[part 7 of 11: package /CANAnalyzer/CommunicationClusters]
AUTOSAR XML (schema 00051)
package /CANAnalyzer/CommunicationClusters  (continued)
  can cluster CAN_FD_IPB_41  (continued)
    can physical channel Channel  (continued)
      frame StatusDiagnosticFBD_HL: id 0x286, frame-length=32, can-addressing-mode=STANDARD, can-frame-rx-behavior=CAN-FD, can-frame-tx-behavior=CAN-FD
        pdu StatusDiagnosticFBD_HL: length=32, unused-bit-pattern=0
          signal StatusDiagnosticFBD_HL_BMWPartNumber0: start 0, 8 bit, little-endian, data-type-policy=OVERRIDE, base-type=uint8, compu {phys=raw}, range phys 0..255
          signal StatusDiagnosticFBD_HL_BMWPartNumber1: start 8, 8 bit, little-endian, data-type-policy=OVERRIDE, base-type=uint8, compu {phys=raw}, range phys 0..255
          signal StatusDiagnosticFBD_HL_BMWPartNumber2: start 16, 8 bit, little-endian, data-type-policy=OVERRIDE, base-type=uint8, compu {phys=raw}, range phys 0..255
          signal StatusDiagnosticFBD_HL_BMWPartNumber3: start 24, 8 bit, little-endian, data-type-policy=OVERRIDE, base-type=uint8, compu {phys=raw}, range phys 0..255
          signal StatusDiagnosticFBD_HL_BMWPartNumber4: start 32, 8 bit, little-endian, data-type-policy=OVERRIDE, base-type=uint8, compu {phys=raw}, range phys 0..255
          signal StatusDiagnosticFBD_HL_BMWPartNumber5: start 40, 8 bit, little-endian, data-type-policy=OVERRIDE, base-type=uint8, compu {phys=raw}, range phys 0..255
          signal StatusDiagnosticFBD_HL_BMWPartNumber6: start 48, 8 bit, little-endian, data-type-policy=OVERRIDE, base-type=uint8, compu {phys=raw}, range phys 0..255
          signal StatusDiagnosticFBD_HL_BMWPartNumberAI: start 56, 8 bit, little-endian, data-type-policy=OVERRIDE, base-type=uint8, compu {phys=raw}, range phys 0..255
          signal StatusDiagnosticFBD_HL_HWELMain: start 64, 8 bit, little-endian, data-type-policy=OVERRIDE, base-type=uint8, compu {phys=raw}, range phys 0..252
          signal StatusDiagnosticFBD_HL_HWELMinor: start 72, 8 bit, little-endian, data-type-policy=OVERRIDE, base-type=uint8, compu {phys=raw}, range phys 0..252
          signal StatusDiagnosticFBD_HL_HWELPatch: start 80, 8 bit, little-endian, data-type-policy=OVERRIDE, base-type=uint8, compu {phys=raw}, range phys 0..252
          signal StatusDiagnosticFBD_HL_BLESWFKMain: start 88, 8 bit, little-endian, data-type-policy=OVERRIDE, base-type=uint8, compu {phys=raw}, range phys 0..252
          signal StatusDiagnosticFBD_HL_BLESWFKMinor: start 96, 8 bit, little-endian, data-type-policy=OVERRIDE, base-type=uint8, compu {phys=raw}, range phys 0..252
          signal StatusDiagnosticFBD_HL_BLESWFKPatch: start 104, 8 bit, little-endian, data-type-policy=OVERRIDE, base-type=uint8, compu {phys=raw}, range phys 0..252
          signal StatusDiagnosticFBD_HL_UWBSWFKMain: start 112, 8 bit, little-endian, data-type-policy=OVERRIDE, base-type=uint8, compu {phys=raw}, range phys 0..252
          signal StatusDiagnosticFBD_HL_UWBSWFKMinor: start 120, 8 bit, little-endian, data-type-policy=OVERRIDE, base-type=uint8, compu {phys=raw}, range phys 0..252
          signal StatusDiagnosticFBD_HL_UWBSWFKPatch: start 128, 8 bit, little-endian, data-type-policy=OVERRIDE, base-type=uint8, compu {phys=raw}, range phys 0..252
          signal StatusDiagnosticFBD_HL_BootloaderSWFKMain: start 136, 8 bit, little-endian, data-type-policy=OVERRIDE, base-type=uint8, compu {phys=raw}, range phys 0..252
          signal StatusDiagnosticFBD_HL_BootloaderSWFKMinor: start 144, 8 bit, little-endian, data-type-policy=OVERRIDE, base-type=uint8, compu {phys=raw}, range phys 0..252
          signal StatusDiagnosticFBD_HL_BootloaderSWFKPatch: start 152, 8 bit, little-endian, data-type-policy=OVERRIDE, base-type=uint8, compu {phys=raw}, range phys 0..252
          signal StatusDiagnosticFBD_HL_ProductionDate: start 160, 64 bit, little-endian, data-type-policy=OVERRIDE, base-type=uint64, compu {phys=raw}, range phys 0..18446744073709551612
          signal StatusDiagnosticFBD_HL_SerialNumber: start 224, 32 bit, little-endian, data-type-policy=OVERRIDE, base-type=uint32, compu {phys=raw}, range phys 0..4294967292
      frame StatusDiagnosticFBD_HM: id 0x281, frame-length=32, can-addressing-mode=STANDARD, can-frame-rx-behavior=CAN-FD, can-frame-tx-behavior=CAN-FD
        pdu StatusDiagnosticFBD_HM: length=32, unused-bit-pattern=0
          signal StatusDiagnosticFBD_HM_BMWPartNumber0: start 0, 8 bit, little-endian, data-type-policy=OVERRIDE, base-type=uint8, compu {phys=raw}, range phys 0..255
          signal StatusDiagnosticFBD_HM_BMWPartNumber1: start 8, 8 bit, little-endian, data-type-policy=OVERRIDE, base-type=uint8, compu {phys=raw}, range phys 0..255
          signal StatusDiagnosticFBD_HM_BMWPartNumber2: start 16, 8 bit, little-endian, data-type-policy=OVERRIDE, base-type=uint8, compu {phys=raw}, range phys 0..255
          signal StatusDiagnosticFBD_HM_BMWPartNumber3: start 24, 8 bit, little-endian, data-type-policy=OVERRIDE, base-type=uint8, compu {phys=raw}, range phys 0..255
          signal StatusDiagnosticFBD_HM_BMWPartNumber4: start 32, 8 bit, little-endian, data-type-policy=OVERRIDE, base-type=uint8, compu {phys=raw}, range phys 0..255
          signal StatusDiagnosticFBD_HM_BMWPartNumber5: start 40, 8 bit, little-endian, data-type-policy=OVERRIDE, base-type=uint8, compu {phys=raw}, range phys 0..255
          signal StatusDiagnosticFBD_HM_BMWPartNumber6: start 48, 8 bit, little-endian, data-type-policy=OVERRIDE, base-type=uint8, compu {phys=raw}, range phys 0..255
          signal StatusDiagnosticFBD_HM_BMWPartNumberAI: start 56, 8 bit, little-endian, data-type-policy=OVERRIDE, base-type=uint8, compu {phys=raw}, range phys 0..255
          signal StatusDiagnosticFBD_HM_HWELMain: start 64, 8 bit, little-endian, data-type-policy=OVERRIDE, base-type=uint8, compu {phys=raw}, range phys 0..252
          signal StatusDiagnosticFBD_HM_HWELMinor: start 72, 8 bit, little-endian, data-type-policy=OVERRIDE, base-type=uint8, compu {phys=raw}, range phys 0..252
          signal StatusDiagnosticFBD_HM_HWELPatch: start 80, 8 bit, little-endian, data-type-policy=OVERRIDE, base-type=uint8, compu {phys=raw}, range phys 0..252
          signal StatusDiagnosticFBD_HM_BLESWFKMain: start 88, 8 bit, little-endian, data-type-policy=OVERRIDE, base-type=uint8, compu {phys=raw}, range phys 0..252
          signal StatusDiagnosticFBD_HM_BLESWFKMinor: start 96, 8 bit, little-endian, data-type-policy=OVERRIDE, base-type=uint8, compu {phys=raw}, range phys 0..252
          signal StatusDiagnosticFBD_HM_BLESWFKPatch: start 104, 8 bit, little-endian, data-type-policy=OVERRIDE, base-type=uint8, compu {phys=raw}, range phys 0..252
          signal StatusDiagnosticFBD_HM_UWBSWFKMain: start 112, 8 bit, little-endian, data-type-policy=OVERRIDE, base-type=uint8, compu {phys=raw}, range phys 0..252
          signal StatusDiagnosticFBD_HM_UWBSWFKMinor: start 120, 8 bit, little-endian, data-type-policy=OVERRIDE, base-type=uint8, compu {phys=raw}, range phys 0..252
          signal StatusDiagnosticFBD_HM_UWBSWFKPatch: start 128, 8 bit, little-endian, data-type-policy=OVERRIDE, base-type=uint8, compu {phys=raw}, range phys 0..252
          signal StatusDiagnosticFBD_HM_BootloaderSWFKMain: start 136, 8 bit, little-endian, data-type-policy=OVERRIDE, base-type=uint8, compu {phys=raw}, range phys 0..252
          signal StatusDiagnosticFBD_HM_BootloaderSWFKMinor: start 144, 8 bit, little-endian, data-type-policy=OVERRIDE, base-type=uint8, compu {phys=raw}, range phys 0..252
          signal StatusDiagnosticFBD_HM_BootloaderSWFKPatch: start 152, 8 bit, little-endian, data-type-policy=OVERRIDE, base-type=uint8, compu {phys=raw}, range phys 0..252
          signal StatusDiagnosticFBD_HM_ProductionDate: start 160, 64 bit, little-endian, data-type-policy=OVERRIDE, base-type=uint64, compu {phys=raw}, range phys 0..18446744073709551612
          signal StatusDiagnosticFBD_HM_SerialNumber: start 224, 32 bit, little-endian, data-type-policy=OVERRIDE, base-type=uint32, compu {phys=raw}, range phys 0..4294967292
      frame StatusDiagnosticFBD_HR: id 0x287, frame-length=32, can-addressing-mode=STANDARD, can-frame-rx-behavior=CAN-FD, can-frame-tx-behavior=CAN-FD
        pdu StatusDiagnosticFBD_HR: length=32, unused-bit-pattern=0
          signal StatusDiagnosticFBD_HR_BMWPartNumber0: start 0, 8 bit, little-endian, data-type-policy=OVERRIDE, base-type=uint8, compu {phys=raw}, range phys 0..255
          signal StatusDiagnosticFBD_HR_BMWPartNumber1: start 8, 8 bit, little-endian, data-type-policy=OVERRIDE, base-type=uint8, compu {phys=raw}, range phys 0..255
          signal StatusDiagnosticFBD_HR_BMWPartNumber2: start 16, 8 bit, little-endian, data-type-policy=OVERRIDE, base-type=uint8, compu {phys=raw}, range phys 0..255
          signal StatusDiagnosticFBD_HR_BMWPartNumber3: start 24, 8 bit, little-endian, data-type-policy=OVERRIDE, base-type=uint8, compu {phys=raw}, range phys 0..255
          signal StatusDiagnosticFBD_HR_BMWPartNumber4: start 32, 8 bit, little-endian, data-type-policy=OVERRIDE, base-type=uint8, compu {phys=raw}, range phys 0..255
          signal StatusDiagnosticFBD_HR_BMWPartNumber5: start 40, 8 bit, little-endian, data-type-policy=OVERRIDE, base-type=uint8, compu {phys=raw}, range phys 0..255
          signal StatusDiagnosticFBD_HR_BMWPartNumber6: start 48, 8 bit, little-endian, data-type-policy=OVERRIDE, base-type=uint8, compu {phys=raw}, range phys 0..255
          signal StatusDiagnosticFBD_HR_BMWPartNumberAI: start 56, 8 bit, little-endian, data-type-policy=OVERRIDE, base-type=uint8, compu {phys=raw}, range phys 0..255
          signal StatusDiagnosticFBD_HR_HWELMain: start 64, 8 bit, little-endian, data-type-policy=OVERRIDE, base-type=uint8, compu {phys=raw}, range phys 0..252
          signal StatusDiagnosticFBD_HR_HWELMinor: start 72, 8 bit, little-endian, data-type-policy=OVERRIDE, base-type=uint8, compu {phys=raw}, range phys 0..252
          signal StatusDiagnosticFBD_HR_HWELPatch: start 80, 8 bit, little-endian, data-type-policy=OVERRIDE, base-type=uint8, compu {phys=raw}, range phys 0..252
          signal StatusDiagnosticFBD_HR_BLESWFKMain: start 88, 8 bit, little-endian, data-type-policy=OVERRIDE, base-type=uint8, compu {phys=raw}, range phys 0..252
          signal StatusDiagnosticFBD_HR_BLESWFKMinor: start 96, 8 bit, little-endian, data-type-policy=OVERRIDE, base-type=uint8, compu {phys=raw}, range phys 0..252
          signal StatusDiagnosticFBD_HR_BLESWFKPatch: start 104, 8 bit, little-endian, data-type-policy=OVERRIDE, base-type=uint8, compu {phys=raw}, range phys 0..252
          signal StatusDiagnosticFBD_HR_UWBSWFKMain: start 112, 8 bit, little-endian, data-type-policy=OVERRIDE, base-type=uint8, compu {phys=raw}, range phys 0..252
          signal StatusDiagnosticFBD_HR_UWBSWFKMinor: start 120, 8 bit, little-endian, data-type-policy=OVERRIDE, base-type=uint8, compu {phys=raw}, range phys 0..252
          signal StatusDiagnosticFBD_HR_UWBSWFKPatch: start 128, 8 bit, little-endian, data-type-policy=OVERRIDE, base-type=uint8, compu {phys=raw}, range phys 0..252
          signal StatusDiagnosticFBD_HR_BootloaderSWFKMain: start 136, 8 bit, little-endian, data-type-policy=OVERRIDE, base-type=uint8, compu {phys=raw}, range phys 0..252
          signal StatusDiagnosticFBD_HR_BootloaderSWFKMinor: start 144, 8 bit, little-endian, data-type-policy=OVERRIDE, base-type=uint8, compu {phys=raw}, range phys 0..252
          signal StatusDiagnosticFBD_HR_BootloaderSWFKPatch: start 152, 8 bit, little-endian, data-type-policy=OVERRIDE, base-type=uint8, compu {phys=raw}, range phys 0..252
          signal StatusDiagnosticFBD_HR_ProductionDate: start 160, 64 bit, little-endian, data-type-policy=OVERRIDE, base-type=uint64, compu {phys=raw}, range phys 0..18446744073709551612
          signal StatusDiagnosticFBD_HR_SerialNumber: start 224, 32 bit, little-endian, data-type-policy=OVERRIDE, base-type=uint32, compu {phys=raw}, range phys 0..4294967292
      frame StatusDiagnosticFBD_Miko: id 0x282, frame-length=32, can-addressing-mode=STANDARD, can-frame-rx-behavior=CAN-FD, can-frame-tx-behavior=CAN-FD
        pdu StatusDiagnosticFBD_Miko: length=32, unused-bit-pattern=0
          signal StatusDiagnosticFBD_Miko_BMWPartNumber0: start 0, 8 bit, little-endian, data-type-policy=OVERRIDE, base-type=uint8, compu {phys=raw}, range phys 0..255
          signal StatusDiagnosticFBD_Miko_BMWPartNumber1: start 8, 8 bit, little-endian, data-type-policy=OVERRIDE, base-type=uint8, compu {phys=raw}, range phys 0..255
          signal StatusDiagnosticFBD_Miko_BMWPartNumber2: start 16, 8 bit, little-endian, data-type-policy=OVERRIDE, base-type=uint8, compu {phys=raw}, range phys 0..255
          signal StatusDiagnosticFBD_Miko_BMWPartNumber3: start 24, 8 bit, little-endian, data-type-policy=OVERRIDE, base-type=uint8, compu {phys=raw}, range phys 0..255
          signal StatusDiagnosticFBD_Miko_BMWPartNumber4: start 32, 8 bit, little-endian, data-type-policy=OVERRIDE, base-type=uint8, compu {phys=raw}, range phys 0..255
          signal StatusDiagnosticFBD_Miko_BMWPartNumber5: start 40, 8 bit, little-endian, data-type-policy=OVERRIDE, base-type=uint8, compu {phys=raw}, range phys 0..255
          signal StatusDiagnosticFBD_Miko_BMWPartNumber6: start 48, 8 bit, little-endian, data-type-policy=OVERRIDE, base-type=uint8, compu {phys=raw}, range phys 0..255
          signal StatusDiagnosticFBD_Miko_BMWPartNumberAI: start 56, 8 bit, little-endian, data-type-policy=OVERRIDE, base-type=uint8, compu {phys=raw}, range phys 0..255
          signal StatusDiagnosticFBD_Miko_HWELMain: start 64, 8 bit, little-endian, data-type-policy=OVERRIDE, base-type=uint8, compu {phys=raw}, range phys 0..252
          signal StatusDiagnosticFBD_Miko_HWELMinor: start 72, 8 bit, little-endian, data-type-policy=OVERRIDE, base-type=uint8, compu {phys=raw}, range phys 0..252
          signal StatusDiagnosticFBD_Miko_HWELPatch: start 80, 8 bit, little-endian, data-type-policy=OVERRIDE, base-type=uint8, compu {phys=raw}, range phys 0..252
          signal StatusDiagnosticFBD_Miko_BLESWFKMain: start 88, 8 bit, little-endian, data-type-policy=OVERRIDE, base-type=uint8, compu {phys=raw}, range phys 0..252
          signal StatusDiagnosticFBD_Miko_BLESWFKMinor: start 96, 8 bit, little-endian, data-type-policy=OVERRIDE, base-type=uint8, compu {phys=raw}, range phys 0..252
          signal StatusDiagnosticFBD_Miko_BLESWFKPatch: start 104, 8 bit, little-endian, data-type-policy=OVERRIDE, base-type=uint8, compu {phys=raw}, range phys 0..252
          signal StatusDiagnosticFBD_Miko_UWBSWFKMain: start 112, 8 bit, little-endian, data-type-policy=OVERRIDE, base-type=uint8, compu {phys=raw}, range phys 0..252
          signal StatusDiagnosticFBD_Miko_UWBSWFKMinor: start 120, 8 bit, little-endian, data-type-policy=OVERRIDE, base-type=uint8, compu {phys=raw}, range phys 0..252
          signal StatusDiagnosticFBD_Miko_UWBSWFKPatch: start 128, 8 bit, little-endian, data-type-policy=OVERRIDE, base-type=uint8, compu {phys=raw}, range phys 0..252
          signal StatusDiagnosticFBD_Miko_BootloaderSWFKMain: start 136, 8 bit, little-endian, data-type-policy=OVERRIDE, base-type=uint8, compu {phys=raw}, range phys 0..252
          signal StatusDiagnosticFBD_Miko_BootloaderSWFKMinor: start 144, 8 bit, little-endian, data-type-policy=OVERRIDE, base-type=uint8, compu {phys=raw}, range phys 0..252
          signal StatusDiagnosticFBD_Miko_BootloaderSWFKPatch: start 152, 8 bit, little-endian, data-type-policy=OVERRIDE, base-type=uint8, compu {phys=raw}, range phys 0..252
          signal StatusDiagnosticFBD_Miko_ProductionDate: start 160, 64 bit, little-endian, data-type-policy=OVERRIDE, base-type=uint64, compu {phys=raw}, range phys 0..18446744073709551612
          signal StatusDiagnosticFBD_Miko_SerialNumber: start 224, 32 bit, little-endian, data-type-policy=OVERRIDE, base-type=uint32, compu {phys=raw}, range phys 0..4294967292
      frame StatusDiagnosticFBD_MM: id 0x360, frame-length=32, can-addressing-mode=STANDARD, can-frame-rx-behavior=CAN-FD, can-frame-tx-behavior=CAN-FD
        pdu StatusDiagnosticFBD_MM: length=32, unused-bit-pattern=0
          signal StatusDiagnosticFBD_MM_BMWPartNumber0: start 0, 8 bit, little-endian, data-type-policy=OVERRIDE, base-type=uint8, compu {phys=raw}, range phys 0..255
          signal StatusDiagnosticFBD_MM_BMWPartNumber1: start 8, 8 bit, little-endian, data-type-policy=OVERRIDE, base-type=uint8, compu {phys=raw}, range phys 0..255
          signal StatusDiagnosticFBD_MM_BMWPartNumber2: start 16, 8 bit, little-endian, data-type-policy=OVERRIDE, base-type=uint8, compu {phys=raw}, range phys 0..255
          signal StatusDiagnosticFBD_MM_BMWPartNumber3: start 24, 8 bit, little-endian, data-type-policy=OVERRIDE, base-type=uint8, compu {phys=raw}, range phys 0..255
          signal StatusDiagnosticFBD_MM_BMWPartNumber4: start 32, 8 bit, little-endian, data-type-policy=OVERRIDE, base-type=uint8, compu {phys=raw}, range phys 0..255
          signal StatusDiagnosticFBD_MM_BMWPartNumber5: start 40, 8 bit, little-endian, data-type-policy=OVERRIDE, base-type=uint8, compu {phys=raw}, range phys 0..255
          signal StatusDiagnosticFBD_MM_BMWPartNumber6: start 48, 8 bit, little-endian, data-type-policy=OVERRIDE, base-type=uint8, compu {phys=raw}, range phys 0..255
          signal StatusDiagnosticFBD_MM_BMWPartNumberAI: start 56, 8 bit, little-endian, data-type-policy=OVERRIDE, base-type=uint8, compu {phys=raw}, range phys 0..255
          signal StatusDiagnosticFBD_MM_HWELMain: start 64, 8 bit, little-endian, data-type-policy=OVERRIDE, base-type=uint8, compu {phys=raw}, range phys 0..252
          signal StatusDiagnosticFBD_MM_HWELMinor: start 72, 8 bit, little-endian, data-type-policy=OVERRIDE, base-type=uint8, compu {phys=raw}, range phys 0..252
          signal StatusDiagnosticFBD_MM_HWELPatch: start 80, 8 bit, little-endian, data-type-policy=OVERRIDE, base-type=uint8, compu {phys=raw}, range phys 0..252
          signal StatusDiagnosticFBD_MM_BLESWFKMain: start 88, 8 bit, little-endian, data-type-policy=OVERRIDE, base-type=uint8, compu {phys=raw}, range phys 0..252
          signal StatusDiagnosticFBD_MM_BLESWFKMinor: start 96, 8 bit, little-endian, data-type-policy=OVERRIDE, base-type=uint8, compu {phys=raw}, range phys 0..252
          signal StatusDiagnosticFBD_MM_BLESWFKPatch: start 104, 8 bit, little-endian, data-type-policy=OVERRIDE, base-type=uint8, compu {phys=raw}, range phys 0..252
          signal StatusDiagnosticFBD_MM_UWBSWFKMain: start 112, 8 bit, little-endian, data-type-policy=OVERRIDE, base-type=uint8, compu {phys=raw}, range phys 0..252
          signal StatusDiagnosticFBD_MM_UWBSWFKMinor: start 120, 8 bit, little-endian, data-type-policy=OVERRIDE, base-type=uint8, compu {phys=raw}, range phys 0..252
          signal StatusDiagnosticFBD_MM_UWBSWFKPatch: start 128, 8 bit, little-endian, data-type-policy=OVERRIDE, base-type=uint8, compu {phys=raw}, range phys 0..252
          signal StatusDiagnosticFBD_MM_BootloaderSWFKMain: start 136, 8 bit, little-endian, data-type-policy=OVERRIDE, base-type=uint8, compu {phys=raw}, range phys 0..252
          signal StatusDiagnosticFBD_MM_BootloaderSWFKMinor: start 144, 8 bit, little-endian, data-type-policy=OVERRIDE, base-type=uint8, compu {phys=raw}, range phys 0..252
          signal StatusDiagnosticFBD_MM_BootloaderSWFKPatch: start 152, 8 bit, little-endian, data-type-policy=OVERRIDE, base-type=uint8, compu {phys=raw}, range phys 0..252
          signal StatusDiagnosticFBD_MM_ProductionDate: start 160, 64 bit, little-endian, data-type-policy=OVERRIDE, base-type=uint64, compu {phys=raw}, range phys 0..18446744073709551612
          signal StatusDiagnosticFBD_MM_SerialNumber: start 224, 32 bit, little-endian, data-type-policy=OVERRIDE, base-type=uint32, compu {phys=raw}, range phys 0..4294967292
      frame StatusDiagnosticFBD_Trunk: id 0x283, frame-length=32, can-addressing-mode=STANDARD, can-frame-rx-behavior=CAN-FD, can-frame-tx-behavior=CAN-FD
        pdu StatusDiagnosticFBD_Trunk: length=32, unused-bit-pattern=0
          signal StatusDiagnosticFBD_Trunk_BMWPartNumber0: start 0, 8 bit, little-endian, data-type-policy=OVERRIDE, base-type=uint8, compu {phys=raw}, range phys 0..255
          signal StatusDiagnosticFBD_Trunk_BMWPartNumber1: start 8, 8 bit, little-endian, data-type-policy=OVERRIDE, base-type=uint8, compu {phys=raw}, range phys 0..255
          signal StatusDiagnosticFBD_Trunk_BMWPartNumber2: start 16, 8 bit, little-endian, data-type-policy=OVERRIDE, base-type=uint8, compu {phys=raw}, range phys 0..255
          signal StatusDiagnosticFBD_Trunk_BMWPartNumber3: start 24, 8 bit, little-endian, data-type-policy=OVERRIDE, base-type=uint8, compu {phys=raw}, range phys 0..255
          signal StatusDiagnosticFBD_Trunk_BMWPartNumber4: start 32, 8 bit, little-endian, data-type-policy=OVERRIDE, base-type=uint8, compu {phys=raw}, range phys 0..255
          signal StatusDiagnosticFBD_Trunk_BMWPartNumber5: start 40, 8 bit, little-endian, data-type-policy=OVERRIDE, base-type=uint8, compu {phys=raw}, range phys 0..255
          signal StatusDiagnosticFBD_Trunk_BMWPartNumber6: start 48, 8 bit, little-endian, data-type-policy=OVERRIDE, base-type=uint8, compu {phys=raw}, range phys 0..255
          signal StatusDiagnosticFBD_Trunk_BMWPartNumberAI: start 56, 8 bit, little-endian, data-type-policy=OVERRIDE, base-type=uint8, compu {phys=raw}, range phys 0..255
          signal StatusDiagnosticFBD_Trunk_HWELMain: start 64, 8 bit, little-endian, data-type-policy=OVERRIDE, base-type=uint8, compu {phys=raw}, range phys 0..252
          signal StatusDiagnosticFBD_Trunk_HWELMinor: start 72, 8 bit, little-endian, data-type-policy=OVERRIDE, base-type=uint8, compu {phys=raw}, range phys 0..252
          signal StatusDiagnosticFBD_Trunk_HWELPatch: start 80, 8 bit, little-endian, data-type-policy=OVERRIDE, base-type=uint8, compu {phys=raw}, range phys 0..252
          signal StatusDiagnosticFBD_Trunk_BLESWFKMain: start 88, 8 bit, little-endian, data-type-policy=OVERRIDE, base-type=uint8, compu {phys=raw}, range phys 0..252
          signal StatusDiagnosticFBD_Trunk_BLESWFKMinor: start 96, 8 bit, little-endian, data-type-policy=OVERRIDE, base-type=uint8, compu {phys=raw}, range phys 0..252
          signal StatusDiagnosticFBD_Trunk_BLESWFKPatch: start 104, 8 bit, little-endian, data-type-policy=OVERRIDE, base-type=uint8, compu {phys=raw}, range phys 0..252
          signal StatusDiagnosticFBD_Trunk_UWBSWFKMain: start 112, 8 bit, little-endian, data-type-policy=OVERRIDE, base-type=uint8, compu {phys=raw}, range phys 0..252
          signal StatusDiagnosticFBD_Trunk_UWBSWFKMinor: start 120, 8 bit, little-endian, data-type-policy=OVERRIDE, base-type=uint8, compu {phys=raw}, range phys 0..252
          signal StatusDiagnosticFBD_Trunk_UWBSWFKPatch: start 128, 8 bit, little-endian, data-type-policy=OVERRIDE, base-type=uint8, compu {phys=raw}, range phys 0..252
          signal StatusDiagnosticFBD_Trunk_BootloaderSWFKMain: start 136, 8 bit, little-endian, data-type-policy=OVERRIDE, base-type=uint8, compu {phys=raw}, range phys 0..252
          signal StatusDiagnosticFBD_Trunk_BootloaderSWFKMinor: start 144, 8 bit, little-endian, data-type-policy=OVERRIDE, base-type=uint8, compu {phys=raw}, range phys 0..252
          signal StatusDiagnosticFBD_Trunk_BootloaderSWFKPatch: start 152, 8 bit, little-endian, data-type-policy=OVERRIDE, base-type=uint8, compu {phys=raw}, range phys 0..252
          signal StatusDiagnosticFBD_Trunk_ProductionDate: start 160, 64 bit, little-endian, data-type-policy=OVERRIDE, base-type=uint64, compu {phys=raw}, range phys 0..18446744073709551612
          signal StatusDiagnosticFBD_Trunk_SerialNumber: start 224, 32 bit, little-endian, data-type-policy=OVERRIDE, base-type=uint32, compu {phys=raw}, range phys 0..4294967292
      frame StatusDiagnosticFBD_VL: id 0x284, frame-length=32, can-addressing-mode=STANDARD, can-frame-rx-behavior=CAN-FD, can-frame-tx-behavior=CAN-FD
        pdu StatusDiagnosticFBD_VL: length=32, unused-bit-pattern=0
          signal StatusDiagnosticFBD_VL_BMWPartNumber0: start 0, 8 bit, little-endian, data-type-policy=OVERRIDE, base-type=uint8, compu {phys=raw}, range phys 0..255
          signal StatusDiagnosticFBD_VL_BMWPartNumber1: start 8, 8 bit, little-endian, data-type-policy=OVERRIDE, base-type=uint8, compu {phys=raw}, range phys 0..255
          signal StatusDiagnosticFBD_VL_BMWPartNumber2: start 16, 8 bit, little-endian, data-type-policy=OVERRIDE, base-type=uint8, compu {phys=raw}, range phys 0..255
          signal StatusDiagnosticFBD_VL_BMWPartNumber3: start 24, 8 bit, little-endian, data-type-policy=OVERRIDE, base-type=uint8, compu {phys=raw}, range phys 0..255
          signal StatusDiagnosticFBD_VL_BMWPartNumber4: start 32, 8 bit, little-endian, data-type-policy=OVERRIDE, base-type=uint8, compu {phys=raw}, range phys 0..255
          signal StatusDiagnosticFBD_VL_BMWPartNumber5: start 40, 8 bit, little-endian, data-type-policy=OVERRIDE, base-type=uint8, compu {phys=raw}, range phys 0..255
          signal StatusDiagnosticFBD_VL_BMWPartNumber6: start 48, 8 bit, little-endian, data-type-policy=OVERRIDE, base-type=uint8, compu {phys=raw}, range phys 0..255
          signal StatusDiagnosticFBD_VL_BMWPartNumberAI: start 56, 8 bit, little-endian, data-type-policy=OVERRIDE, base-type=uint8, compu {phys=raw}, range phys 0..255
          signal StatusDiagnosticFBD_VL_HWELMain: start 64, 8 bit, little-endian, data-type-policy=OVERRIDE, base-type=uint8, compu {phys=raw}, range phys 0..252
          signal StatusDiagnosticFBD_VL_HWELMinor: start 72, 8 bit, little-endian, data-type-policy=OVERRIDE, base-type=uint8, compu {phys=raw}, range phys 0..252
          signal StatusDiagnosticFBD_VL_HWELPatch: start 80, 8 bit, little-endian, data-type-policy=OVERRIDE, base-type=uint8, compu {phys=raw}, range phys 0..252
          signal StatusDiagnosticFBD_VL_BLESWFKMain: start 88, 8 bit, little-endian, data-type-policy=OVERRIDE, base-type=uint8, compu {phys=raw}, range phys 0..252
          signal StatusDiagnosticFBD_VL_BLESWFKMinor: start 96, 8 bit, little-endian, data-type-policy=OVERRIDE, base-type=uint8, compu {phys=raw}, range phys 0..252
          signal StatusDiagnosticFBD_VL_BLESWFKPatch: start 104, 8 bit, little-endian, data-type-policy=OVERRIDE, base-type=uint8, compu {phys=raw}, range phys 0..252
          signal StatusDiagnosticFBD_VL_UWBSWFKMain: start 112, 8 bit, little-endian, data-type-policy=OVERRIDE, base-type=uint8, compu {phys=raw}, range phys 0..252
          signal StatusDiagnosticFBD_VL_UWBSWFKMinor: start 120, 8 bit, little-endian, data-type-policy=OVERRIDE, base-type=uint8, compu {phys=raw}, range phys 0..252
          signal StatusDiagnosticFBD_VL_UWBSWFKPatch: start 128, 8 bit, little-endian, data-type-policy=OVERRIDE, base-type=uint8, compu {phys=raw}, range phys 0..252
          signal StatusDiagnosticFBD_VL_BootloaderSWFKMain: start 136, 8 bit, little-endian, data-type-policy=OVERRIDE, base-type=uint8, compu {phys=raw}, range phys 0..252
          signal StatusDiagnosticFBD_VL_BootloaderSWFKMinor: start 144, 8 bit, little-endian, data-type-policy=OVERRIDE, base-type=uint8, compu {phys=raw}, range phys 0..252
          signal StatusDiagnosticFBD_VL_BootloaderSWFKPatch: start 152, 8 bit, little-endian, data-type-policy=OVERRIDE, base-type=uint8, compu {phys=raw}, range phys 0..252
          signal StatusDiagnosticFBD_VL_ProductionDate: start 160, 64 bit, little-endian, data-type-policy=OVERRIDE, base-type=uint64, compu {phys=raw}, range phys 0..18446744073709551612
          signal StatusDiagnosticFBD_VL_SerialNumber: start 224, 32 bit, little-endian, data-type-policy=OVERRIDE, base-type=uint32, compu {phys=raw}, range phys 0..4294967292
      frame StatusDiagnosticFBD_VM: id 0x280, frame-length=32, can-addressing-mode=STANDARD, can-frame-rx-behavior=CAN-FD, can-frame-tx-behavior=CAN-FD
        pdu StatusDiagnosticFBD_VM: length=32, unused-bit-pattern=0
          signal StatusDiagnosticFBD_VM_BMWPartNumber0: start 0, 8 bit, little-endian, data-type-policy=OVERRIDE, base-type=uint8, compu {phys=raw}, range phys 0..255
          signal StatusDiagnosticFBD_VM_BMWPartNumber1: start 8, 8 bit, little-endian, data-type-policy=OVERRIDE, base-type=uint8, compu {phys=raw}, range phys 0..255
          signal StatusDiagnosticFBD_VM_BMWPartNumber2: start 16, 8 bit, little-endian, data-type-policy=OVERRIDE, base-type=uint8, compu {phys=raw}, range phys 0..255
          signal StatusDiagnosticFBD_VM_BMWPartNumber3: start 24, 8 bit, little-endian, data-type-policy=OVERRIDE, base-type=uint8, compu {phys=raw}, range phys 0..255
          signal StatusDiagnosticFBD_VM_BMWPartNumber4: start 32, 8 bit, little-endian, data-type-policy=OVERRIDE, base-type=uint8, compu {phys=raw}, range phys 0..255
          signal StatusDiagnosticFBD_VM_BMWPartNumber5: start 40, 8 bit, little-endian, data-type-policy=OVERRIDE, base-type=uint8, compu {phys=raw}, range phys 0..255
          signal StatusDiagnosticFBD_VM_BMWPartNumber6: start 48, 8 bit, little-endian, data-type-policy=OVERRIDE, base-type=uint8, compu {phys=raw}, range phys 0..255
          signal StatusDiagnosticFBD_VM_BMWPartNumberAI: start 56, 8 bit, little-endian, data-type-policy=OVERRIDE, base-type=uint8, compu {phys=raw}, range phys 0..255
          signal StatusDiagnosticFBD_VM_HWELMain: start 64, 8 bit, little-endian, data-type-policy=OVERRIDE, base-type=uint8, compu {phys=raw}, range phys 0..252
          signal StatusDiagnosticFBD_VM_HWELMinor: start 72, 8 bit, little-endian, data-type-policy=OVERRIDE, base-type=uint8, compu {phys=raw}, range phys 0..252
          signal StatusDiagnosticFBD_VM_HWELPatch: start 80, 8 bit, little-endian, data-type-policy=OVERRIDE, base-type=uint8, compu {phys=raw}, range phys 0..252
          signal StatusDiagnosticFBD_VM_BLESWFKMain: start 88, 8 bit, little-endian, data-type-policy=OVERRIDE, base-type=uint8, compu {phys=raw}, range phys 0..252
          signal StatusDiagnosticFBD_VM_BLESWFKMinor: start 96, 8 bit, little-endian, data-type-policy=OVERRIDE, base-type=uint8, compu {phys=raw}, range phys 0..252
          signal StatusDiagnosticFBD_VM_BLESWFKPatch: start 104, 8 bit, little-endian, data-type-policy=OVERRIDE, base-type=uint8, compu {phys=raw}, range phys 0..252
          signal StatusDiagnosticFBD_VM_UWBSWFKMain: start 112, 8 bit, little-endian, data-type-policy=OVERRIDE, base-type=uint8, compu {phys=raw}, range phys 0..252
          signal StatusDiagnosticFBD_VM_UWBSWFKMinor: start 120, 8 bit, little-endian, data-type-policy=OVERRIDE, base-type=uint8, compu {phys=raw}, range phys 0..252
          signal StatusDiagnosticFBD_VM_UWBSWFKPatch: start 128, 8 bit, little-endian, data-type-policy=OVERRIDE, base-type=uint8, compu {phys=raw}, range phys 0..252
          signal StatusDiagnosticFBD_VM_BootloaderSWFKMain: start 136, 8 bit, little-endian, data-type-policy=OVERRIDE, base-type=uint8, compu {phys=raw}, range phys 0..252
          signal StatusDiagnosticFBD_VM_BootloaderSWFKMinor: start 144, 8 bit, little-endian, data-type-policy=OVERRIDE, base-type=uint8, compu {phys=raw}, range phys 0..252
          signal StatusDiagnosticFBD_VM_BootloaderSWFKPatch: start 152, 8 bit, little-endian, data-type-policy=OVERRIDE, base-type=uint8, compu {phys=raw}, range phys 0..252
          signal StatusDiagnosticFBD_VM_ProductionDate: start 160, 64 bit, little-endian, data-type-policy=OVERRIDE, base-type=uint64, compu {phys=raw}, range phys 0..18446744073709551612
          signal StatusDiagnosticFBD_VM_SerialNumber: start 224, 32 bit, little-endian, data-type-policy=OVERRIDE, base-type=uint32, compu {phys=raw}, range phys 0..4294967292
      frame StatusDiagnosticFBD_VR: id 0x285, frame-length=32, can-addressing-mode=STANDARD, can-frame-rx-behavior=CAN-FD, can-frame-tx-behavior=CAN-FD
        pdu StatusDiagnosticFBD_VR: length=32, unused-bit-pattern=0
          signal StatusDiagnosticFBD_VR_BMWPartNumber0: start 0, 8 bit, little-endian, data-type-policy=OVERRIDE, base-type=uint8, compu {phys=raw}, range phys 0..255
          signal StatusDiagnosticFBD_VR_BMWPartNumber1: start 8, 8 bit, little-endian, data-type-policy=OVERRIDE, base-type=uint8, compu {phys=raw}, range phys 0..255
          signal StatusDiagnosticFBD_VR_BMWPartNumber2: start 16, 8 bit, little-endian, data-type-policy=OVERRIDE, base-type=uint8, compu {phys=raw}, range phys 0..255
          signal StatusDiagnosticFBD_VR_BMWPartNumber3: start 24, 8 bit, little-endian, data-type-policy=OVERRIDE, base-type=uint8, compu {phys=raw}, range phys 0..255
          signal StatusDiagnosticFBD_VR_BMWPartNumber4: start 32, 8 bit, little-endian, data-type-policy=OVERRIDE, base-type=uint8, compu {phys=raw}, range phys 0..255
          signal StatusDiagnosticFBD_VR_BMWPartNumber5: start 40, 8 bit, little-endian, data-type-policy=OVERRIDE, base-type=uint8, compu {phys=raw}, range phys 0..255
          signal StatusDiagnosticFBD_VR_BMWPartNumber6: start 48, 8 bit, little-endian, data-type-policy=OVERRIDE, base-type=uint8, compu {phys=raw}, range phys 0..255
          signal StatusDiagnosticFBD_VR_BMWPartNumberAI: start 56, 8 bit, little-endian, data-type-policy=OVERRIDE, base-type=uint8, compu {phys=raw}, range phys 0..255
          signal StatusDiagnosticFBD_VR_HWELMain: start 64, 8 bit, little-endian, data-type-policy=OVERRIDE, base-type=uint8, compu {phys=raw}, range phys 0..252
          signal StatusDiagnosticFBD_VR_HWELMinor: start 72, 8 bit, little-endian, data-type-policy=OVERRIDE, base-type=uint8, compu {phys=raw}, range phys 0..252
          signal StatusDiagnosticFBD_VR_HWELPatch: start 80, 8 bit, little-endian, data-type-policy=OVERRIDE, base-type=uint8, compu {phys=raw}, range phys 0..252
          signal StatusDiagnosticFBD_VR_BLESWFKMain: start 88, 8 bit, little-endian, data-type-policy=OVERRIDE, base-type=uint8, compu {phys=raw}, range phys 0..252
          signal StatusDiagnosticFBD_VR_BLESWFKMinor: start 96, 8 bit, little-endian, data-type-policy=OVERRIDE, base-type=uint8, compu {phys=raw}, range phys 0..252
          signal StatusDiagnosticFBD_VR_BLESWFKPatch: start 104, 8 bit, little-endian, data-type-policy=OVERRIDE, base-type=uint8, compu {phys=raw}, range phys 0..252
          signal StatusDiagnosticFBD_VR_UWBSWFKMain: start 112, 8 bit, little-endian, data-type-policy=OVERRIDE, base-type=uint8, compu {phys=raw}, range phys 0..252
          signal StatusDiagnosticFBD_VR_UWBSWFKMinor: start 120, 8 bit, little-endian, data-type-policy=OVERRIDE, base-type=uint8, compu {phys=raw}, range phys 0..252
          signal StatusDiagnosticFBD_VR_UWBSWFKPatch: start 128, 8 bit, little-endian, data-type-policy=OVERRIDE, base-type=uint8, compu {phys=raw}, range phys 0..252
          signal StatusDiagnosticFBD_VR_BootloaderSWFKMain: start 136, 8 bit, little-endian, data-type-policy=OVERRIDE, base-type=uint8, compu {phys=raw}, range phys 0..252
          signal StatusDiagnosticFBD_VR_BootloaderSWFKMinor: start 144, 8 bit, little-endian, data-type-policy=OVERRIDE, base-type=uint8, compu {phys=raw}, range phys 0..252
          signal StatusDiagnosticFBD_VR_BootloaderSWFKPatch: start 152, 8 bit, little-endian, data-type-policy=OVERRIDE, base-type=uint8, compu {phys=raw}, range phys 0..252
          signal StatusDiagnosticFBD_VR_ProductionDate: start 160, 64 bit, little-endian, data-type-policy=OVERRIDE, base-type=uint64, compu {phys=raw}, range phys 0..18446744073709551612
          signal StatusDiagnosticFBD_VR_SerialNumber: start 224, 32 bit, little-endian, data-type-policy=OVERRIDE, base-type=uint32, compu {phys=raw}, range phys 0..4294967292
      frame StatusFBD_HL: id 0x9C, frame-length=32, can-addressing-mode=STANDARD, can-frame-rx-behavior=CAN-FD, can-frame-tx-behavior=CAN-FD
        pdu StatusFBD_HL: length=32, unused-bit-pattern=0
          signal StatusFBD_HL_PowerMode: start 0, 8 bit, little-endian, data-type-policy=OVERRIDE, compu {phys=raw}
          signal StatusFBD_HL_ResetState: start 8, 8 bit, little-endian, data-type-policy=OVERRIDE, base-type=uint8, compu {phys=raw}, range phys 0..252
          signal StatusFBD_HL_ResetReason: start 16, 8 bit, little-endian, data-type-policy=OVERRIDE, base-type=uint8, compu {phys=raw}, range phys 0..252
          signal StatusFBD_HL_BLEStatus: start 24, 8 bit, little-endian, data-type-policy=OVERRIDE, compu {phys=raw}
          signal StatusFBD_HL_UWBStatus: start 32, 8 bit, little-endian, data-type-policy=OVERRIDE, compu {phys=raw}
          signal StatusFBD_HL_WakeUpReason: start 40, 8 bit, little-endian, data-type-policy=OVERRIDE, compu {phys=raw}
          signal StatusFBD_HL_IRKListIndexWakeUpTrigger: start 48, 8 bit, little-endian, data-type-policy=OVERRIDE, base-type=uint8, compu {phys=raw}, range phys 0..252
          signal StatusFBD_HL_Temperature: start 56, 8 bit, little-endian, data-type-policy=OVERRIDE, base-type=uint8, compu {phys=raw-100; unit °C}, range phys -100..150
          signal StatusFBD_HL_BLENumberOfBonding: start 64, 8 bit, little-endian, data-type-policy=OVERRIDE, base-type=uint8, compu {phys=raw}, range phys 0..252
          signal StatusFBD_HL_BLENumberActiveConnections: start 72, 8 bit, little-endian, data-type-policy=OVERRIDE, base-type=uint8, compu {phys=raw}, range phys 0..252
          signal StatusFBD_HL_BLEChipPowerOnResetCounter: start 80, 8 bit, little-endian, data-type-policy=OVERRIDE, base-type=uint8, compu {phys=raw}, range phys 0..252
          signal StatusFBD_HL_BLEChipSWResetCounter: start 88, 8 bit, little-endian, data-type-policy=OVERRIDE, base-type=uint8, compu {phys=raw}, range phys 0..252
          signal StatusFBD_HL_BLEChipWatchdogCounter: start 96, 8 bit, little-endian, data-type-policy=OVERRIDE, base-type=uint8, compu {phys=raw}, range phys 0..252
          signal StatusFBD_HL_BLEChipTemperaturePrewarningCounter: start 104, 8 bit, little-endian, data-type-policy=OVERRIDE, base-type=uint8, compu {phys=raw}, range phys 0..252
          signal StatusFBD_HL_BLEChipThermalShutdownCounter: start 112, 8 bit, little-endian, data-type-policy=OVERRIDE, base-type=uint8, compu {phys=raw}, range phys 0..252
          signal StatusFBD_HL_BLEChipErrorState: start 120, 8 bit, little-endian, data-type-policy=OVERRIDE, compu {phys=raw}
          signal StatusFBD_HL_UWBChipPowerOnResetCounter: start 128, 8 bit, little-endian, data-type-policy=OVERRIDE, base-type=uint8, compu {phys=raw}, range phys 0..252
          signal StatusFBD_HL_UWBChipSWResetCounter: start 136, 8 bit, little-endian, data-type-policy=OVERRIDE, base-type=uint8, compu {phys=raw}, range phys 0..252
          signal StatusFBD_HL_UWBChipWatchdogCounter: start 144, 8 bit, little-endian, data-type-policy=OVERRIDE, base-type=uint8, compu {phys=raw}, range phys 0..252
          signal StatusFBD_HL_UWBChipTemperaturePrewarningCounter: start 152, 8 bit, little-endian, data-type-policy=OVERRIDE, base-type=uint8, compu {phys=raw}, range phys 0..252
          signal StatusFBD_HL_UWBChipThermalShutdownCounter: start 160, 8 bit, little-endian, data-type-policy=OVERRIDE, base-type=uint8, compu {phys=raw}, range phys 0..252
          signal StatusFBD_HL_UWBChipErrorState: start 168, 8 bit, little-endian, data-type-policy=OVERRIDE, compu {phys=raw}
          signal StatusFBD_HL_ProgrammingCounter: start 176, 8 bit, little-endian, data-type-policy=OVERRIDE, base-type=uint8, compu {phys=raw}, range phys 0..252
          signal StatusFBD_HL_ProgrammingErrorCounter: start 184, 8 bit, little-endian, data-type-policy=OVERRIDE, base-type=uint8, compu {phys=raw}, range phys 0..252
          signal StatusFBD_HL_SPIHangupCounter: start 192, 8 bit, little-endian, data-type-policy=OVERRIDE, base-type=uint8, compu {phys=raw}, range phys 0..252
          signal StatusFBD_HL_SBCChipTemperaturePrewarningCounter: start 200, 8 bit, little-endian, data-type-policy=OVERRIDE, base-type=uint8, compu {phys=raw}, range phys 0..252
          signal StatusFBD_HL_SBCChipThermalShutdownCounter: start 208, 8 bit, little-endian, data-type-policy=OVERRIDE, base-type=uint8, compu {phys=raw}, range phys 0..252
          signal StatusFBD_HL_SBCErrorState: start 216, 8 bit, little-endian, data-type-policy=OVERRIDE, compu {phys=raw}
          signal StatusFBD_HL_OptionCode: start 224, 8 bit, little-endian, data-type-policy=OVERRIDE, compu {phys=raw}
          signal StatusFBD_HL_UWBCollisionCounter: start 232, 8 bit, little-endian, data-type-policy=OVERRIDE, base-type=uint8, compu {phys=raw}, range phys 0..252
          signal StatusFBD_HL_DebugInformation1: start 240, 8 bit, little-endian, data-type-policy=OVERRIDE, compu {phys=raw}
          signal StatusFBD_HL_DebugInformation2: start 248, 8 bit, little-endian, data-type-policy=OVERRIDE, compu {phys=raw}
      frame StatusFBD_HM: id 0x97, frame-length=32, can-addressing-mode=STANDARD, can-frame-rx-behavior=CAN-FD, can-frame-tx-behavior=CAN-FD
        pdu StatusFBD_HM: length=32, unused-bit-pattern=0
          signal StatusFBD_HM_PowerMode: start 0, 8 bit, little-endian, data-type-policy=OVERRIDE, compu {phys=raw}
          signal StatusFBD_HM_ResetState: start 8, 8 bit, little-endian, data-type-policy=OVERRIDE, base-type=uint8, compu {phys=raw}, range phys 0..252
          signal StatusFBD_HM_ResetReason: start 16, 8 bit, little-endian, data-type-policy=OVERRIDE, base-type=uint8, compu {phys=raw}, range phys 0..252
          signal StatusFBD_HM_BLEStatus: start 24, 8 bit, little-endian, data-type-policy=OVERRIDE, compu {phys=raw}
          signal StatusFBD_HM_UWBStatus: start 32, 8 bit, little-endian, data-type-policy=OVERRIDE, compu {phys=raw}
          signal StatusFBD_HM_WakeUpReason: start 40, 8 bit, little-endian, data-type-policy=OVERRIDE, compu {phys=raw}
          signal StatusFBD_HM_IRKListIndexWakeUpTrigger: start 48, 8 bit, little-endian, data-type-policy=OVERRIDE, base-type=uint8, compu {phys=raw}, range phys 0..252
          signal StatusFBD_HM_Temperature: start 56, 8 bit, little-endian, data-type-policy=OVERRIDE, base-type=uint8, compu {phys=raw-100; unit °C}, range phys -100..150
          signal StatusFBD_HM_BLENumberOfBonding: start 64, 8 bit, little-endian, data-type-policy=OVERRIDE, base-type=uint8, compu {phys=raw}, range phys 0..252
          signal StatusFBD_HM_BLENumberActiveConnections: start 72, 8 bit, little-endian, data-type-policy=OVERRIDE, base-type=uint8, compu {phys=raw}, range phys 0..252
          signal StatusFBD_HM_BLEChipPowerOnResetCounter: start 80, 8 bit, little-endian, data-type-policy=OVERRIDE, base-type=uint8, compu {phys=raw}, range phys 0..252
          signal StatusFBD_HM_BLEChipSWResetCounter: start 88, 8 bit, little-endian, data-type-policy=OVERRIDE, base-type=uint8, compu {phys=raw}, range phys 0..252
          signal StatusFBD_HM_BLEChipWatchdogCounter: start 96, 8 bit, little-endian, data-type-policy=OVERRIDE, base-type=uint8, compu {phys=raw}, range phys 0..252
          signal StatusFBD_HM_BLEChipTemperaturePrewarningCounter: start 104, 8 bit, little-endian, data-type-policy=OVERRIDE, base-type=uint8, compu {phys=raw}, range phys 0..252
          signal StatusFBD_HM_BLEChipThermalShutdownCounter: start 112, 8 bit, little-endian, data-type-policy=OVERRIDE, base-type=uint8, compu {phys=raw}, range phys 0..252
          signal StatusFBD_HM_BLEChipErrorState: start 120, 8 bit, little-endian, data-type-policy=OVERRIDE, compu {phys=raw}
          signal StatusFBD_HM_UWBChipPowerOnResetCounter: start 128, 8 bit, little-endian, data-type-policy=OVERRIDE, base-type=uint8, compu {phys=raw}, range phys 0..252
          signal StatusFBD_HM_UWBChipSWResetCounter: start 136, 8 bit, little-endian, data-type-policy=OVERRIDE, base-type=uint8, compu {phys=raw}, range phys 0..252
          signal StatusFBD_HM_UWBChipWatchdogCounter: start 144, 8 bit, little-endian, data-type-policy=OVERRIDE, base-type=uint8, compu {phys=raw}, range phys 0..252
          signal StatusFBD_HM_UWBChipTemperaturePrewarningCounter: start 152, 8 bit, little-endian, data-type-policy=OVERRIDE, base-type=uint8, compu {phys=raw}, range phys 0..252
          signal StatusFBD_HM_UWBChipThermalShutdownCounter: start 160, 8 bit, little-endian, data-type-policy=OVERRIDE, base-type=uint8, compu {phys=raw}, range phys 0..252
          signal StatusFBD_HM_UWBChipErrorState: start 168, 8 bit, little-endian, data-type-policy=OVERRIDE, compu {phys=raw}
          signal StatusFBD_HM_ProgrammingCounter: start 176, 8 bit, little-endian, data-type-policy=OVERRIDE, base-type=uint8, compu {phys=raw}, range phys 0..252
          signal StatusFBD_HM_ProgrammingErrorCounter: start 184, 8 bit, little-endian, data-type-policy=OVERRIDE, base-type=uint8, compu {phys=raw}, range phys 0..252
          signal StatusFBD_HM_SPIHangupCounter: start 192, 8 bit, little-endian, data-type-policy=OVERRIDE, base-type=uint8, compu {phys=raw}, range phys 0..252
          signal StatusFBD_HM_SBCChipTemperaturePrewarningCounter: start 200, 8 bit, little-endian, data-type-policy=OVERRIDE, base-type=uint8, compu {phys=raw}, range phys 0..252
          signal StatusFBD_HM_SBCChipThermalShutdownCounter: start 208, 8 bit, little-endian, data-type-policy=OVERRIDE, base-type=uint8, compu {phys=raw}, range phys 0..252
          signal StatusFBD_HM_SBCErrorState: start 216, 8 bit, little-endian, data-type-policy=OVERRIDE, compu {phys=raw}
          signal StatusFBD_HM_OptionCode: start 224, 8 bit, little-endian, data-type-policy=OVERRIDE, compu {phys=raw}
          signal StatusFBD_HM_UWBCollisionCounter: start 232, 8 bit, little-endian, data-type-policy=OVERRIDE, base-type=uint8, compu {phys=raw}, range phys 0..252
          signal StatusFBD_HM_DebugInformation1: start 240, 8 bit, little-endian, data-type-policy=OVERRIDE, compu {phys=raw}
          signal StatusFBD_HM_DebugInformation2: start 248, 8 bit, little-endian, data-type-policy=OVERRIDE, compu {phys=raw}
      frame StatusFBD_HR: id 0x9D, frame-length=32, can-addressing-mode=STANDARD, can-frame-rx-behavior=CAN-FD, can-frame-tx-behavior=CAN-FD
        pdu StatusFBD_HR: length=32, unused-bit-pattern=0
          signal StatusFBD_HR_PowerMode: start 0, 8 bit, little-endian, data-type-policy=OVERRIDE, compu {phys=raw}
          signal StatusFBD_HR_ResetState: start 8, 8 bit, little-endian, data-type-policy=OVERRIDE, base-type=uint8, compu {phys=raw}, range phys 0..252
          signal StatusFBD_HR_ResetReason: start 16, 8 bit, little-endian, data-type-policy=OVERRIDE, base-type=uint8, compu {phys=raw}, range phys 0..252
          signal StatusFBD_HR_BLEStatus: start 24, 8 bit, little-endian, data-type-policy=OVERRIDE, compu {phys=raw}
          signal StatusFBD_HR_UWBStatus: start 32, 8 bit, little-endian, data-type-policy=OVERRIDE, compu {phys=raw}
          signal StatusFBD_HR_WakeUpReason: start 40, 8 bit, little-endian, data-type-policy=OVERRIDE, compu {phys=raw}
          signal StatusFBD_HR_IRKListIndexWakeUpTrigger: start 48, 8 bit, little-endian, data-type-policy=OVERRIDE, base-type=uint8, compu {phys=raw}, range phys 0..252
          signal StatusFBD_HR_Temperature: start 56, 8 bit, little-endian, data-type-policy=OVERRIDE, base-type=uint8, compu {phys=raw-100; unit °C}, range phys -100..150
          signal StatusFBD_HR_BLENumberOfBonding: start 64, 8 bit, little-endian, data-type-policy=OVERRIDE, base-type=uint8, compu {phys=raw}, range phys 0..252
          signal StatusFBD_HR_BLENumberActiveConnections: start 72, 8 bit, little-endian, data-type-policy=OVERRIDE, base-type=uint8, compu {phys=raw}, range phys 0..252
          signal StatusFBD_HR_BLEChipPowerOnResetCounter: start 80, 8 bit, little-endian, data-type-policy=OVERRIDE, base-type=uint8, compu {phys=raw}, range phys 0..252
          signal StatusFBD_HR_BLEChipSWResetCounter: start 88, 8 bit, little-endian, data-type-policy=OVERRIDE, base-type=uint8, compu {phys=raw}, range phys 0..252
          signal StatusFBD_HR_BLEChipWatchdogCounter: start 96, 8 bit, little-endian, data-type-policy=OVERRIDE, base-type=uint8, compu {phys=raw}, range phys 0..252
          signal StatusFBD_HR_BLEChipTemperaturePrewarningCounter: start 104, 8 bit, little-endian, data-type-policy=OVERRIDE, base-type=uint8, compu {phys=raw}, range phys 0..252
          signal StatusFBD_HR_BLEChipThermalShutdownCounter: start 112, 8 bit, little-endian, data-type-policy=OVERRIDE, base-type=uint8, compu {phys=raw}, range phys 0..252
          signal StatusFBD_HR_BLEChipErrorState: start 120, 8 bit, little-endian, data-type-policy=OVERRIDE, compu {phys=raw}
          signal StatusFBD_HR_UWBChipPowerOnResetCounter: start 128, 8 bit, little-endian, data-type-policy=OVERRIDE, base-type=uint8, compu {phys=raw}, range phys 0..252
          signal StatusFBD_HR_UWBChipSWResetCounter: start 136, 8 bit, little-endian, data-type-policy=OVERRIDE, base-type=uint8, compu {phys=raw}, range phys 0..252
          signal StatusFBD_HR_UWBChipWatchdogCounter: start 144, 8 bit, little-endian, data-type-policy=OVERRIDE, base-type=uint8, compu {phys=raw}, range phys 0..252
          signal StatusFBD_HR_UWBChipTemperaturePrewarningCounter: start 152, 8 bit, little-endian, data-type-policy=OVERRIDE, base-type=uint8, compu {phys=raw}, range phys 0..252
          signal StatusFBD_HR_UWBChipThermalShutdownCounter: start 160, 8 bit, little-endian, data-type-policy=OVERRIDE, base-type=uint8, compu {phys=raw}, range phys 0..252
          signal StatusFBD_HR_UWBChipErrorState: start 168, 8 bit, little-endian, data-type-policy=OVERRIDE, compu {phys=raw}
          signal StatusFBD_HR_ProgrammingCounter: start 176, 8 bit, little-endian, data-type-policy=OVERRIDE, base-type=uint8, compu {phys=raw}, range phys 0..252
          signal StatusFBD_HR_ProgrammingErrorCounter: start 184, 8 bit, little-endian, data-type-policy=OVERRIDE, base-type=uint8, compu {phys=raw}, range phys 0..252
          signal StatusFBD_HR_SPIHangupCounter: start 192, 8 bit, little-endian, data-type-policy=OVERRIDE, base-type=uint8, compu {phys=raw}, range phys 0..252
          signal StatusFBD_HR_SBCChipTemperaturePrewarningCounter: start 200, 8 bit, little-endian, data-type-policy=OVERRIDE, base-type=uint8, compu {phys=raw}, range phys 0..252
          signal StatusFBD_HR_SBCChipThermalShutdownCounter: start 208, 8 bit, little-endian, data-type-policy=OVERRIDE, base-type=uint8, compu {phys=raw}, range phys 0..252
          signal StatusFBD_HR_SBCErrorState: start 216, 8 bit, little-endian, data-type-policy=OVERRIDE, compu {phys=raw}
          signal StatusFBD_HR_OptionCode: start 224, 8 bit, little-endian, data-type-policy=OVERRIDE, compu {phys=raw}
          signal StatusFBD_HR_UWBCollisionCounter: start 232, 8 bit, little-endian, data-type-policy=OVERRIDE, base-type=uint8, compu {phys=raw}, range phys 0..252
          signal StatusFBD_HR_DebugInformation1: start 240, 8 bit, little-endian, data-type-policy=OVERRIDE, compu {phys=raw}
          signal StatusFBD_HR_DebugInformation2: start 248, 8 bit, little-endian, data-type-policy=OVERRIDE, compu {phys=raw}
      frame StatusFBD_Miko: id 0x98, frame-length=32, can-addressing-mode=STANDARD, can-frame-rx-behavior=CAN-FD, can-frame-tx-behavior=CAN-FD
        pdu StatusFBD_Miko: length=32, unused-bit-pattern=0
          signal StatusFBD_Miko_PowerMode: start 0, 8 bit, little-endian, data-type-policy=OVERRIDE, compu {phys=raw}
          signal StatusFBD_Miko_ResetState: start 8, 8 bit, little-endian, data-type-policy=OVERRIDE, base-type=uint8, compu {phys=raw}, range phys 0..252
          signal StatusFBD_Miko_ResetReason: start 16, 8 bit, little-endian, data-type-policy=OVERRIDE, base-type=uint8, compu {phys=raw}, range phys 0..252
          signal StatusFBD_Miko_BLEStatus: start 24, 8 bit, little-endian, data-type-policy=OVERRIDE, compu {phys=raw}
          signal StatusFBD_Miko_UWBStatus: start 32, 8 bit, little-endian, data-type-policy=OVERRIDE, compu {phys=raw}
          signal StatusFBD_Miko_WakeUpReason: start 40, 8 bit, little-endian, data-type-policy=OVERRIDE, compu {phys=raw}
          signal StatusFBD_Miko_IRKListIndexWakeUpTrigger: start 48, 8 bit, little-endian, data-type-policy=OVERRIDE, base-type=uint8, compu {phys=raw}, range phys 0..252
          signal StatusFBD_Miko_Temperature: start 56, 8 bit, little-endian, data-type-policy=OVERRIDE, base-type=uint8, compu {phys=raw-100; unit °C}, range phys -100..150
          signal StatusFBD_Miko_BLENumberOfBonding: start 64, 8 bit, little-endian, data-type-policy=OVERRIDE, base-type=uint8, compu {phys=raw}, range phys 0..252
          signal StatusFBD_Miko_BLENumberActiveConnections: start 72, 8 bit, little-endian, data-type-policy=OVERRIDE, base-type=uint8, compu {phys=raw}, range phys 0..252
          signal StatusFBD_Miko_BLEChipPowerOnResetCounter: start 80, 8 bit, little-endian, data-type-policy=OVERRIDE, base-type=uint8, compu {phys=raw}, range phys 0..252
          signal StatusFBD_Miko_BLEChipSWResetCounter: start 88, 8 bit, little-endian, data-type-policy=OVERRIDE, base-type=uint8, compu {phys=raw}, range phys 0..252
          signal StatusFBD_Miko_BLEChipWatchdogCounter: start 96, 8 bit, little-endian, data-type-policy=OVERRIDE, base-type=uint8, compu {phys=raw}, range phys 0..252
          signal StatusFBD_Miko_BLEChipTemperaturePrewarningCounter: start 104, 8 bit, little-endian, data-type-policy=OVERRIDE, base-type=uint8, compu {phys=raw}, range phys 0..252
          signal StatusFBD_Miko_BLEChipThermalShutdownCounter: start 112, 8 bit, little-endian, data-type-policy=OVERRIDE, base-type=uint8, compu {phys=raw}, range phys 0..252
          signal StatusFBD_Miko_BLEChipErrorState: start 120, 8 bit, little-endian, data-type-policy=OVERRIDE, compu {phys=raw}
          signal StatusFBD_Miko_UWBChipPowerOnResetCounter: start 128, 8 bit, little-endian, data-type-policy=OVERRIDE, base-type=uint8, compu {phys=raw}, range phys 0..252
          signal StatusFBD_Miko_UWBChipSWResetCounter: start 136, 8 bit, little-endian, data-type-policy=OVERRIDE, base-type=uint8, compu {phys=raw}, range phys 0..252
          signal StatusFBD_Miko_UWBChipWatchdogCounter: start 144, 8 bit, little-endian, data-type-policy=OVERRIDE, base-type=uint8, compu {phys=raw}, range phys 0..252
          signal StatusFBD_Miko_UWBChipTemperaturePrewarningCounter: start 152, 8 bit, little-endian, data-type-policy=OVERRIDE, base-type=uint8, compu {phys=raw}, range phys 0..252
          signal StatusFBD_Miko_UWBChipThermalShutdownCounter: start 160, 8 bit, little-endian, data-type-policy=OVERRIDE, base-type=uint8, compu {phys=raw}, range phys 0..252
          signal StatusFBD_Miko_UWBChipErrorState: start 168, 8 bit, little-endian, data-type-policy=OVERRIDE, compu {phys=raw}
          signal StatusFBD_Miko_ProgrammingCounter: start 176, 8 bit, little-endian, data-type-policy=OVERRIDE, base-type=uint8, compu {phys=raw}, range phys 0..252
          signal StatusFBD_Miko_ProgrammingErrorCounter: start 184, 8 bit, little-endian, data-type-policy=OVERRIDE, base-type=uint8, compu {phys=raw}, range phys 0..252
          signal StatusFBD_Miko_SPIHangupCounter: start 192, 8 bit, little-endian, data-type-policy=OVERRIDE, base-type=uint8, compu {phys=raw}, range phys 0..252
          signal StatusFBD_Miko_SBCChipTemperaturePrewarningCounter: start 200, 8 bit, little-endian, data-type-policy=OVERRIDE, base-type=uint8, compu {phys=raw}, range phys 0..252
          signal StatusFBD_Miko_SBCChipThermalShutdownCounter: start 208, 8 bit, little-endian, data-type-policy=OVERRIDE, base-type=uint8, compu {phys=raw}, range phys 0..252
          signal StatusFBD_Miko_SBCErrorState: start 216, 8 bit, little-endian, data-type-policy=OVERRIDE, compu {phys=raw}
          signal StatusFBD_Miko_OptionCode: start 224, 8 bit, little-endian, data-type-policy=OVERRIDE, compu {phys=raw}
          signal StatusFBD_Miko_UWBCollisionCounter: start 232, 8 bit, little-endian, data-type-policy=OVERRIDE, base-type=uint8, compu {phys=raw}, range phys 0..252
          signal StatusFBD_Miko_DebugInformation1: start 240, 8 bit, little-endian, data-type-policy=OVERRIDE, compu {phys=raw}
          signal StatusFBD_Miko_DebugInformation2: start 248, 8 bit, little-endian, data-type-policy=OVERRIDE, compu {phys=raw}
      frame StatusFBD_MM: id 0x32F, frame-length=64, can-addressing-mode=STANDARD, can-frame-rx-behavior=CAN-FD, can-frame-tx-behavior=CAN-FD
        pdu StatusFBD_MM: length=64, unused-bit-pattern=0
          signal StatusFBD_MM_PowerMode: start 0, 8 bit, little-endian, data-type-policy=OVERRIDE, compu {phys=raw}
          signal StatusFBD_MM_ResetState: start 8, 8 bit, little-endian, data-type-policy=OVERRIDE, base-type=uint8, compu {phys=raw}, range phys 0..252
          signal StatusFBD_MM_ResetReason: start 16, 8 bit, little-endian, data-type-policy=OVERRIDE, base-type=uint8, compu {phys=raw}, range phys 0..252
          signal StatusFBD_MM_BLEStatus: start 24, 8 bit, little-endian, data-type-policy=OVERRIDE, compu {phys=raw}
          signal StatusFBD_MM_UWBStatus: start 32, 8 bit, little-endian, data-type-policy=OVERRIDE, compu {phys=raw}
          signal StatusFBD_MM_WakeUpReason: start 40, 8 bit, little-endian, data-type-policy=OVERRIDE, compu {phys=raw}
          signal StatusFBD_MM_IRKListIndexWakeUpTrigger: start 48, 8 bit, little-endian, data-type-policy=OVERRIDE, base-type=uint8, compu {phys=raw}, range phys 0..252
          signal StatusFBD_MM_Temperature: start 56, 8 bit, little-endian, data-type-policy=OVERRIDE, base-type=uint8, compu {phys=raw-100; unit °C}, range phys -100..150
          signal StatusFBD_MM_BLENumberOfBonding: start 64, 8 bit, little-endian, data-type-policy=OVERRIDE, base-type=uint8, compu {phys=raw}, range phys 0..252
          signal StatusFBD_MM_BLENumberActiveConnections: start 72, 8 bit, little-endian, data-type-policy=OVERRIDE, base-type=uint8, compu {phys=raw}, range phys 0..252
          signal StatusFBD_MM_BLEChipPowerOnResetCounter: start 80, 8 bit, little-endian, data-type-policy=OVERRIDE, base-type=uint8, compu {phys=raw}, range phys 0..252
          signal StatusFBD_MM_BLEChipSWResetCounter: start 88, 8 bit, little-endian, data-type-policy=OVERRIDE, base-type=uint8, compu {phys=raw}, range phys 0..252
          signal StatusFBD_MM_BLEChipWatchdogCounter: start 96, 8 bit, little-endian, data-type-policy=OVERRIDE, base-type=uint8, compu {phys=raw}, range phys 0..252
          signal StatusFBD_MM_BLEChipTemperaturePrewarningCounter: start 104, 8 bit, little-endian, data-type-policy=OVERRIDE, base-type=uint8, compu {phys=raw}, range phys 0..252
          signal StatusFBD_MM_BLEChipThermalShutdownCounter: start 112, 8 bit, little-endian, data-type-policy=OVERRIDE, base-type=uint8, compu {phys=raw}, range phys 0..252
          signal StatusFBD_MM_BLEChipErrorState: start 120, 8 bit, little-endian, data-type-policy=OVERRIDE, compu {phys=raw}
          signal StatusFBD_MM_UWBChipPowerOnResetCounter: start 128, 8 bit, little-endian, data-type-policy=OVERRIDE, base-type=uint8, compu {phys=raw}, range phys 0..252
          signal StatusFBD_MM_UWBChipSWResetCounter: start 136, 8 bit, little-endian, data-type-policy=OVERRIDE, base-type=uint8, compu {phys=raw}, range phys 0..252
          signal StatusFBD_MM_UWBChipWatchdogCounter: start 144, 8 bit, little-endian, data-type-policy=OVERRIDE, base-type=uint8, compu {phys=raw}, range phys 0..252
          signal StatusFBD_MM_UWBChipTemperaturePrewarningCounter: start 152, 8 bit, little-endian, data-type-policy=OVERRIDE, base-type=uint8, compu {phys=raw}, range phys 0..252
          signal StatusFBD_MM_UWBChipThermalShutdownCounter: start 160, 8 bit, little-endian, data-type-policy=OVERRIDE, base-type=uint8, compu {phys=raw}, range phys 0..252
          signal StatusFBD_MM_UWBChipErrorState: start 168, 8 bit, little-endian, data-type-policy=OVERRIDE, compu {phys=raw}
          signal StatusFBD_MM_ProgrammingCounter: start 176, 8 bit, little-endian, data-type-policy=OVERRIDE, base-type=uint8, compu {phys=raw}, range phys 0..252
          signal StatusFBD_MM_ProgrammingErrorCounter: start 184, 8 bit, little-endian, data-type-policy=OVERRIDE, base-type=uint8, compu {phys=raw}, range phys 0..252
          signal StatusFBD_MM_SPIHangupCounter: start 192, 8 bit, little-endian, data-type-policy=OVERRIDE, base-type=uint8, compu {phys=raw}, range phys 0..252
          signal StatusFBD_MM_SBCChipTemperaturePrewarningCounter: start 200, 8 bit, little-endian, data-type-policy=OVERRIDE, base-type=uint8, compu {phys=raw}, range phys 0..252
          signal StatusFBD_MM_SBCChipThermalShutdownCounter: start 208, 8 bit, little-endian, data-type-policy=OVERRIDE, base-type=uint8, compu {phys=raw}, range phys 0..252
          signal StatusFBD_MM_SBCErrorState: start 216, 8 bit, little-endian, data-type-policy=OVERRIDE, compu {phys=raw}
          signal StatusFBD_MM_OptionCode: start 224, 8 bit, little-endian, data-type-policy=OVERRIDE, compu {phys=raw}
          signal StatusFBD_MM_UWBCollisionCounter: start 232, 8 bit, little-endian, data-type-policy=OVERRIDE, base-type=uint8, compu {phys=raw}, range phys 0..252
          signal StatusFBD_MM_DebugInformation1: start 240, 8 bit, little-endian, data-type-policy=OVERRIDE, compu {phys=raw}
          signal StatusFBD_MM_DebugInformation2: start 248, 8 bit, little-endian, data-type-policy=OVERRIDE, compu {phys=raw}
      frame StatusFBD_Trunk: id 0x99, frame-length=32, can-addressing-mode=STANDARD, can-frame-rx-behavior=CAN-FD, can-frame-tx-behavior=CAN-FD
        pdu StatusFBD_Trunk: length=32, unused-bit-pattern=0
          signal StatusFBD_Trunk_PowerMode: start 0, 8 bit, little-endian, data-type-policy=OVERRIDE, compu {phys=raw}
          signal StatusFBD_Trunk_ResetState: start 8, 8 bit, little-endian, data-type-policy=OVERRIDE, base-type=uint8, compu {phys=raw}, range phys 0..252
          signal StatusFBD_Trunk_ResetReason: start 16, 8 bit, little-endian, data-type-policy=OVERRIDE, base-type=uint8, compu {phys=raw}, range phys 0..252
          signal StatusFBD_Trunk_BLEStatus: start 24, 8 bit, little-endian, data-type-policy=OVERRIDE, compu {phys=raw}
          signal StatusFBD_Trunk_UWBStatus: start 32, 8 bit, little-endian, data-type-policy=OVERRIDE, compu {phys=raw}
          signal StatusFBD_Trunk_WakeUpReason: start 40, 8 bit, little-endian, data-type-policy=OVERRIDE, compu {phys=raw}
          signal StatusFBD_Trunk_IRKListIndexWakeUpTrigger: start 48, 8 bit, little-endian, data-type-policy=OVERRIDE, base-type=uint8, compu {phys=raw}, range phys 0..252
          signal StatusFBD_Trunk_Temperature: start 56, 8 bit, little-endian, data-type-policy=OVERRIDE, base-type=uint8, compu {phys=raw-100; unit °C}, range phys -100..150
          signal StatusFBD_Trunk_BLENumberOfBonding: start 64, 8 bit, little-endian, data-type-policy=OVERRIDE, base-type=uint8, compu {phys=raw}, range phys 0..252
          signal StatusFBD_Trunk_BLENumberActiveConnections: start 72, 8 bit, little-endian, data-type-policy=OVERRIDE, base-type=uint8, compu {phys=raw}, range phys 0..252
          signal StatusFBD_Trunk_BLEChipPowerOnResetCounter: start 80, 8 bit, little-endian, data-type-policy=OVERRIDE, base-type=uint8, compu {phys=raw}, range phys 0..252
          signal StatusFBD_Trunk_BLEChipSWResetCounter: start 88, 8 bit, little-endian, data-type-policy=OVERRIDE, base-type=uint8, compu {phys=raw}, range phys 0..252
          signal StatusFBD_Trunk_BLEChipWatchdogCounter: start 96, 8 bit, little-endian, data-type-policy=OVERRIDE, base-type=uint8, compu {phys=raw}, range phys 0..252
          signal StatusFBD_Trunk_BLEChipTemperaturePrewarningCounter: start 104, 8 bit, little-endian, data-type-policy=OVERRIDE, base-type=uint8, compu {phys=raw}, range phys 0..252
          signal StatusFBD_Trunk_BLEChipThermalShutdownCounter: start 112, 8 bit, little-endian, data-type-policy=OVERRIDE, base-type=uint8, compu {phys=raw}, range phys 0..252
          signal StatusFBD_Trunk_BLEChipErrorState: start 120, 8 bit, little-endian, data-type-policy=OVERRIDE, compu {phys=raw}
          signal StatusFBD_Trunk_UWBChipPowerOnResetCounter: start 128, 8 bit, little-endian, data-type-policy=OVERRIDE, base-type=uint8, compu {phys=raw}, range phys 0..252
          signal StatusFBD_Trunk_UWBChipSWResetCounter: start 136, 8 bit, little-endian, data-type-policy=OVERRIDE, base-type=uint8, compu {phys=raw}, range phys 0..252
          signal StatusFBD_Trunk_UWBChipWatchdogCounter: start 144, 8 bit, little-endian, data-type-policy=OVERRIDE, base-type=uint8, compu {phys=raw}, range phys 0..252
          signal StatusFBD_Trunk_UWBChipTemperaturePrewarningCounter: start 152, 8 bit, little-endian, data-type-policy=OVERRIDE, base-type=uint8, compu {phys=raw}, range phys 0..252
          signal StatusFBD_Trunk_UWBChipThermalShutdownCounter: start 160, 8 bit, little-endian, data-type-policy=OVERRIDE, base-type=uint8, compu {phys=raw}, range phys 0..252
          signal StatusFBD_Trunk_UWBChipErrorState: start 168, 8 bit, little-endian, data-type-policy=OVERRIDE, compu {phys=raw}
          signal StatusFBD_Trunk_ProgrammingCounter: start 176, 8 bit, little-endian, data-type-policy=OVERRIDE, base-type=uint8, compu {phys=raw}, range phys 0..252
          signal StatusFBD_Trunk_ProgrammingErrorCounter: start 184, 8 bit, little-endian, data-type-policy=OVERRIDE, base-type=uint8, compu {phys=raw}, range phys 0..252
          signal StatusFBD_Trunk_SPIHangupCounter: start 192, 8 bit, little-endian, data-type-policy=OVERRIDE, base-type=uint8, compu {phys=raw}, range phys 0..252
          signal StatusFBD_Trunk_SBCChipTemperaturePrewarningCounter: start 200, 8 bit, little-endian, data-type-policy=OVERRIDE, base-type=uint8, compu {phys=raw}, range phys 0..252
          signal StatusFBD_Trunk_SBCChipThermalShutdownCounter: start 208, 8 bit, little-endian, data-type-policy=OVERRIDE, base-type=uint8, compu {phys=raw}, range phys 0..252
          signal StatusFBD_Trunk_SBCErrorState: start 216, 8 bit, little-endian, data-type-policy=OVERRIDE, compu {phys=raw}
          signal StatusFBD_Trunk_OptionCode: start 224, 8 bit, little-endian, data-type-policy=OVERRIDE, compu {phys=raw}
          signal StatusFBD_Trunk_UWBCollisionCounter: start 232, 8 bit, little-endian, data-type-policy=OVERRIDE, base-type=uint8, compu {phys=raw}, range phys 0..252
          signal StatusFBD_Trunk_DebugInformation1: start 240, 8 bit, little-endian, data-type-policy=OVERRIDE, compu {phys=raw}
          signal StatusFBD_Trunk_DebugInformation2: start 248, 8 bit, little-endian, data-type-policy=OVERRIDE, compu {phys=raw}
      frame StatusFBD_VL: id 0x9A, frame-length=32, can-addressing-mode=STANDARD, can-frame-rx-behavior=CAN-FD, can-frame-tx-behavior=CAN-FD
        pdu StatusFBD_VL: length=32, unused-bit-pattern=0
          signal StatusFBD_VL_PowerMode: start 0, 8 bit, little-endian, data-type-policy=OVERRIDE, compu {phys=raw}
          signal StatusFBD_VL_ResetState: start 8, 8 bit, little-endian, data-type-policy=OVERRIDE, base-type=uint8, compu {phys=raw}, range phys 0..252
          signal StatusFBD_VL_ResetReason: start 16, 8 bit, little-endian, data-type-policy=OVERRIDE, base-type=uint8, compu {phys=raw}, range phys 0..252
          signal StatusFBD_VL_BLEStatus: start 24, 8 bit, little-endian, data-type-policy=OVERRIDE, compu {phys=raw}
          signal StatusFBD_VL_UWBStatus: start 32, 8 bit, little-endian, data-type-policy=OVERRIDE, compu {phys=raw}
          signal StatusFBD_VL_WakeUpReason: start 40, 8 bit, little-endian, data-type-policy=OVERRIDE, compu {phys=raw}
          signal StatusFBD_VL_IRKListIndexWakeUpTrigger: start 48, 8 bit, little-endian, data-type-policy=OVERRIDE, base-type=uint8, compu {phys=raw}, range phys 0..252
          signal StatusFBD_VL_Temperature: start 56, 8 bit, little-endian, data-type-policy=OVERRIDE, base-type=uint8, compu {phys=raw-100; unit °C}, range phys -100..150
          signal StatusFBD_VL_BLENumberOfBonding: start 64, 8 bit, little-endian, data-type-policy=OVERRIDE, base-type=uint8, compu {phys=raw}, range phys 0..252
          signal StatusFBD_VL_BLENumberActiveConnections: start 72, 8 bit, little-endian, data-type-policy=OVERRIDE, base-type=uint8, compu {phys=raw}, range phys 0..252
          signal StatusFBD_VL_BLEChipPowerOnResetCounter: start 80, 8 bit, little-endian, data-type-policy=OVERRIDE, base-type=uint8, compu {phys=raw}, range phys 0..252
          signal StatusFBD_VL_BLEChipSWResetCounter: start 88, 8 bit, little-endian, data-type-policy=OVERRIDE, base-type=uint8, compu {phys=raw}, range phys 0..252
          signal StatusFBD_VL_BLEChipWatchdogCounter: start 96, 8 bit, little-endian, data-type-policy=OVERRIDE, base-type=uint8, compu {phys=raw}, range phys 0..252
          signal StatusFBD_VL_BLEChipTemperaturePrewarningCounter: start 104, 8 bit, little-endian, data-type-policy=OVERRIDE, base-type=uint8, compu {phys=raw}, range phys 0..252
          signal StatusFBD_VL_BLEChipThermalShutdownCounter: start 112, 8 bit, little-endian, data-type-policy=OVERRIDE, base-type=uint8, compu {phys=raw}, range phys 0..252
          signal StatusFBD_VL_BLEChipErrorState: start 120, 8 bit, little-endian, data-type-policy=OVERRIDE, compu {phys=raw}
          signal StatusFBD_VL_UWBChipPowerOnResetCounter: start 128, 8 bit, little-endian, data-type-policy=OVERRIDE, base-type=uint8, compu {phys=raw}, range phys 0..252
          signal StatusFBD_VL_UWBChipSWResetCounter: start 136, 8 bit, little-endian, data-type-policy=OVERRIDE, base-type=uint8, compu {phys=raw}, range phys 0..252
          signal StatusFBD_VL_UWBChipWatchdogCounter: start 144, 8 bit, little-endian, data-type-policy=OVERRIDE, base-type=uint8, compu {phys=raw}, range phys 0..252
          signal StatusFBD_VL_UWBChipTemperaturePrewarningCounter: start 152, 8 bit, little-endian, data-type-policy=OVERRIDE, base-type=uint8, compu {phys=raw}, range phys 0..252
          signal StatusFBD_VL_UWBChipThermalShutdownCounter: start 160, 8 bit, little-endian, data-type-policy=OVERRIDE, base-type=uint8, compu {phys=raw}, range phys 0..252
          signal StatusFBD_VL_UWBChipErrorState: start 168, 8 bit, little-endian, data-type-policy=OVERRIDE, compu {phys=raw}
          signal StatusFBD_VL_ProgrammingCounter: start 176, 8 bit, little-endian, data-type-policy=OVERRIDE, base-type=uint8, compu {phys=raw}, range phys 0..252
          signal StatusFBD_VL_ProgrammingErrorCounter: start 184, 8 bit, little-endian, data-type-policy=OVERRIDE, base-type=uint8, compu {phys=raw}, range phys 0..252
          signal StatusFBD_VL_SPIHangupCounter: start 192, 8 bit, little-endian, data-type-policy=OVERRIDE, base-type=uint8, compu {phys=raw}, range phys 0..252
          signal StatusFBD_VL_SBCChipTemperaturePrewarningCounter: start 200, 8 bit, little-endian, data-type-policy=OVERRIDE, base-type=uint8, compu {phys=raw}, range phys 0..252
          signal StatusFBD_VL_SBCChipThermalShutdownCounter: start 208, 8 bit, little-endian, data-type-policy=OVERRIDE, base-type=uint8, compu {phys=raw}, range phys 0..252
          signal StatusFBD_VL_SBCErrorState: start 216, 8 bit, little-endian, data-type-policy=OVERRIDE, compu {phys=raw}
          signal StatusFBD_VL_OptionCode: start 224, 8 bit, little-endian, data-type-policy=OVERRIDE, compu {phys=raw}
          signal StatusFBD_VL_UWBCollisionCounter: start 232, 8 bit, little-endian, data-type-policy=OVERRIDE, base-type=uint8, compu {phys=raw}, range phys 0..252
          signal StatusFBD_VL_DebugInformation1: start 240, 8 bit, little-endian, data-type-policy=OVERRIDE, compu {phys=raw}
          signal StatusFBD_VL_DebugInformation2: start 248, 8 bit, little-endian, data-type-policy=OVERRIDE, compu {phys=raw}
      frame StatusFBD_VM: id 0x96, frame-length=32, can-addressing-mode=STANDARD, can-frame-rx-behavior=CAN-FD, can-frame-tx-behavior=CAN-FD
        pdu StatusFBD_VM: length=32, unused-bit-pattern=0
          signal StatusFBD_VM_PowerMode: start 0, 8 bit, little-endian, data-type-policy=OVERRIDE, compu {phys=raw}
          signal StatusFBD_VM_ResetState: start 8, 8 bit, little-endian, data-type-policy=OVERRIDE, base-type=uint8, compu {phys=raw}, range phys 0..252
          signal StatusFBD_VM_ResetReason: start 16, 8 bit, little-endian, data-type-policy=OVERRIDE, base-type=uint8, compu {phys=raw}, range phys 0..252
          signal StatusFBD_VM_BLEStatus: start 24, 8 bit, little-endian, data-type-policy=OVERRIDE, compu {phys=raw}
          signal StatusFBD_VM_UWBStatus: start 32, 8 bit, little-endian, data-type-policy=OVERRIDE, compu {phys=raw}
          signal StatusFBD_VM_WakeUpReason: start 40, 8 bit, little-endian, data-type-policy=OVERRIDE, compu {phys=raw}
          signal StatusFBD_VM_IRKListIndexWakeUpTrigger: start 48, 8 bit, little-endian, data-type-policy=OVERRIDE, base-type=uint8, compu {phys=raw}, range phys 0..252
          signal StatusFBD_VM_Temperature: start 56, 8 bit, little-endian, data-type-policy=OVERRIDE, base-type=uint8, compu {phys=raw-100; unit °C}, range phys -100..150
          signal StatusFBD_VM_BLENumberOfBonding: start 64, 8 bit, little-endian, data-type-policy=OVERRIDE, base-type=uint8, compu {phys=raw}, range phys 0..252
          signal StatusFBD_VM_BLENumberActiveConnections: start 72, 8 bit, little-endian, data-type-policy=OVERRIDE, base-type=uint8, compu {phys=raw}, range phys 0..252
          signal StatusFBD_VM_BLEChipPowerOnResetCounter: start 80, 8 bit, little-endian, data-type-policy=OVERRIDE, base-type=uint8, compu {phys=raw}, range phys 0..252
          signal StatusFBD_VM_BLEChipSWResetCounter: start 88, 8 bit, little-endian, data-type-policy=OVERRIDE, base-type=uint8, compu {phys=raw}, range phys 0..252
          signal StatusFBD_VM_BLEChipWatchdogCounter: start 96, 8 bit, little-endian, data-type-policy=OVERRIDE, base-type=uint8, compu {phys=raw}, range phys 0..252
          signal StatusFBD_VM_BLEChipTemperaturePrewarningCounter: start 104, 8 bit, little-endian, data-type-policy=OVERRIDE, base-type=uint8, compu {phys=raw}, range phys 0..252
          signal StatusFBD_VM_BLEChipThermalShutdownCounter: start 112, 8 bit, little-endian, data-type-policy=OVERRIDE, base-type=uint8, compu {phys=raw}, range phys 0..252
          signal StatusFBD_VM_BLEChipErrorState: start 120, 8 bit, little-endian, data-type-policy=OVERRIDE, compu {phys=raw}
          signal StatusFBD_VM_UWBChipPowerOnResetCounter: start 128, 8 bit, little-endian, data-type-policy=OVERRIDE, base-type=uint8, compu {phys=raw}, range phys 0..252
          signal StatusFBD_VM_UWBChipSWResetCounter: start 136, 8 bit, little-endian, data-type-policy=OVERRIDE, base-type=uint8, compu {phys=raw}, range phys 0..252
          signal StatusFBD_VM_UWBChipWatchdogCounter: start 144, 8 bit, little-endian, data-type-policy=OVERRIDE, base-type=uint8, compu {phys=raw}, range phys 0..252
          signal StatusFBD_VM_UWBChipTemperaturePrewarningCounter: start 152, 8 bit, little-endian, data-type-policy=OVERRIDE, base-type=uint8, compu {phys=raw}, range phys 0..252
          signal StatusFBD_VM_UWBChipThermalShutdownCounter: start 160, 8 bit, little-endian, data-type-policy=OVERRIDE, base-type=uint8, compu {phys=raw}, range phys 0..252
          signal StatusFBD_VM_UWBChipErrorState: start 168, 8 bit, little-endian, data-type-policy=OVERRIDE, compu {phys=raw}
          signal StatusFBD_VM_ProgrammingCounter: start 176, 8 bit, little-endian, data-type-policy=OVERRIDE, base-type=uint8, compu {phys=raw}, range phys 0..252
          signal StatusFBD_VM_ProgrammingErrorCounter: start 184, 8 bit, little-endian, data-type-policy=OVERRIDE, base-type=uint8, compu {phys=raw}, range phys 0..252
          signal StatusFBD_VM_SPIHangupCounter: start 192, 8 bit, little-endian, data-type-policy=OVERRIDE, base-type=uint8, compu {phys=raw}, range phys 0..252
          signal StatusFBD_VM_SBCChipTemperaturePrewarningCounter: start 200, 8 bit, little-endian, data-type-policy=OVERRIDE, base-type=uint8, compu {phys=raw}, range phys 0..252
          signal StatusFBD_VM_SBCChipThermalShutdownCounter: start 208, 8 bit, little-endian, data-type-policy=OVERRIDE, base-type=uint8, compu {phys=raw}, range phys 0..252
          signal StatusFBD_VM_SBCErrorState: start 216, 8 bit, little-endian, data-type-policy=OVERRIDE, compu {phys=raw}
          signal StatusFBD_VM_OptionCode: start 224, 8 bit, little-endian, data-type-policy=OVERRIDE, compu {phys=raw}
          signal StatusFBD_VM_UWBCollisionCounter: start 232, 8 bit, little-endian, data-type-policy=OVERRIDE, base-type=uint8, compu {phys=raw}, range phys 0..252
          signal StatusFBD_VM_DebugInformation1: start 240, 8 bit, little-endian, data-type-policy=OVERRIDE, compu {phys=raw}
          signal StatusFBD_VM_DebugInformation2: start 248, 8 bit, little-endian, data-type-policy=OVERRIDE, compu {phys=raw}
      frame StatusFBD_VR: id 0x9B, frame-length=32, can-addressing-mode=STANDARD, can-frame-rx-behavior=CAN-FD, can-frame-tx-behavior=CAN-FD
        pdu StatusFBD_VR: length=32, unused-bit-pattern=0
          signal StatusFBD_VR_PowerMode: start 0, 8 bit, little-endian, data-type-policy=OVERRIDE, compu {phys=raw}
          signal StatusFBD_VR_ResetState: start 8, 8 bit, little-endian, data-type-policy=OVERRIDE, base-type=uint8, compu {phys=raw}, range phys 0..252
          signal StatusFBD_VR_ResetReason: start 16, 8 bit, little-endian, data-type-policy=OVERRIDE, base-type=uint8, compu {phys=raw}, range phys 0..252
          signal StatusFBD_VR_BLEStatus: start 24, 8 bit, little-endian, data-type-policy=OVERRIDE, compu {phys=raw}
          signal StatusFBD_VR_UWBStatus: start 32, 8 bit, little-endian, data-type-policy=OVERRIDE, compu {phys=raw}
          signal StatusFBD_VR_WakeUpReason: start 40, 8 bit, little-endian, data-type-policy=OVERRIDE, compu {phys=raw}
          signal StatusFBD_VR_IRKListIndexWakeUpTrigger: start 48, 8 bit, little-endian, data-type-policy=OVERRIDE, base-type=uint8, compu {phys=raw}, range phys 0..252
          signal StatusFBD_VR_Temperature: start 56, 8 bit, little-endian, data-type-policy=OVERRIDE, base-type=uint8, compu {phys=raw-100; unit °C}, range phys -100..150
          signal StatusFBD_VR_BLENumberOfBonding: start 64, 8 bit, little-endian, data-type-policy=OVERRIDE, base-type=uint8, compu {phys=raw}, range phys 0..252
          signal StatusFBD_VR_BLENumberActiveConnections: start 72, 8 bit, little-endian, data-type-policy=OVERRIDE, base-type=uint8, compu {phys=raw}, range phys 0..252
          signal StatusFBD_VR_BLEChipPowerOnResetCounter: start 80, 8 bit, little-endian, data-type-policy=OVERRIDE, base-type=uint8, compu {phys=raw}, range phys 0..252
          signal StatusFBD_VR_BLEChipSWResetCounter: start 88, 8 bit, little-endian, data-type-policy=OVERRIDE, base-type=uint8, compu {phys=raw}, range phys 0..252
          signal StatusFBD_VR_BLEChipWatchdogCounter: start 96, 8 bit, little-endian, data-type-policy=OVERRIDE, base-type=uint8, compu {phys=raw}, range phys 0..252
          signal StatusFBD_VR_BLEChipTemperaturePrewarningCounter: start 104, 8 bit, little-endian, data-type-policy=OVERRIDE, base-type=uint8, compu {phys=raw}, range phys 0..252
          signal StatusFBD_VR_BLEChipThermalShutdownCounter: start 112, 8 bit, little-endian, data-type-policy=OVERRIDE, base-type=uint8, compu {phys=raw}, range phys 0..252
          signal StatusFBD_VR_BLEChipErrorState: start 120, 8 bit, little-endian, data-type-policy=OVERRIDE, compu {phys=raw}
          signal StatusFBD_VR_UWBChipPowerOnResetCounter: start 128, 8 bit, little-endian, data-type-policy=OVERRIDE, base-type=uint8, compu {phys=raw}, range phys 0..252
          signal StatusFBD_VR_UWBChipSWResetCounter: start 136, 8 bit, little-endian, data-type-policy=OVERRIDE, base-type=uint8, compu {phys=raw}, range phys 0..252
          signal StatusFBD_VR_UWBChipWatchdogCounter: start 144, 8 bit, little-endian, data-type-policy=OVERRIDE, base-type=uint8, compu {phys=raw}, range phys 0..252
          signal StatusFBD_VR_UWBChipTemperaturePrewarningCounter: start 152, 8 bit, little-endian, data-type-policy=OVERRIDE, base-type=uint8, compu {phys=raw}, range phys 0..252
          signal StatusFBD_VR_UWBChipThermalShutdownCounter: start 160, 8 bit, little-endian, data-type-policy=OVERRIDE, base-type=uint8, compu {phys=raw}, range phys 0..252
          signal StatusFBD_VR_UWBChipErrorState: start 168, 8 bit, little-endian, data-type-policy=OVERRIDE, compu {phys=raw}
          signal StatusFBD_VR_ProgrammingCounter: start 176, 8 bit, little-endian, data-type-policy=OVERRIDE, base-type=uint8, compu {phys=raw}, range phys 0..252
          signal StatusFBD_VR_ProgrammingErrorCounter: start 184, 8 bit, little-endian, data-type-policy=OVERRIDE, base-type=uint8, compu {phys=raw}, range phys 0..252
          signal StatusFBD_VR_SPIHangupCounter: start 192, 8 bit, little-endian, data-type-policy=OVERRIDE, base-type=uint8, compu {phys=raw}, range phys 0..252
          signal StatusFBD_VR_SBCChipTemperaturePrewarningCounter: start 200, 8 bit, little-endian, data-type-policy=OVERRIDE, base-type=uint8, compu {phys=raw}, range phys 0..252
          signal StatusFBD_VR_SBCChipThermalShutdownCounter: start 208, 8 bit, little-endian, data-type-policy=OVERRIDE, base-type=uint8, compu {phys=raw}, range phys 0..252
          signal StatusFBD_VR_SBCErrorState: start 216, 8 bit, little-endian, data-type-policy=OVERRIDE, compu {phys=raw}
          signal StatusFBD_VR_OptionCode: start 224, 8 bit, little-endian, data-type-policy=OVERRIDE, compu {phys=raw}
          signal StatusFBD_VR_UWBCollisionCounter: start 232, 8 bit, little-endian, data-type-policy=OVERRIDE, base-type=uint8, compu {phys=raw}, range phys 0..252
          signal StatusFBD_VR_DebugInformation1: start 240, 8 bit, little-endian, data-type-policy=OVERRIDE, compu {phys=raw}
          signal StatusFBD_VR_DebugInformation2: start 248, 8 bit, little-endian, data-type-policy=OVERRIDE, compu {phys=raw}
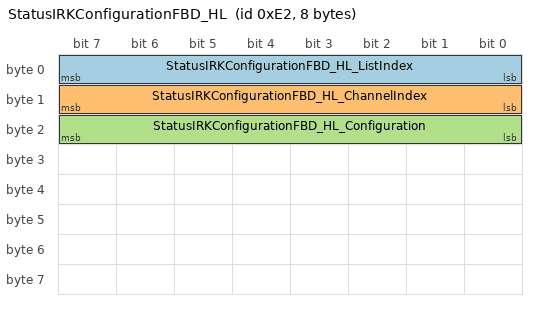
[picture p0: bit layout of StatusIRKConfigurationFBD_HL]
      frame StatusIRKConfigurationFBD_HL: id 0xE2, frame-length=8, can-addressing-mode=STANDARD, can-frame-rx-behavior=CAN-20, can-frame-tx-behavior=CAN-20
        pdu StatusIRKConfigurationFBD_HL: length=8, unused-bit-pattern=0
          signal StatusIRKConfigurationFBD_HL_ListIndex: start 0, 8 bit, little-endian, data-type-policy=OVERRIDE, base-type=uint8, compu {phys=raw}, range phys 0..252
          signal StatusIRKConfigurationFBD_HL_ChannelIndex: start 8, 8 bit, little-endian, data-type-policy=OVERRIDE, compu {phys=raw}
          signal StatusIRKConfigurationFBD_HL_Configuration: start 16, 8 bit, little-endian, data-type-policy=OVERRIDE, compu {phys=raw}
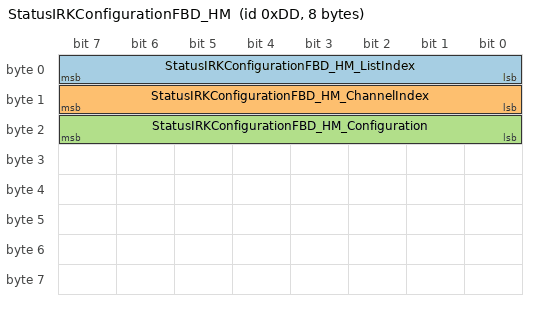
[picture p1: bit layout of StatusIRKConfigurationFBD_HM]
      frame StatusIRKConfigurationFBD_HM: id 0xDD, frame-length=8, can-addressing-mode=STANDARD, can-frame-rx-behavior=CAN-20, can-frame-tx-behavior=CAN-20
        pdu StatusIRKConfigurationFBD_HM: length=8, unused-bit-pattern=0
          signal StatusIRKConfigurationFBD_HM_ListIndex: start 0, 8 bit, little-endian, data-type-policy=OVERRIDE, base-type=uint8, compu {phys=raw}, range phys 0..252
          signal StatusIRKConfigurationFBD_HM_ChannelIndex: start 8, 8 bit, little-endian, data-type-policy=OVERRIDE, compu {phys=raw}
          signal StatusIRKConfigurationFBD_HM_Configuration: start 16, 8 bit, little-endian, data-type-policy=OVERRIDE, compu {phys=raw}
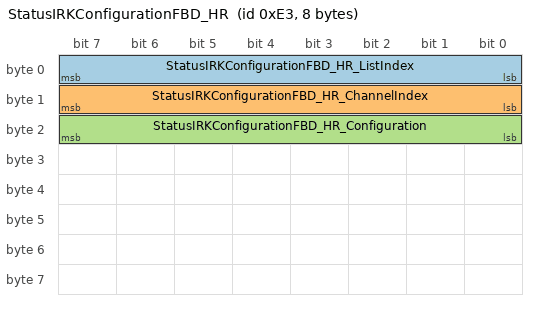
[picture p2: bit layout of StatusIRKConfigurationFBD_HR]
      frame StatusIRKConfigurationFBD_HR: id 0xE3, frame-length=8, can-addressing-mode=STANDARD, can-frame-rx-behavior=CAN-20, can-frame-tx-behavior=CAN-20
        pdu StatusIRKConfigurationFBD_HR: length=8, unused-bit-pattern=0
          signal StatusIRKConfigurationFBD_HR_ListIndex: start 0, 8 bit, little-endian, data-type-policy=OVERRIDE, base-type=uint8, compu {phys=raw}, range phys 0..252
          signal StatusIRKConfigurationFBD_HR_ChannelIndex: start 8, 8 bit, little-endian, data-type-policy=OVERRIDE, compu {phys=raw}
          signal StatusIRKConfigurationFBD_HR_Configuration: start 16, 8 bit, little-endian, data-type-policy=OVERRIDE, compu {phys=raw}
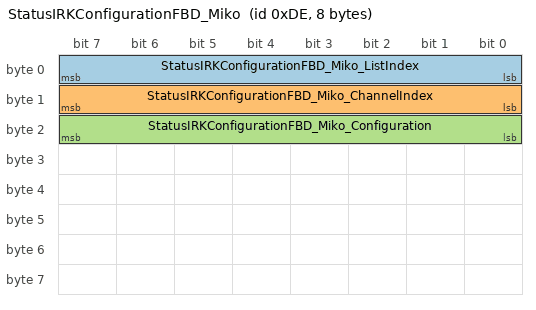
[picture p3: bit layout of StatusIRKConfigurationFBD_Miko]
      frame StatusIRKConfigurationFBD_Miko: id 0xDE, frame-length=8, can-addressing-mode=STANDARD, can-frame-rx-behavior=CAN-20, can-frame-tx-behavior=CAN-20
        pdu StatusIRKConfigurationFBD_Miko: length=8, unused-bit-pattern=0
          signal StatusIRKConfigurationFBD_Miko_ListIndex: start 0, 8 bit, little-endian, data-type-policy=OVERRIDE, base-type=uint8, compu {phys=raw}, range phys 0..252
          signal StatusIRKConfigurationFBD_Miko_ChannelIndex: start 8, 8 bit, little-endian, data-type-policy=OVERRIDE, compu {phys=raw}
          signal StatusIRKConfigurationFBD_Miko_Configuration: start 16, 8 bit, little-endian, data-type-policy=OVERRIDE, compu {phys=raw}
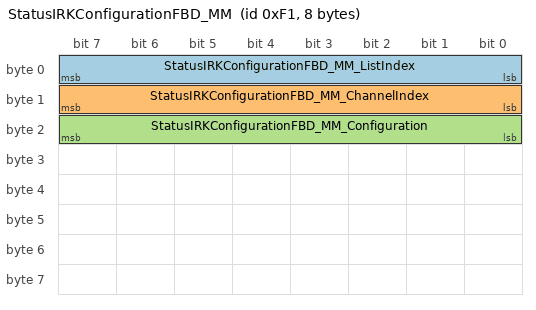
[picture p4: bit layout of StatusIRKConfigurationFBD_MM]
      frame StatusIRKConfigurationFBD_MM: id 0xF1, frame-length=8, can-addressing-mode=STANDARD, can-frame-rx-behavior=CAN-20, can-frame-tx-behavior=CAN-20
        pdu StatusIRKConfigurationFBD_MM: length=8, unused-bit-pattern=0
          signal StatusIRKConfigurationFBD_MM_ListIndex: start 0, 8 bit, little-endian, data-type-policy=OVERRIDE, base-type=uint8, compu {phys=raw}, range phys 0..252
          signal StatusIRKConfigurationFBD_MM_ChannelIndex: start 8, 8 bit, little-endian, data-type-policy=OVERRIDE, compu {phys=raw}
          signal StatusIRKConfigurationFBD_MM_Configuration: start 16, 8 bit, little-endian, data-type-policy=OVERRIDE, compu {phys=raw}
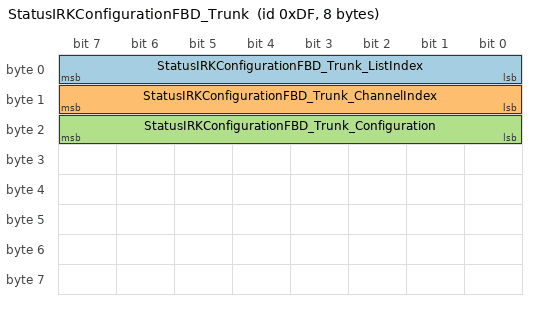
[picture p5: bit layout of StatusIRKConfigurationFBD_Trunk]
      frame StatusIRKConfigurationFBD_Trunk: id 0xDF, frame-length=8, can-addressing-mode=STANDARD, can-frame-rx-behavior=CAN-20, can-frame-tx-behavior=CAN-20
        pdu StatusIRKConfigurationFBD_Trunk: length=8, unused-bit-pattern=0
          signal StatusIRKConfigurationFBD_Trunk_ListIndex: start 0, 8 bit, little-endian, data-type-policy=OVERRIDE, base-type=uint8, compu {phys=raw}, range phys 0..252
          signal StatusIRKConfigurationFBD_Trunk_ChannelIndex: start 8, 8 bit, little-endian, data-type-policy=OVERRIDE, compu {phys=raw}
          signal StatusIRKConfigurationFBD_Trunk_Configuration: start 16, 8 bit, little-endian, data-type-policy=OVERRIDE, compu {phys=raw}
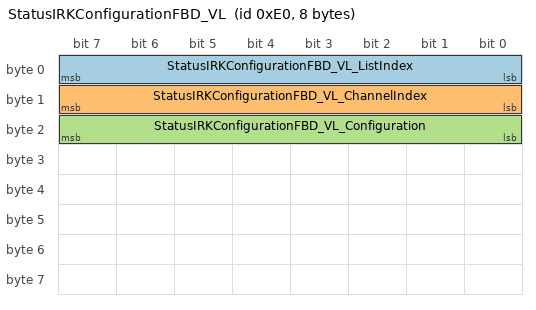
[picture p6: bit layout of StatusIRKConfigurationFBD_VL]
      frame StatusIRKConfigurationFBD_VL: id 0xE0, frame-length=8, can-addressing-mode=STANDARD, can-frame-rx-behavior=CAN-20, can-frame-tx-behavior=CAN-20
        pdu StatusIRKConfigurationFBD_VL: length=8, unused-bit-pattern=0
          signal StatusIRKConfigurationFBD_VL_ListIndex: start 0, 8 bit, little-endian, data-type-policy=OVERRIDE, base-type=uint8, compu {phys=raw}, range phys 0..252
          signal StatusIRKConfigurationFBD_VL_ChannelIndex: start 8, 8 bit, little-endian, data-type-policy=OVERRIDE, compu {phys=raw}
          signal StatusIRKConfigurationFBD_VL_Configuration: start 16, 8 bit, little-endian, data-type-policy=OVERRIDE, compu {phys=raw}
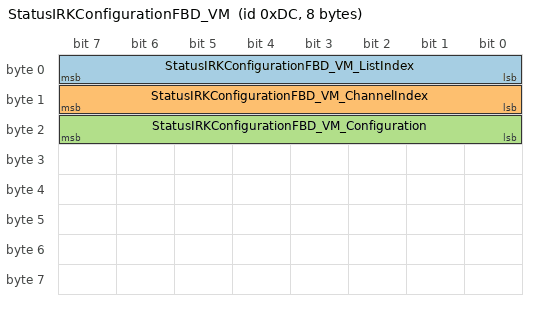
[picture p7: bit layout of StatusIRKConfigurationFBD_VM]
      frame StatusIRKConfigurationFBD_VM: id 0xDC, frame-length=8, can-addressing-mode=STANDARD, can-frame-rx-behavior=CAN-20, can-frame-tx-behavior=CAN-20
        pdu StatusIRKConfigurationFBD_VM: length=8, unused-bit-pattern=0
          signal StatusIRKConfigurationFBD_VM_ListIndex: start 0, 8 bit, little-endian, data-type-policy=OVERRIDE, base-type=uint8, compu {phys=raw}, range phys 0..252
          signal StatusIRKConfigurationFBD_VM_ChannelIndex: start 8, 8 bit, little-endian, data-type-policy=OVERRIDE, compu {phys=raw}
          signal StatusIRKConfigurationFBD_VM_Configuration: start 16, 8 bit, little-endian, data-type-policy=OVERRIDE, compu {phys=raw}
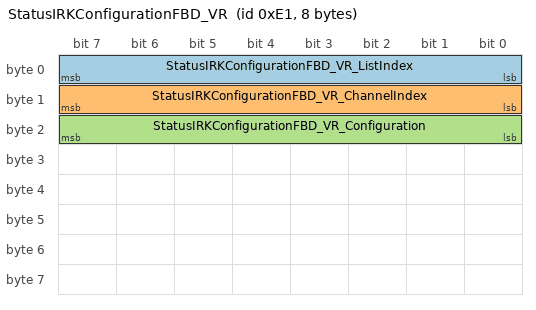
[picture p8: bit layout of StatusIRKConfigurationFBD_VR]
      frame StatusIRKConfigurationFBD_VR: id 0xE1, frame-length=8, can-addressing-mode=STANDARD, can-frame-rx-behavior=CAN-20, can-frame-tx-behavior=CAN-20
        pdu StatusIRKConfigurationFBD_VR: length=8, unused-bit-pattern=0
          signal StatusIRKConfigurationFBD_VR_ListIndex: start 0, 8 bit, little-endian, data-type-policy=OVERRIDE, base-type=uint8, compu {phys=raw}, range phys 0..252
          signal StatusIRKConfigurationFBD_VR_ChannelIndex: start 8, 8 bit, little-endian, data-type-policy=OVERRIDE, compu {phys=raw}
          signal StatusIRKConfigurationFBD_VR_Configuration: start 16, 8 bit, little-endian, data-type-policy=OVERRIDE, compu {phys=raw}
      frame StatusRangingIntentFBD_HL: id 0xEC, frame-length=8, can-addressing-mode=STANDARD, can-frame-rx-behavior=CAN-20, can-frame-tx-behavior=CAN-20
        pdu StatusRangingIntentFBD_HL: length=8, unused-bit-pattern=0
          signal StatusRangingIntentFBD_HL_IRKListID: start 0, 8 bit, little-endian, data-type-policy=OVERRIDE, base-type=uint8, compu {phys=raw}, range phys 0..252
          signal StatusRangingIntentFBD_HL_IntentConfidence: start 8, 8 bit, little-endian, data-type-policy=OVERRIDE, base-type=uint8, compu {phys=raw}, range phys 0..252
      frame StatusRangingIntentFBD_HM: id 0xE7, frame-length=8, can-addressing-mode=STANDARD, can-frame-rx-behavior=CAN-20, can-frame-tx-behavior=CAN-20
        pdu StatusRangingIntentFBD_HM: length=8, unused-bit-pattern=0
          signal StatusRangingIntentFBD_HM_IRKListID: start 0, 8 bit, little-endian, data-type-policy=OVERRIDE, base-type=uint8, compu {phys=raw}, range phys 0..252
          signal StatusRangingIntentFBD_HM_IntentConfidence: start 8, 8 bit, little-endian, data-type-policy=OVERRIDE, base-type=uint8, compu {phys=raw}, range phys 0..252
      frame StatusRangingIntentFBD_HR: id 0xED, frame-length=8, can-addressing-mode=STANDARD, can-frame-rx-behavior=CAN-20, can-frame-tx-behavior=CAN-20
        pdu StatusRangingIntentFBD_HR: length=8, unused-bit-pattern=0
          signal StatusRangingIntentFBD_HR_IRKListID: start 0, 8 bit, little-endian, data-type-policy=OVERRIDE, base-type=uint8, compu {phys=raw}, range phys 0..252
          signal StatusRangingIntentFBD_HR_IntentConfidence: start 8, 8 bit, little-endian, data-type-policy=OVERRIDE, base-type=uint8, compu {phys=raw}, range phys 0..252
      frame StatusRangingIntentFBD_Miko: id 0xE8, frame-length=8, can-addressing-mode=STANDARD, can-frame-rx-behavior=CAN-20, can-frame-tx-behavior=CAN-20
        pdu StatusRangingIntentFBD_Miko: length=8, unused-bit-pattern=0
          signal StatusRangingIntentFBD_Miko_IRKListID: start 0, 8 bit, little-endian, data-type-policy=OVERRIDE, base-type=uint8, compu {phys=raw}, range phys 0..252
          signal StatusRangingIntentFBD_Miko_IntentConfidence: start 8, 8 bit, little-endian, data-type-policy=OVERRIDE, base-type=uint8, compu {phys=raw}, range phys 0..252
      frame StatusRangingIntentFBD_MM: id 0xF2, frame-length=8, can-addressing-mode=STANDARD, can-frame-rx-behavior=CAN-20, can-frame-tx-behavior=CAN-20
        pdu StatusRangingIntentFBD_MM: length=8, unused-bit-pattern=0
          signal StatusRangingIntentFBD_MM_IRKListID: start 0, 8 bit, little-endian, data-type-policy=OVERRIDE, base-type=uint8, compu {phys=raw}, range phys 0..252
          signal StatusRangingIntentFBD_MM_IntentConfidence: start 8, 8 bit, little-endian, data-type-policy=OVERRIDE, base-type=uint8, compu {phys=raw}, range phys 0..252
      frame StatusRangingIntentFBD_Trunk: id 0xE9, frame-length=8, can-addressing-mode=STANDARD, can-frame-rx-behavior=CAN-20, can-frame-tx-behavior=CAN-20
        pdu StatusRangingIntentFBD_Trunk: length=8, unused-bit-pattern=0
          signal StatusRangingIntentFBD_Trunk_IRKListID: start 0, 8 bit, little-endian, data-type-policy=OVERRIDE, base-type=uint8, compu {phys=raw}, range phys 0..252
          signal StatusRangingIntentFBD_Trunk_IntentConfidence: start 8, 8 bit, little-endian, data-type-policy=OVERRIDE, base-type=uint8, compu {phys=raw}, range phys 0..252
      frame StatusRangingIntentFBD_VL: id 0xEA, frame-length=8, can-addressing-mode=STANDARD, can-frame-rx-behavior=CAN-20, can-frame-tx-behavior=CAN-20
        pdu StatusRangingIntentFBD_VL: length=8, unused-bit-pattern=0
          signal StatusRangingIntentFBD_VL_IRKListID: start 0, 8 bit, little-endian, data-type-policy=OVERRIDE, base-type=uint8, compu {phys=raw}, range phys 0..252
          signal StatusRangingIntentFBD_VL_IntentConfidence: start 8, 8 bit, little-endian, data-type-policy=OVERRIDE, base-type=uint8, compu {phys=raw}, range phys 0..252
      frame StatusRangingIntentFBD_VM: id 0xE6, frame-length=8, can-addressing-mode=STANDARD, can-frame-rx-behavior=CAN-20, can-frame-tx-behavior=CAN-20
        pdu StatusRangingIntentFBD_VM: length=8, unused-bit-pattern=0
          signal StatusRangingIntentFBD_VM_IRKListID: start 0, 8 bit, little-endian, data-type-policy=OVERRIDE, base-type=uint8, compu {phys=raw}, range phys 0..252
          signal StatusRangingIntentFBD_VM_IntentConfidence: start 8, 8 bit, little-endian, data-type-policy=OVERRIDE, base-type=uint8, compu {phys=raw}, range phys 0..252
      frame StatusRangingIntentFBD_VR: id 0xEB, frame-length=8, can-addressing-mode=STANDARD, can-frame-rx-behavior=CAN-20, can-frame-tx-behavior=CAN-20
        pdu StatusRangingIntentFBD_VR: length=8, unused-bit-pattern=0
          signal StatusRangingIntentFBD_VR_IRKListID: start 0, 8 bit, little-endian, data-type-policy=OVERRIDE, base-type=uint8, compu {phys=raw}, range phys 0..252
          signal StatusRangingIntentFBD_VR_IntentConfidence: start 8, 8 bit, little-endian, data-type-policy=OVERRIDE, base-type=uint8, compu {phys=raw}, range phys 0..252
      frame StatusRangingSessionFBD_HL: id 0x1AA, frame-length=12, can-addressing-mode=STANDARD, can-frame-rx-behavior=CAN-FD, can-frame-tx-behavior=CAN-FD
        pdu StatusRangingSessionFBD_HL: length=12, unused-bit-pattern=0
          signal StatusRangingSessionFBD_HL_SessionIDShort: start 0, 8 bit, little-endian, data-type-policy=OVERRIDE, base-type=uint8, compu {phys=raw}, range phys 0..252
          signal StatusRangingSessionFBD_HL_RangingBlockIndex: start 8, 16 bit, little-endian, data-type-policy=OVERRIDE, base-type=uint16, compu {phys=raw}, range phys 0..65532
          signal StatusRangingSessionFBD_HL_FunctionACK: start 24, 8 bit, little-endian, data-type-policy=OVERRIDE, base-type=uint8, compu {phys=raw}, range phys 0..252
          signal StatusRangingSessionFBD_HL_SetupACK: start 32, 4 bit, little-endian, data-type-policy=OVERRIDE, compu {phys=raw}
          signal StatusRangingSessionFBD_HL_StartACK: start 36, 4 bit, little-endian, data-type-policy=OVERRIDE, compu {phys=raw}
          signal StatusRangingSessionFBD_HL_SuspendACK: start 40, 4 bit, little-endian, data-type-policy=OVERRIDE, compu {phys=raw}
          signal StatusRangingSessionFBD_HL_ResumeACK: start 44, 4 bit, little-endian, data-type-policy=OVERRIDE, compu {phys=raw}
          signal StatusRangingSessionFBD_HL_Status: start 48, 8 bit, little-endian, data-type-policy=OVERRIDE, base-type=uint8, compu {phys=raw}, range phys 0..252
          signal StatusRangingSessionFBD_HL_Error: start 56, 16 bit, little-endian, data-type-policy=OVERRIDE, base-type=uint16, compu {phys=raw}, range phys 0..65532
          signal StatusRangingSessionFBD_HL_Diag1: start 72, 8 bit, little-endian, data-type-policy=OVERRIDE, base-type=uint8, compu {phys=raw}, range phys 0..252
          signal StatusRangingSessionFBD_HL_Diag2: start 80, 8 bit, little-endian, data-type-policy=OVERRIDE, base-type=uint8, compu {phys=raw}, range phys 0..252
          signal StatusRangingSessionFBD_HL_Diag3: start 88, 8 bit, little-endian, data-type-policy=OVERRIDE, base-type=uint8, compu {phys=raw}, range phys 0..252
      frame StatusRangingSessionFBD_HM: id 0x1A5, frame-length=12, can-addressing-mode=STANDARD, can-frame-rx-behavior=CAN-FD, can-frame-tx-behavior=CAN-FD
        pdu StatusRangingSessionFBD_HM: length=12, unused-bit-pattern=0
          signal StatusRangingSessionFBD_HM_SessionIDShort: start 0, 8 bit, little-endian, data-type-policy=OVERRIDE, base-type=uint8, compu {phys=raw}, range phys 0..252
          signal StatusRangingSessionFBD_HM_FrameIndex: start 8, 16 bit, little-endian, data-type-policy=OVERRIDE, base-type=uint16, compu {phys=raw}, range phys 0..65532
          signal StatusRangingSessionFBD_HM_FunctionACK: start 24, 8 bit, little-endian, data-type-policy=OVERRIDE, base-type=uint8, compu {phys=raw}, range phys 0..252
          signal StatusRangingSessionFBD_HM_SetupACK: start 32, 4 bit, little-endian, data-type-policy=OVERRIDE, compu {phys=raw}
          signal StatusRangingSessionFBD_HM_StartACK: start 36, 4 bit, little-endian, data-type-policy=OVERRIDE, compu {phys=raw}
          signal StatusRangingSessionFBD_HM_SuspendACK: start 40, 4 bit, little-endian, data-type-policy=OVERRIDE, compu {phys=raw}
          signal StatusRangingSessionFBD_HM_ResumeACK: start 44, 4 bit, little-endian, data-type-policy=OVERRIDE, compu {phys=raw}
          signal StatusRangingSessionFBD_HM_Status: start 48, 8 bit, little-endian, data-type-policy=OVERRIDE, base-type=uint8, compu {phys=raw}, range phys 0..252
          signal StatusRangingSessionFBD_HM_Error: start 56, 16 bit, little-endian, data-type-policy=OVERRIDE, base-type=uint16, compu {phys=raw}, range phys 0..65532
          signal StatusRangingSessionFBD_HM_Diag1: start 72, 8 bit, little-endian, data-type-policy=OVERRIDE, base-type=uint8, compu {phys=raw}, range phys 0..252
          signal StatusRangingSessionFBD_HM_Diag2: start 80, 8 bit, little-endian, data-type-policy=OVERRIDE, base-type=uint8, compu {phys=raw}, range phys 0..252
          signal StatusRangingSessionFBD_HM_Diag3: start 88, 8 bit, little-endian, data-type-policy=OVERRIDE, base-type=uint8, compu {phys=raw}, range phys 0..252
      frame StatusRangingSessionFBD_HR: id 0x1AB, frame-length=12, can-addressing-mode=STANDARD, can-frame-rx-behavior=CAN-FD, can-frame-tx-behavior=CAN-FD
        pdu StatusRangingSessionFBD_HR: length=12, unused-bit-pattern=0
          signal StatusRangingSessionFBD_HR_SessionIDShort: start 0, 8 bit, little-endian, data-type-policy=OVERRIDE, base-type=uint8, compu {phys=raw}, range phys 0..252
          signal StatusRangingSessionFBD_HR_FrameIndex: start 8, 16 bit, little-endian, data-type-policy=OVERRIDE, base-type=uint16, compu {phys=raw}, range phys 0..65532
          signal StatusRangingSessionFBD_HR_FunctionACK: start 24, 8 bit, little-endian, data-type-policy=OVERRIDE, base-type=uint8, compu {phys=raw}, range phys 0..252
          signal StatusRangingSessionFBD_HR_SetupACK: start 32, 4 bit, little-endian, data-type-policy=OVERRIDE, compu {phys=raw}
          signal StatusRangingSessionFBD_HR_StartACK: start 36, 4 bit, little-endian, data-type-policy=OVERRIDE, compu {phys=raw}
          signal StatusRangingSessionFBD_HR_SuspendACK: start 40, 4 bit, little-endian, data-type-policy=OVERRIDE, compu {phys=raw}
          signal StatusRangingSessionFBD_HR_ResumeACK: start 44, 4 bit, little-endian, data-type-policy=OVERRIDE, compu {phys=raw}
          signal StatusRangingSessionFBD_HR_Status: start 48, 8 bit, little-endian, data-type-policy=OVERRIDE, base-type=uint8, compu {phys=raw}, range phys 0..252
          signal StatusRangingSessionFBD_HR_Error: start 56, 16 bit, little-endian, data-type-policy=OVERRIDE, base-type=uint16, compu {phys=raw}, range phys 0..65532
          signal StatusRangingSessionFBD_HR_Diag1: start 72, 8 bit, little-endian, data-type-policy=OVERRIDE, base-type=uint8, compu {phys=raw}, range phys 0..252
          signal StatusRangingSessionFBD_HR_Diag2: start 80, 8 bit, little-endian, data-type-policy=OVERRIDE, base-type=uint8, compu {phys=raw}, range phys 0..252
          signal StatusRangingSessionFBD_HR_Diag3: start 88, 8 bit, little-endian, data-type-policy=OVERRIDE, base-type=uint8, compu {phys=raw}, range phys 0..252
      frame StatusRangingSessionFBD_Miko: id 0x1A6, frame-length=12, can-addressing-mode=STANDARD, can-frame-rx-behavior=CAN-FD, can-frame-tx-behavior=CAN-FD
        pdu StatusRangingSessionFBD_Miko: length=12, unused-bit-pattern=0
          signal StatusRangingSessionFBD_Miko_SessionIDShort: start 0, 8 bit, little-endian, data-type-policy=OVERRIDE, base-type=uint8, compu {phys=raw}, range phys 0..252
          signal StatusRangingSessionFBD_Miko_FrameIndex: start 8, 16 bit, little-endian, data-type-policy=OVERRIDE, base-type=uint16, compu {phys=raw}, range phys 0..65532
          signal StatusRangingSessionFBD_Miko_FunctionACK: start 24, 8 bit, little-endian, data-type-policy=OVERRIDE, base-type=uint8, compu {phys=raw}, range phys 0..252
          signal StatusRangingSessionFBD_Miko_SetupACK: start 32, 4 bit, little-endian, data-type-policy=OVERRIDE, compu {phys=raw}
          signal StatusRangingSessionFBD_Miko_StartACK: start 36, 4 bit, little-endian, data-type-policy=OVERRIDE, compu {phys=raw}
          signal StatusRangingSessionFBD_Miko_SuspendACK: start 40, 4 bit, little-endian, data-type-policy=OVERRIDE, compu {phys=raw}
          signal StatusRangingSessionFBD_Miko_ResumeACK: start 44, 4 bit, little-endian, data-type-policy=OVERRIDE, compu {phys=raw}
          signal StatusRangingSessionFBD_Miko_Status: start 48, 8 bit, little-endian, data-type-policy=OVERRIDE, base-type=uint8, compu {phys=raw}, range phys 0..252
          signal StatusRangingSessionFBD_Miko_Error: start 56, 16 bit, little-endian, data-type-policy=OVERRIDE, base-type=uint16, compu {phys=raw}, range phys 0..65532
          signal StatusRangingSessionFBD_Miko_Diag1: start 72, 8 bit, little-endian, data-type-policy=OVERRIDE, base-type=uint8, compu {phys=raw}, range phys 0..252
          signal StatusRangingSessionFBD_Miko_Diag2: start 80, 8 bit, little-endian, data-type-policy=OVERRIDE, base-type=uint8, compu {phys=raw}, range phys 0..252
          signal StatusRangingSessionFBD_Miko_Diag3: start 88, 8 bit, little-endian, data-type-policy=OVERRIDE, base-type=uint8, compu {phys=raw}, range phys 0..252
      frame StatusRangingSessionFBD_MM: id 0x1B8, frame-length=12, can-addressing-mode=STANDARD, can-frame-rx-behavior=CAN-FD, can-frame-tx-behavior=CAN-FD
        pdu StatusRangingSessionFBD_MM: length=12, unused-bit-pattern=0
          signal StatusRangingSessionFBD_MM_SessionIDShort: start 0, 8 bit, little-endian, data-type-policy=OVERRIDE, base-type=uint8, compu {phys=raw}, range phys 0..252
          signal StatusRangingSessionFBD_MM_FrameIndex: start 8, 16 bit, little-endian, data-type-policy=OVERRIDE, base-type=uint16, compu {phys=raw}, range phys 0..65532
          signal StatusRangingSessionFBD_MM_FunctionACK: start 24, 8 bit, little-endian, data-type-policy=OVERRIDE, base-type=uint8, compu {phys=raw}, range phys 0..252
          signal StatusRangingSessionFBD_MM_SetupACK: start 32, 4 bit, little-endian, data-type-policy=OVERRIDE, compu {phys=raw}
          signal StatusRangingSessionFBD_MM_StartACK: start 36, 4 bit, little-endian, data-type-policy=OVERRIDE, compu {phys=raw}
          signal StatusRangingSessionFBD_MM_SuspendACK: start 40, 4 bit, little-endian, data-type-policy=OVERRIDE, compu {phys=raw}
          signal StatusRangingSessionFBD_MM_ResumeACK: start 44, 4 bit, little-endian, data-type-policy=OVERRIDE, compu {phys=raw}
          signal StatusRangingSessionFBD_MM_Status: start 48, 8 bit, little-endian, data-type-policy=OVERRIDE, base-type=uint8, compu {phys=raw}, range phys 0..252
          signal StatusRangingSessionFBD_MM_Error: start 56, 16 bit, little-endian, data-type-policy=OVERRIDE, base-type=uint16, compu {phys=raw}, range phys 0..65532
          signal StatusRangingSessionFBD_MM_Diag1: start 72, 8 bit, little-endian, data-type-policy=OVERRIDE, base-type=uint8, compu {phys=raw}, range phys 0..252
          signal StatusRangingSessionFBD_MM_Diag2: start 80, 8 bit, little-endian, data-type-policy=OVERRIDE, base-type=uint8, compu {phys=raw}, range phys 0..252
          signal StatusRangingSessionFBD_MM_Diag3: start 88, 8 bit, little-endian, data-type-policy=OVERRIDE, base-type=uint8, compu {phys=raw}, range phys 0..252
      frame StatusRangingSessionFBD_Trunk: id 0x1A7, frame-length=12, can-addressing-mode=STANDARD, can-frame-rx-behavior=CAN-FD, can-frame-tx-behavior=CAN-FD
        pdu StatusRangingSessionFBD_Trunk: length=12, unused-bit-pattern=0
          signal StatusRangingSessionFBD_Trunk_SessionIDShort: start 0, 8 bit, little-endian, data-type-policy=OVERRIDE, base-type=uint8, compu {phys=raw}, range phys 0..252
          signal StatusRangingSessionFBD_Trunk_FrameIndex: start 8, 16 bit, little-endian, data-type-policy=OVERRIDE, base-type=uint16, compu {phys=raw}, range phys 0..65532
          signal StatusRangingSessionFBD_Trunk_FunctionACK: start 24, 8 bit, little-endian, data-type-policy=OVERRIDE, base-type=uint8, compu {phys=raw}, range phys 0..252
          signal StatusRangingSessionFBD_Trunk_SetupACK: start 32, 4 bit, little-endian, data-type-policy=OVERRIDE, compu {phys=raw}
          signal StatusRangingSessionFBD_Trunk_StartACK: start 36, 4 bit, little-endian, data-type-policy=OVERRIDE, compu {phys=raw}
          signal StatusRangingSessionFBD_Trunk_SuspendACK: start 40, 4 bit, little-endian, data-type-policy=OVERRIDE, compu {phys=raw}
          signal StatusRangingSessionFBD_Trunk_ResumeACK: start 44, 4 bit, little-endian, data-type-policy=OVERRIDE, compu {phys=raw}
          signal StatusRangingSessionFBD_Trunk_Status: start 48, 8 bit, little-endian, data-type-policy=OVERRIDE, base-type=uint8, compu {phys=raw}, range phys 0..252
          signal StatusRangingSessionFBD_Trunk_Error: start 56, 16 bit, little-endian, data-type-policy=OVERRIDE, base-type=uint16, compu {phys=raw}, range phys 0..65532
          signal StatusRangingSessionFBD_Trunk_Diag1: start 72, 8 bit, little-endian, data-type-policy=OVERRIDE, base-type=uint8, compu {phys=raw}, range phys 0..252
          signal StatusRangingSessionFBD_Trunk_Diag2: start 80, 8 bit, little-endian, data-type-policy=OVERRIDE, base-type=uint8, compu {phys=raw}, range phys 0..252
          signal StatusRangingSessionFBD_Trunk_Diag3: start 88, 8 bit, little-endian, data-type-policy=OVERRIDE, base-type=uint8, compu {phys=raw}, range phys 0..252
      frame StatusRangingSessionFBD_VL: id 0x1A8, frame-length=12, can-addressing-mode=STANDARD, can-frame-rx-behavior=CAN-FD, can-frame-tx-behavior=CAN-FD
        pdu StatusRangingSessionFBD_VL: length=12, unused-bit-pattern=0
          signal StatusRangingSessionFBD_VL_SessionIDShort: start 0, 8 bit, little-endian, data-type-policy=OVERRIDE, base-type=uint8, compu {phys=raw}, range phys 0..252
          signal StatusRangingSessionFBD_VL_FrameIndex: start 8, 16 bit, little-endian, data-type-policy=OVERRIDE, base-type=uint16, compu {phys=raw}, range phys 0..65532
          signal StatusRangingSessionFBD_VL_FunctionACK: start 24, 8 bit, little-endian, data-type-policy=OVERRIDE, base-type=uint8, compu {phys=raw}, range phys 0..252
          signal StatusRangingSessionFBD_VL_SetupACK: start 32, 4 bit, little-endian, data-type-policy=OVERRIDE, compu {phys=raw}
          signal StatusRangingSessionFBD_VL_StartACK: start 36, 4 bit, little-endian, data-type-policy=OVERRIDE, compu {phys=raw}
          signal StatusRangingSessionFBD_VL_SuspendACK: start 40, 4 bit, little-endian, data-type-policy=OVERRIDE, compu {phys=raw}
          signal StatusRangingSessionFBD_VL_ResumeACK: start 44, 4 bit, little-endian, data-type-policy=OVERRIDE, compu {phys=raw}
          signal StatusRangingSessionFBD_VL_Status: start 48, 8 bit, little-endian, data-type-policy=OVERRIDE, base-type=uint8, compu {phys=raw}, range phys 0..252
          signal StatusRangingSessionFBD_VL_Error: start 56, 16 bit, little-endian, data-type-policy=OVERRIDE, base-type=uint16, compu {phys=raw}, range phys 0..65532
          signal StatusRangingSessionFBD_VL_Diag1: start 72, 8 bit, little-endian, data-type-policy=OVERRIDE, base-type=uint8, compu {phys=raw}, range phys 0..252
          signal StatusRangingSessionFBD_VL_Diag2: start 80, 8 bit, little-endian, data-type-policy=OVERRIDE, base-type=uint8, compu {phys=raw}, range phys 0..252
          signal StatusRangingSessionFBD_VL_Diag3: start 88, 8 bit, little-endian, data-type-policy=OVERRIDE, base-type=uint8, compu {phys=raw}, range phys 0..252
      frame StatusRangingSessionFBD_VM: id 0x1A4, frame-length=12, can-addressing-mode=STANDARD, can-frame-rx-behavior=CAN-FD, can-frame-tx-behavior=CAN-FD
        pdu StatusRangingSessionFBD_VM: length=12, unused-bit-pattern=0
          signal StatusRangingSessionFBD_VM_SessionIDShort: start 0, 8 bit, little-endian, data-type-policy=OVERRIDE, base-type=uint8, compu {phys=raw}, range phys 0..252
          signal StatusRangingSessionFBD_VM_FrameIndex: start 8, 16 bit, little-endian, data-type-policy=OVERRIDE, base-type=uint16, compu {phys=raw}, range phys 0..65532
          signal StatusRangingSessionFBD_VM_FunctionACK: start 24, 8 bit, little-endian, data-type-policy=OVERRIDE, base-type=uint8, compu {phys=raw}, range phys 0..252
          signal StatusRangingSessionFBD_VM_SetupACK: start 32, 4 bit, little-endian, data-type-policy=OVERRIDE, compu {phys=raw}
          signal StatusRangingSessionFBD_VM_StartACK: start 36, 4 bit, little-endian, data-type-policy=OVERRIDE, compu {phys=raw}
          signal StatusRangingSessionFBD_VM_SuspendACK: start 40, 4 bit, little-endian, data-type-policy=OVERRIDE, compu {phys=raw}
          signal StatusRangingSessionFBD_VM_ResumeACK: start 44, 4 bit, little-endian, data-type-policy=OVERRIDE, compu {phys=raw}
          signal StatusRangingSessionFBD_VM_Status: start 48, 8 bit, little-endian, data-type-policy=OVERRIDE, base-type=uint8, compu {phys=raw}, range phys 0..252
          signal StatusRangingSessionFBD_VM_Error: start 56, 16 bit, little-endian, data-type-policy=OVERRIDE, base-type=uint16, compu {phys=raw}, range phys 0..65532
          signal StatusRangingSessionFBD_VM_Diag1: start 72, 8 bit, little-endian, data-type-policy=OVERRIDE, base-type=uint8, compu {phys=raw}, range phys 0..252
          signal StatusRangingSessionFBD_VM_Diag2: start 80, 8 bit, little-endian, data-type-policy=OVERRIDE, base-type=uint8, compu {phys=raw}, range phys 0..252
          signal StatusRangingSessionFBD_VM_Diag3: start 88, 8 bit, little-endian, data-type-policy=OVERRIDE, base-type=uint8, compu {phys=raw}, range phys 0..252
      frame StatusRangingSessionFBD_VR: id 0x1A9, frame-length=12, can-addressing-mode=STANDARD, can-frame-rx-behavior=CAN-FD, can-frame-tx-behavior=CAN-FD
        pdu StatusRangingSessionFBD_VR: length=12, unused-bit-pattern=0
          signal StatusRangingSessionFBD_VR_SessionIDShort: start 0, 8 bit, little-endian, data-type-policy=OVERRIDE, base-type=uint8, compu {phys=raw}, range phys 0..252
          signal StatusRangingSessionFBD_VR_FrameIndex: start 8, 16 bit, little-endian, data-type-policy=OVERRIDE, base-type=uint16, compu {phys=raw}, range phys 0..65532
          signal StatusRangingSessionFBD_VR_FunctionACK: start 24, 8 bit, little-endian, data-type-policy=OVERRIDE, base-type=uint8, compu {phys=raw}, range phys 0..252
          signal StatusRangingSessionFBD_VR_SetupACK: start 32, 4 bit, little-endian, data-type-policy=OVERRIDE, compu {phys=raw}
          signal StatusRangingSessionFBD_VR_StartACK: start 36, 4 bit, little-endian, data-type-policy=OVERRIDE, compu {phys=raw}
          signal StatusRangingSessionFBD_VR_SuspendACK: start 40, 4 bit, little-endian, data-type-policy=OVERRIDE, compu {phys=raw}
          signal StatusRangingSessionFBD_VR_ResumeACK: start 44, 4 bit, little-endian, data-type-policy=OVERRIDE, compu {phys=raw}
          signal StatusRangingSessionFBD_VR_Status: start 48, 8 bit, little-endian, data-type-policy=OVERRIDE, base-type=uint8, compu {phys=raw}, range phys 0..252
          signal StatusRangingSessionFBD_VR_Error: start 56, 16 bit, little-endian, data-type-policy=OVERRIDE, base-type=uint16, compu {phys=raw}, range phys 0..65532
          signal StatusRangingSessionFBD_VR_Diag1: start 72, 8 bit, little-endian, data-type-policy=OVERRIDE, base-type=uint8, compu {phys=raw}, range phys 0..252
          signal StatusRangingSessionFBD_VR_Diag2: start 80, 8 bit, little-endian, data-type-policy=OVERRIDE, base-type=uint8, compu {phys=raw}, range phys 0..252
          signal StatusRangingSessionFBD_VR_Diag3: start 88, 8 bit, little-endian, data-type-policy=OVERRIDE, base-type=uint8, compu {phys=raw}, range phys 0..252
      frame StatusRangingSessionSignFBD_HL: id 0x1DC, frame-length=12, can-addressing-mode=STANDARD, can-frame-rx-behavior=CAN-FD, can-frame-tx-behavior=CAN-FD
        pdu StatusRangingSessionSignFBD_HL: length=12, unused-bit-pattern=0
          signal StatusRangingSessionSignFBD_HL_SessionIDShort: start 0, 8 bit, little-endian, data-type-policy=OVERRIDE, base-type=uint8, compu {phys=raw}, range phys 0..252
          signal StatusRangingSessionSignFBD_HL_FrameIndex: start 8, 16 bit, little-endian, data-type-policy=OVERRIDE, base-type=uint16, compu {phys=raw}, range phys 0..65532
          signal StatusRangingSessionSignFBD_HL_Signature: start 24, 64 bit, little-endian, data-type-policy=OVERRIDE, base-type=uint64, compu {phys=raw}, range phys 0..18446744073709551614
      frame StatusRangingSessionSignFBD_HM: id 0x1D7, frame-length=12, can-addressing-mode=STANDARD, can-frame-rx-behavior=CAN-FD, can-frame-tx-behavior=CAN-FD
        pdu StatusRangingSessionSignFBD_HM: length=12, unused-bit-pattern=0
          signal StatusRangingSessionSignFBD_HM_SessionIDShort: start 0, 8 bit, little-endian, data-type-policy=OVERRIDE, base-type=uint8, compu {phys=raw}, range phys 0..252
          signal StatusRangingSessionFBD_HM_RangingBlockIndex: start 8, 16 bit, little-endian, data-type-policy=OVERRIDE, base-type=uint16, compu {phys=raw}, range phys 0..65532
          signal StatusRangingSessionSignFBD_HM_Signature: start 24, 64 bit, little-endian, data-type-policy=OVERRIDE, base-type=uint64, compu {phys=raw}, range phys 0..18446744073709551614
      frame StatusRangingSessionSignFBD_HR: id 0x1DD, frame-length=12, can-addressing-mode=STANDARD, can-frame-rx-behavior=CAN-FD, can-frame-tx-behavior=CAN-FD
        pdu StatusRangingSessionSignFBD_HR: length=12, unused-bit-pattern=0
          signal StatusRangingSessionSignFBD_HR_SessionIDShort: start 0, 8 bit, little-endian, data-type-policy=OVERRIDE, base-type=uint8, compu {phys=raw}, range phys 0..252
          signal StatusRangingSessionFBD_HR_RangingBlockIndex: start 8, 16 bit, little-endian, data-type-policy=OVERRIDE, base-type=uint16, compu {phys=raw}, range phys 0..65532
          signal StatusRangingSessionSignFBD_HR_Signature: start 24, 64 bit, little-endian, data-type-policy=OVERRIDE, base-type=uint64, compu {phys=raw}, range phys 0..18446744073709551614
      frame StatusRangingSessionSignFBD_Miko: id 0x1D8, frame-length=12, can-addressing-mode=STANDARD, can-frame-rx-behavior=CAN-FD, can-frame-tx-behavior=CAN-FD
        pdu StatusRangingSessionSignFBD_Miko: length=12, unused-bit-pattern=0
          signal StatusRangingSessionSignFBD_Miko_SessionIDShort: start 0, 8 bit, little-endian, data-type-policy=OVERRIDE, base-type=uint8, compu {phys=raw}, range phys 0..252
          signal StatusRangingSessionFBD_Miko_RangingBlockIndex: start 8, 16 bit, little-endian, data-type-policy=OVERRIDE, base-type=uint16, compu {phys=raw}, range phys 0..65532
          signal StatusRangingSessionSignFBD_Miko_Signature: start 24, 64 bit, little-endian, data-type-policy=OVERRIDE, base-type=uint64, compu {phys=raw}, range phys 0..18446744073709551614
      frame StatusRangingSessionSignFBD_MM: id 0x1B9, frame-length=12, can-addressing-mode=STANDARD, can-frame-rx-behavior=CAN-FD, can-frame-tx-behavior=CAN-FD
        pdu StatusRangingSessionSignFBD_MM: length=12, unused-bit-pattern=0
          signal StatusRangingSessionSignFBD_MM_SessionIDShort: start 0, 8 bit, little-endian, data-type-policy=OVERRIDE, base-type=uint8, compu {phys=raw}, range phys 0..252
          signal StatusRangingSessionFBD_MM_RangingBlockIndex: start 8, 16 bit, little-endian, data-type-policy=OVERRIDE, base-type=uint16, compu {phys=raw}, range phys 0..65532
          signal StatusRangingSessionSignFBD_MM_Signature: start 24, 64 bit, little-endian, data-type-policy=OVERRIDE, base-type=uint64, compu {phys=raw}, range phys 0..18446744073709551614
      frame StatusRangingSessionSignFBD_Trunk: id 0x1D9, frame-length=12, can-addressing-mode=STANDARD, can-frame-rx-behavior=CAN-FD, can-frame-tx-behavior=CAN-FD
        pdu StatusRangingSessionSignFBD_Trunk: length=12, unused-bit-pattern=0
          signal StatusRangingSessionSignFBD_Trunk_SessionIDShort: start 0, 8 bit, little-endian, data-type-policy=OVERRIDE, base-type=uint8, compu {phys=raw}, range phys 0..252
          signal StatusRangingSessionFBD_Trunk_RangingBlockIndex: start 8, 16 bit, little-endian, data-type-policy=OVERRIDE, base-type=uint16, compu {phys=raw}, range phys 0..65532
          signal StatusRangingSessionSignFBD_Trunk_Signature: start 24, 64 bit, little-endian, data-type-policy=OVERRIDE, base-type=uint64, compu {phys=raw}, range phys 0..18446744073709551614
      frame StatusRangingSessionSignFBD_VL: id 0x1DA, frame-length=12, can-addressing-mode=STANDARD, can-frame-rx-behavior=CAN-FD, can-frame-tx-behavior=CAN-FD
        pdu StatusRangingSessionSignFBD_VL: length=12, unused-bit-pattern=0
          signal StatusRangingSessionSignFBD_VL_SessionIDShort: start 0, 8 bit, little-endian, data-type-policy=OVERRIDE, base-type=uint8, compu {phys=raw}, range phys 0..252
          signal StatusRangingSessionFBD_VL_RangingBlockIndex: start 8, 16 bit, little-endian, data-type-policy=OVERRIDE, base-type=uint16, compu {phys=raw}, range phys 0..65532
          signal StatusRangingSessionSignFBD_VL_Signature: start 24, 64 bit, little-endian, data-type-policy=OVERRIDE, base-type=uint64, compu {phys=raw}, range phys 0..18446744073709551614
      frame StatusRangingSessionSignFBD_VM: id 0x1D6, frame-length=12, can-addressing-mode=STANDARD, can-frame-rx-behavior=CAN-FD, can-frame-tx-behavior=CAN-FD
        pdu StatusRangingSessionSignFBD_VM: length=12, unused-bit-pattern=0
          signal StatusRangingSessionSignFBD_VM_SessionIDShort: start 0, 8 bit, little-endian, data-type-policy=OVERRIDE, base-type=uint8, compu {phys=raw}, range phys 0..252
          signal StatusRangingSessionFBD_VM_RangingBlockIndex: start 8, 16 bit, little-endian, data-type-policy=OVERRIDE, base-type=uint16, compu {phys=raw}, range phys 0..65532
          signal StatusRangingSessionSignFBD_VM_Signature: start 24, 64 bit, little-endian, data-type-policy=OVERRIDE, base-type=uint64, compu {phys=raw}, range phys 0..18446744073709551614
      frame StatusRangingSessionSignFBD_VR: id 0x1DB, frame-length=12, can-addressing-mode=STANDARD, can-frame-rx-behavior=CAN-FD, can-frame-tx-behavior=CAN-FD
        pdu StatusRangingSessionSignFBD_VR: length=12, unused-bit-pattern=0
          signal StatusRangingSessionSignFBD_VR_SessionIDShort: start 0, 8 bit, little-endian, data-type-policy=OVERRIDE, base-type=uint8, compu {phys=raw}, range phys 0..252
          signal StatusRangingSessionFBD_VR_RangingBlockIndex: start 8, 16 bit, little-endian, data-type-policy=OVERRIDE, base-type=uint16, compu {phys=raw}, range phys 0..65532
          signal StatusRangingSessionSignFBD_VR_Signature: start 24, 64 bit, little-endian, data-type-policy=OVERRIDE, base-type=uint64, compu {phys=raw}, range phys 0..18446744073709551614
      frame StatusTimeSyncFBD_HL: id 0x7E, frame-length=8, can-addressing-mode=STANDARD, can-frame-rx-behavior=CAN-20, can-frame-tx-behavior=CAN-20
        pdu StatusTimeSyncFBD_HL: length=8, unused-bit-pattern=0
          signal StatusTimeSyncFBD_HL_Status: start 0, 8 bit, little-endian, data-type-policy=OVERRIDE, compu {phys=raw}
          signal StatusTimeSyncFBD_HL_ReSyncCorrection: start 8, 16 bit, little-endian, data-type-policy=OVERRIDE, base-type=uint16, compu {phys=raw; unit us}, range phys 0..65532
      frame StatusTimeSyncFBD_HM: id 0x79, frame-length=8, can-addressing-mode=STANDARD, can-frame-rx-behavior=CAN-20, can-frame-tx-behavior=CAN-20
        pdu StatusTimeSyncFBD_HM: length=8, unused-bit-pattern=0
          signal StatusTimeSyncFBD_HM_Status: start 0, 8 bit, little-endian, data-type-policy=OVERRIDE, compu {phys=raw}
          signal StatusTimeSyncFBD_HM_ReSyncCorrection: start 8, 16 bit, little-endian, data-type-policy=OVERRIDE, base-type=uint16, compu {phys=raw; unit us}, range phys 0..65532
      frame StatusTimeSyncFBD_HR: id 0x7F, frame-length=8, can-addressing-mode=STANDARD, can-frame-rx-behavior=CAN-20, can-frame-tx-behavior=CAN-20
        pdu StatusTimeSyncFBD_HR: length=8, unused-bit-pattern=0
          signal StatusTimeSyncFBD_HR_Status: start 0, 8 bit, little-endian, data-type-policy=OVERRIDE, compu {phys=raw}
          signal StatusTimeSyncFBD_HR_ReSyncCorrection: start 8, 16 bit, little-endian, data-type-policy=OVERRIDE, base-type=uint16, compu {phys=raw; unit us}, range phys 0..65532
      frame StatusTimeSyncFBD_Miko: id 0x7A, frame-length=8, can-addressing-mode=STANDARD, can-frame-rx-behavior=CAN-20, can-frame-tx-behavior=CAN-20
        pdu StatusTimeSyncFBD_Miko: length=8, unused-bit-pattern=0
          signal StatusTimeSyncFBD_Miko_Status: start 0, 8 bit, little-endian, data-type-policy=OVERRIDE, compu {phys=raw}
          signal StatusTimeSyncFBD_Miko_ReSyncCorrection: start 8, 16 bit, little-endian, data-type-policy=OVERRIDE, base-type=uint16, compu {phys=raw; unit us}, range phys 0..65532
      frame StatusTimeSyncFBD_MM: id 0x32C, frame-length=8, can-addressing-mode=STANDARD, can-frame-rx-behavior=CAN-20, can-frame-tx-behavior=CAN-20
        pdu StatusTimeSyncFBD_MM: length=8, unused-bit-pattern=0
          signal StatusTimeSyncFBD_MM_Status: start 0, 8 bit, little-endian, data-type-policy=OVERRIDE, compu {phys=raw}
          signal StatusTimeSyncFBD_MM_ReSyncCorrection: start 8, 16 bit, little-endian, data-type-policy=OVERRIDE, base-type=uint16, compu {phys=raw; unit us}, range phys 0..65532
      frame StatusTimeSyncFBD_SML: id 0x80, frame-length=8, can-addressing-mode=STANDARD, can-frame-rx-behavior=CAN-20, can-frame-tx-behavior=CAN-20
        pdu StatusTimeSyncFBD_SML: length=8, unused-bit-pattern=0
          signal StatusTimeSyncFBD_SML_Status: start 0, 8 bit, little-endian, data-type-policy=OVERRIDE, compu {phys=raw}
          signal StatusTimeSyncFBD_SML_ReSyncCorrection: start 8, 16 bit, little-endian, data-type-policy=OVERRIDE, base-type=uint16, compu {phys=raw; unit us}, range phys 0..65532
      frame StatusTimeSyncFBD_SMR: id 0x81, frame-length=8, can-addressing-mode=STANDARD, can-frame-rx-behavior=CAN-20, can-frame-tx-behavior=CAN-20
        pdu StatusTimeSyncFBD_SMR: length=8, unused-bit-pattern=0
          signal StatusTimeSyncFBD_SMR_Status: start 0, 8 bit, little-endian, data-type-policy=OVERRIDE, compu {phys=raw}
          signal StatusTimeSyncFBD_SMR_ReSyncCorrection: start 8, 16 bit, little-endian, data-type-policy=OVERRIDE, base-type=uint16, compu {phys=raw; unit us}, range phys 0..65532
      frame StatusTimeSyncFBD_Trunk: id 0x7B, frame-length=8, can-addressing-mode=STANDARD, can-frame-rx-behavior=CAN-20, can-frame-tx-behavior=CAN-20
        pdu StatusTimeSyncFBD_Trunk: length=8, unused-bit-pattern=0
          signal StatusTimeSyncFBD_Trunk_Status: start 0, 8 bit, little-endian, data-type-policy=OVERRIDE, compu {phys=raw}
          signal StatusTimeSyncFBD_Trunk_ReSyncCorrection: start 8, 16 bit, little-endian, data-type-policy=OVERRIDE, base-type=uint16, compu {phys=raw; unit us}, range phys 0..65532
      frame StatusTimeSyncFBD_VL: id 0x7C, frame-length=8, can-addressing-mode=STANDARD, can-frame-rx-behavior=CAN-20, can-frame-tx-behavior=CAN-20
        pdu StatusTimeSyncFBD_VL: length=8, unused-bit-pattern=0
          signal StatusTimeSyncFBD_VL_Status: start 0, 8 bit, little-endian, data-type-policy=OVERRIDE, compu {phys=raw}
          signal StatusTimeSyncFBD_VL_ReSyncCorrection: start 8, 16 bit, little-endian, data-type-policy=OVERRIDE, base-type=uint16, compu {phys=raw; unit us}, range phys 0..65532
      frame StatusTimeSyncFBD_VM: id 0x78, frame-length=8, can-addressing-mode=STANDARD, can-frame-rx-behavior=CAN-20, can-frame-tx-behavior=CAN-20
        pdu StatusTimeSyncFBD_VM: length=8, unused-bit-pattern=0
          signal StatusTimeSyncFBD_VM_Status: start 0, 8 bit, little-endian, data-type-policy=OVERRIDE, compu {phys=raw}
          signal StatusTimeSyncFBD_VM_ReSyncCorrection: start 8, 16 bit, little-endian, data-type-policy=OVERRIDE, base-type=uint16, compu {phys=raw; unit us}, range phys 0..65532
      frame StatusTimeSyncFBD_VR: id 0x7D, frame-length=8, can-addressing-mode=STANDARD, can-frame-rx-behavior=CAN-20, can-frame-tx-behavior=CAN-20
        pdu StatusTimeSyncFBD_VR: length=8, unused-bit-pattern=0
          signal StatusTimeSyncFBD_VR_Status: start 0, 8 bit, little-endian, data-type-policy=OVERRIDE, compu {phys=raw}
          signal StatusTimeSyncFBD_VR_ReSyncCorrection: start 8, 16 bit, little-endian, data-type-policy=OVERRIDE, base-type=uint16, compu {phys=raw; unit us}, range phys 0..65532
      frame StatusUWBRangingFBD_HL: id 0x1B4, frame-length=32, can-addressing-mode=STANDARD, can-frame-rx-behavior=CAN-FD, can-frame-tx-behavior=CAN-FD
        pdu StatusUWBRangingFBD_HL: length=32, unused-bit-pattern=0
          signal StatusUWBRangingFBD_HL_SessionIDShort: start 0, 8 bit, little-endian, data-type-policy=OVERRIDE, base-type=uint8, compu {phys=raw}, range phys 0..252
          signal StatusUWBRangingFBD_HL_TimeOfFlight: start 8, 16 bit, little-endian, data-type-policy=OVERRIDE, base-type=uint16, compu {phys=raw*15.65; unit ps}, range phys 0..1000000
          signal StatusUWBRangingFBD_HL_RangingBlockIndex: start 24, 16 bit, little-endian, data-type-policy=OVERRIDE, base-type=uint16, compu {phys=raw}, range phys 0..65532
          signal StatusUWBRangingFBD_HL_RangingRoundIndex: start 40, 8 bit, little-endian, data-type-policy=OVERRIDE, base-type=uint8, compu {phys=raw}, range phys 0..252
          signal StatusUWBRangingFBD_HL_OverallReceivePower: start 48, 8 bit, little-endian, data-type-policy=OVERRIDE, base-type=uint8, compu {phys=raw*0.5-127; unit dB}, range phys -127..-1
          signal StatusUWBRangingFBD_HL_FirstPathPower: start 56, 8 bit, little-endian, data-type-policy=OVERRIDE, base-type=uint8, compu {phys=raw*0.5-127; unit dB}, range phys -127..-1
          signal StatusUWBRangingFBD_HL_AngleOfArrival: start 64, 8 bit, little-endian, data-type-policy=OVERRIDE, base-type=uint8, compu {phys=raw-90; unit °}, range phys -90..90
          signal StatusUWBRangingFBD_HL_PhaseDifferenceOfArrival: start 72, 8 bit, little-endian, data-type-policy=OVERRIDE, base-type=uint8, compu {phys=raw-90; unit °}, range phys -90..90
          signal StatusUWBRangingFBD_HL_StrongestPathPower: start 80, 8 bit, little-endian, data-type-policy=OVERRIDE, base-type=uint8, compu {phys=raw*0.5-127; unit dB}, range phys -127..-1
          signal StatusUWBRangingFBD_HL_BLE_RSSI: start 88, 8 bit, little-endian, data-type-policy=OVERRIDE, base-type=uint8, compu {phys=raw*0.5-127; unit dB}, range phys -127..-1
          signal StatusUWBRangingFBD_HL_StrongestPathOffset: start 96, 8 bit, little-endian, data-type-policy=OVERRIDE, base-type=uint8, compu {phys=raw*0.5; unit ns}, range phys 0..125
          signal StatusUWBRangingFBD_HL_PDoA_SNR: start 104, 8 bit, little-endian, data-type-policy=OVERRIDE, base-type=uint8, compu {phys=raw*0.5; unit dB}, range phys 0..126
          signal StatusUWBRangingFBD_HL_DutyCycleLimitTxCounter: start 112, 8 bit, little-endian, data-type-policy=OVERRIDE, base-type=uint8, compu {phys=raw; unit %}, range phys 0..100
          signal StatusUWBRangingFBD_HL_FinalDataDistribution: start 120, 4 bit, little-endian, data-type-policy=OVERRIDE, base-type=uint8, compu {phys=raw}, range phys 0..12
          signal StatusUWBRangingFBD_HL_Antenna: start 124, 4 bit, little-endian, data-type-policy=OVERRIDE, compu {phys=raw}
          signal StatusUWBRangingFBD_HL_Status1: start 128, 8 bit, little-endian, data-type-policy=OVERRIDE, compu {phys=raw}
          signal StatusUWBRangingFBD_HL_Status2: start 136, 8 bit, little-endian, data-type-policy=OVERRIDE, base-type=uint8, compu {phys=raw}, range phys 0..252
          signal StatusUWBRangingFBD_HL_Status3: start 144, 8 bit, little-endian, data-type-policy=OVERRIDE, base-type=uint8, compu {phys=raw}, range phys 0..252
          signal StatusUWBRangingFBD_HL_Status4: start 152, 8 bit, little-endian, data-type-policy=OVERRIDE, base-type=uint8, compu {phys=raw}, range phys 0..252
          signal StatusUWBRangingFBD_HL_IV00: start 160, 8 bit, little-endian, data-type-policy=OVERRIDE, base-type=uint8, compu {phys=raw}, range phys 0..255
          signal StatusUWBRangingFBD_HL_IV01: start 168, 8 bit, little-endian, data-type-policy=OVERRIDE, base-type=uint8, compu {phys=raw}, range phys 0..255
          signal StatusUWBRangingFBD_HL_IV02: start 176, 8 bit, little-endian, data-type-policy=OVERRIDE, base-type=uint8, compu {phys=raw}, range phys 0..255
          signal StatusUWBRangingFBD_HL_IV03: start 184, 8 bit, little-endian, data-type-policy=OVERRIDE, base-type=uint8, compu {phys=raw}, range phys 0..255
          signal StatusUWBRangingFBD_HL_Sign00: start 192, 8 bit, little-endian, data-type-policy=OVERRIDE, base-type=uint8, compu {phys=raw}, range phys 0..255
          signal StatusUWBRangingFBD_HL_Sign01: start 200, 8 bit, little-endian, data-type-policy=OVERRIDE, base-type=uint8, compu {phys=raw}, range phys 0..255
          signal StatusUWBRangingFBD_HL_Sign02: start 208, 8 bit, little-endian, data-type-policy=OVERRIDE, base-type=uint8, compu {phys=raw}, range phys 0..255
          signal StatusUWBRangingFBD_HL_Sign03: start 216, 8 bit, little-endian, data-type-policy=OVERRIDE, base-type=uint8, compu {phys=raw}, range phys 0..255
          signal StatusUWBRangingFBD_HL_Sign04: start 224, 8 bit, little-endian, data-type-policy=OVERRIDE, base-type=uint8, compu {phys=raw}, range phys 0..255
          signal StatusUWBRangingFBD_HL_Sign05: start 232, 8 bit, little-endian, data-type-policy=OVERRIDE, base-type=uint8, compu {phys=raw}, range phys 0..255
          signal StatusUWBRangingFBD_HL_Sign06: start 240, 8 bit, little-endian, data-type-policy=OVERRIDE, base-type=uint8, compu {phys=raw}, range phys 0..255
          signal StatusUWBRangingFBD_HL_Sign07: start 248, 8 bit, little-endian, data-type-policy=OVERRIDE, base-type=uint8, compu {phys=raw}, range phys 0..255
      frame StatusUWBRangingFBD_HM: id 0x1AF, frame-length=32, can-addressing-mode=STANDARD, can-frame-rx-behavior=CAN-FD, can-frame-tx-behavior=CAN-FD
        pdu StatusUWBRangingFBD_HM: length=32, unused-bit-pattern=0
          signal StatusUWBRangingFBD_HM_SessionIDShort: start 0, 8 bit, little-endian, data-type-policy=OVERRIDE, base-type=uint8, compu {phys=raw}, range phys 0..252
          signal StatusUWBRangingFBD_HM_TimeOfFlight: start 8, 16 bit, little-endian, data-type-policy=OVERRIDE, base-type=uint16, compu {phys=raw*15.65; unit ps}, range phys 0..1000000
          signal StatusUWBRangingFBD_HM_RangingBlockIndex: start 24, 16 bit, little-endian, data-type-policy=OVERRIDE, base-type=uint16, compu {phys=raw}, range phys 0..65532
          signal StatusUWBRangingFBD_HM_RangingRoundIndex: start 40, 8 bit, little-endian, data-type-policy=OVERRIDE, base-type=uint8, compu {phys=raw}, range phys 0..252
          signal StatusUWBRangingFBD_HM_OverallReceivePower: start 48, 8 bit, little-endian, data-type-policy=OVERRIDE, base-type=uint8, compu {phys=raw*0.5-127; unit dB}, range phys -127..-1
          signal StatusUWBRangingFBD_HM_FirstPathPower: start 56, 8 bit, little-endian, data-type-policy=OVERRIDE, base-type=uint8, compu {phys=raw*0.5-127; unit dB}, range phys -127..-1
          signal StatusUWBRangingFBD_HM_AngleOfArrival: start 64, 8 bit, little-endian, data-type-policy=OVERRIDE, base-type=uint8, compu {phys=raw-90; unit °}, range phys -90..90
          signal StatusUWBRangingFBD_HM_PhaseDifferenceOfArrival: start 72, 8 bit, little-endian, data-type-policy=OVERRIDE, base-type=uint8, compu {phys=raw-90; unit °}, range phys -90..90
          signal StatusUWBRangingFBD_HM_StrongestPathPower: start 80, 8 bit, little-endian, data-type-policy=OVERRIDE, base-type=uint8, compu {phys=raw*0.5-127; unit dB}, range phys -127..-1
          signal StatusUWBRangingFBD_HM_BLE_RSSI: start 88, 8 bit, little-endian, data-type-policy=OVERRIDE, base-type=uint8, compu {phys=raw*0.5-127; unit dB}, range phys -127..-1
          signal StatusUWBRangingFBD_HM_StrongestPathOffset: start 96, 8 bit, little-endian, data-type-policy=OVERRIDE, base-type=uint8, compu {phys=raw*0.5; unit ns}, range phys 0..125
          signal StatusUWBRangingFBD_HM_PDoA_SNR: start 104, 8 bit, little-endian, data-type-policy=OVERRIDE, base-type=uint8, compu {phys=raw*0.5; unit dB}, range phys 0..126
          signal StatusUWBRangingFBD_HM_DutyCycleLimitTxCounter: start 112, 8 bit, little-endian, data-type-policy=OVERRIDE, base-type=uint8, compu {phys=raw; unit %}, range phys 0..100
          signal StatusUWBRangingFBD_HM_FinalDataDistribution: start 120, 4 bit, little-endian, data-type-policy=OVERRIDE, base-type=uint8, compu {phys=raw}, range phys 0..12
          signal StatusUWBRangingFBD_HM_Antenna: start 124, 4 bit, little-endian, data-type-policy=OVERRIDE, compu {phys=raw}
          signal StatusUWBRangingFBD_HM_Status1: start 128, 8 bit, little-endian, data-type-policy=OVERRIDE, compu {phys=raw}
          signal StatusUWBRangingFBD_HM_Status2: start 136, 8 bit, little-endian, data-type-policy=OVERRIDE, base-type=uint8, compu {phys=raw}, range phys 0..252
          signal StatusUWBRangingFBD_HM_Status3: start 144, 8 bit, little-endian, data-type-policy=OVERRIDE, base-type=uint8, compu {phys=raw}, range phys 0..252
          signal StatusUWBRangingFBD_HM_Status4: start 152, 8 bit, little-endian, data-type-policy=OVERRIDE, base-type=uint8, compu {phys=raw}, range phys 0..252
          signal StatusUWBRangingFBD_HM_IV00: start 160, 8 bit, little-endian, data-type-policy=OVERRIDE, base-type=uint8, compu {phys=raw}, range phys 0..255
          signal StatusUWBRangingFBD_HM_IV01: start 168, 8 bit, little-endian, data-type-policy=OVERRIDE, base-type=uint8, compu {phys=raw}, range phys 0..255
          signal StatusUWBRangingFBD_HM_IV02: start 176, 8 bit, little-endian, data-type-policy=OVERRIDE, base-type=uint8, compu {phys=raw}, range phys 0..255
          signal StatusUWBRangingFBD_HM_IV03: start 184, 8 bit, little-endian, data-type-policy=OVERRIDE, base-type=uint8, compu {phys=raw}, range phys 0..255
          signal StatusUWBRangingFBD_HM_Sign00: start 192, 8 bit, little-endian, data-type-policy=OVERRIDE, base-type=uint8, compu {phys=raw}, range phys 0..255
          signal StatusUWBRangingFBD_HM_Sign01: start 200, 8 bit, little-endian, data-type-policy=OVERRIDE, base-type=uint8, compu {phys=raw}, range phys 0..255
          signal StatusUWBRangingFBD_HM_Sign02: start 208, 8 bit, little-endian, data-type-policy=OVERRIDE, base-type=uint8, compu {phys=raw}, range phys 0..255
          signal StatusUWBRangingFBD_HM_Sign03: start 216, 8 bit, little-endian, data-type-policy=OVERRIDE, base-type=uint8, compu {phys=raw}, range phys 0..255
          signal StatusUWBRangingFBD_HM_Sign04: start 224, 8 bit, little-endian, data-type-policy=OVERRIDE, base-type=uint8, compu {phys=raw}, range phys 0..255
          signal StatusUWBRangingFBD_HM_Sign05: start 232, 8 bit, little-endian, data-type-policy=OVERRIDE, base-type=uint8, compu {phys=raw}, range phys 0..255
          signal StatusUWBRangingFBD_HM_Sign06: start 240, 8 bit, little-endian, data-type-policy=OVERRIDE, base-type=uint8, compu {phys=raw}, range phys 0..255
          signal StatusUWBRangingFBD_HM_Sign07: start 248, 8 bit, little-endian, data-type-policy=OVERRIDE, base-type=uint8, compu {phys=raw}, range phys 0..255
      frame StatusUWBRangingFBD_HR: id 0x1B5, frame-length=32, can-addressing-mode=STANDARD, can-frame-rx-behavior=CAN-FD, can-frame-tx-behavior=CAN-FD
        pdu StatusUWBRangingFBD_HR: length=32, unused-bit-pattern=0
          signal StatusUWBRangingFBD_HR_SessionIDShort: start 0, 8 bit, little-endian, data-type-policy=OVERRIDE, base-type=uint8, compu {phys=raw}, range phys 0..252
          signal StatusUWBRangingFBD_HR_TimeOfFlight: start 8, 16 bit, little-endian, data-type-policy=OVERRIDE, base-type=uint16, compu {phys=raw*15.65; unit ps}, range phys 0..1000000
          signal StatusUWBRangingFBD_HR_RangingBlockIndex: start 24, 16 bit, little-endian, data-type-policy=OVERRIDE, base-type=uint16, compu {phys=raw}, range phys 0..65532
          signal StatusUWBRangingFBD_HR_RangingRoundIndex: start 40, 8 bit, little-endian, data-type-policy=OVERRIDE, base-type=uint8, compu {phys=raw}, range phys 0..252
          signal StatusUWBRangingFBD_HR_OverallReceivePower: start 48, 8 bit, little-endian, data-type-policy=OVERRIDE, base-type=uint8, compu {phys=raw*0.5-127; unit dB}, range phys -127..-1
          signal StatusUWBRangingFBD_HR_FirstPathPower: start 56, 8 bit, little-endian, data-type-policy=OVERRIDE, base-type=uint8, compu {phys=raw*0.5-127; unit dB}, range phys -127..-1
          signal StatusUWBRangingFBD_HR_AngleOfArrival: start 64, 8 bit, little-endian, data-type-policy=OVERRIDE, base-type=uint8, compu {phys=raw-90; unit °}, range phys -90..90
          signal StatusUWBRangingFBD_HR_PhaseDifferenceOfArrival: start 72, 8 bit, little-endian, data-type-policy=OVERRIDE, base-type=uint8, compu {phys=raw-90; unit °}, range phys -90..90
          signal StatusUWBRangingFBD_HR_StrongestPathPower: start 80, 8 bit, little-endian, data-type-policy=OVERRIDE, base-type=uint8, compu {phys=raw*0.5-127; unit dB}, range phys -127..-1
          signal StatusUWBRangingFBD_HR_BLE_RSSI: start 88, 8 bit, little-endian, data-type-policy=OVERRIDE, base-type=uint8, compu {phys=raw*0.5-127; unit dB}, range phys -127..-1
          signal StatusUWBRangingFBD_HR_StrongestPathOffset: start 96, 8 bit, little-endian, data-type-policy=OVERRIDE, base-type=uint8, compu {phys=raw*0.5; unit ns}, range phys 0..125
          signal StatusUWBRangingFBD_HR_PDoA_SNR: start 104, 8 bit, little-endian, data-type-policy=OVERRIDE, base-type=uint8, compu {phys=raw*0.5; unit dB}, range phys 0..126
          signal StatusUWBRangingFBD_HR_DutyCycleLimitTxCounter: start 112, 8 bit, little-endian, data-type-policy=OVERRIDE, base-type=uint8, compu {phys=raw; unit %}, range phys 0..100
          signal StatusUWBRangingFBD_HR_FinalDataDistribution: start 120, 4 bit, little-endian, data-type-policy=OVERRIDE, base-type=uint8, compu {phys=raw}, range phys 0..12
          signal StatusUWBRangingFBD_HR_Antenna: start 124, 4 bit, little-endian, data-type-policy=OVERRIDE, compu {phys=raw}
          signal StatusUWBRangingFBD_HR_Status1: start 128, 8 bit, little-endian, data-type-policy=OVERRIDE, compu {phys=raw}
          signal StatusUWBRangingFBD_HR_Status2: start 136, 8 bit, little-endian, data-type-policy=OVERRIDE, base-type=uint8, compu {phys=raw}, range phys 0..252
          signal StatusUWBRangingFBD_HR_Status3: start 144, 8 bit, little-endian, data-type-policy=OVERRIDE, base-type=uint8, compu {phys=raw}, range phys 0..252
          signal StatusUWBRangingFBD_HR_Status4: start 152, 8 bit, little-endian, data-type-policy=OVERRIDE, base-type=uint8, compu {phys=raw}, range phys 0..252
          signal StatusUWBRangingFBD_HR_IV00: start 160, 8 bit, little-endian, data-type-policy=OVERRIDE, base-type=uint8, compu {phys=raw}, range phys 0..255
          signal StatusUWBRangingFBD_HR_IV01: start 168, 8 bit, little-endian, data-type-policy=OVERRIDE, base-type=uint8, compu {phys=raw}, range phys 0..255
          signal StatusUWBRangingFBD_HR_IV02: start 176, 8 bit, little-endian, data-type-policy=OVERRIDE, base-type=uint8, compu {phys=raw}, range phys 0..255
          signal StatusUWBRangingFBD_HR_IV03: start 184, 8 bit, little-endian, data-type-policy=OVERRIDE, base-type=uint8, compu {phys=raw}, range phys 0..255
          signal StatusUWBRangingFBD_HR_Sign00: start 192, 8 bit, little-endian, data-type-policy=OVERRIDE, base-type=uint8, compu {phys=raw}, range phys 0..255
          signal StatusUWBRangingFBD_HR_Sign01: start 200, 8 bit, little-endian, data-type-policy=OVERRIDE, base-type=uint8, compu {phys=raw}, range phys 0..255
          signal StatusUWBRangingFBD_HR_Sign02: start 208, 8 bit, little-endian, data-type-policy=OVERRIDE, base-type=uint8, compu {phys=raw}, range phys 0..255
          signal StatusUWBRangingFBD_HR_Sign03: start 216, 8 bit, little-endian, data-type-policy=OVERRIDE, base-type=uint8, compu {phys=raw}, range phys 0..255
          signal StatusUWBRangingFBD_HR_Sign04: start 224, 8 bit, little-endian, data-type-policy=OVERRIDE, base-type=uint8, compu {phys=raw}, range phys 0..255
          signal StatusUWBRangingFBD_HR_Sign05: start 232, 8 bit, little-endian, data-type-policy=OVERRIDE, base-type=uint8, compu {phys=raw}, range phys 0..255
          signal StatusUWBRangingFBD_HR_Sign06: start 240, 8 bit, little-endian, data-type-policy=OVERRIDE, base-type=uint8, compu {phys=raw}, range phys 0..255
          signal StatusUWBRangingFBD_HR_Sign07: start 248, 8 bit, little-endian, data-type-policy=OVERRIDE, base-type=uint8, compu {phys=raw}, range phys 0..255
      frame StatusUWBRangingFBD_Miko: id 0x1B0, frame-length=32, can-addressing-mode=STANDARD, can-frame-rx-behavior=CAN-FD, can-frame-tx-behavior=CAN-FD
        pdu StatusUWBRangingFBD_Miko: length=32, unused-bit-pattern=0
          signal StatusUWBRangingFBD_Miko_SessionIDShort: start 0, 8 bit, little-endian, data-type-policy=OVERRIDE, base-type=uint8, compu {phys=raw}, range phys 0..252
          signal StatusUWBRangingFBD_Miko_TimeOfFlight: start 8, 16 bit, little-endian, data-type-policy=OVERRIDE, base-type=uint16, compu {phys=raw*15.65; unit ps}, range phys 0..1000000
          signal StatusUWBRangingFBD_Miko_RangingBlockIndex: start 24, 16 bit, little-endian, data-type-policy=OVERRIDE, base-type=uint16, compu {phys=raw}, range phys 0..65532
          signal StatusUWBRangingFBD_Miko_RangingRoundIndex: start 40, 8 bit, little-endian, data-type-policy=OVERRIDE, base-type=uint8, compu {phys=raw}, range phys 0..252
          signal StatusUWBRangingFBD_Miko_OverallReceivePower: start 48, 8 bit, little-endian, data-type-policy=OVERRIDE, base-type=uint8, compu {phys=raw*0.5-127; unit dB}, range phys -127..-1
          signal StatusUWBRangingFBD_Miko_FirstPathPower: start 56, 8 bit, little-endian, data-type-policy=OVERRIDE, base-type=uint8, compu {phys=raw*0.5-127; unit dB}, range phys -127..-1
          signal StatusUWBRangingFBD_Miko_AngleOfArrival: start 64, 8 bit, little-endian, data-type-policy=OVERRIDE, base-type=uint8, compu {phys=raw-90; unit °}, range phys -90..90
          signal StatusUWBRangingFBD_Miko_PhaseDifferenceOfArrival: start 72, 8 bit, little-endian, data-type-policy=OVERRIDE, base-type=uint8, compu {phys=raw-90; unit °}, range phys -90..90
          signal StatusUWBRangingFBD_Miko_StrongestPathPower: start 80, 8 bit, little-endian, data-type-policy=OVERRIDE, base-type=uint8, compu {phys=raw*0.5-127; unit dB}, range phys -127..-1
          signal StatusUWBRangingFBD_Miko_BLE_RSSI: start 88, 8 bit, little-endian, data-type-policy=OVERRIDE, base-type=uint8, compu {phys=raw*0.5-127; unit dB}, range phys -127..-1
          signal StatusUWBRangingFBD_Miko_StrongestPathOffset: start 96, 8 bit, little-endian, data-type-policy=OVERRIDE, base-type=uint8, compu {phys=raw*0.5; unit ns}, range phys 0..125
          signal StatusUWBRangingFBD_Miko_PDoA_SNR: start 104, 8 bit, little-endian, data-type-policy=OVERRIDE, base-type=uint8, compu {phys=raw*0.5; unit dB}, range phys 0..126
          signal StatusUWBRangingFBD_Miko_DutyCycleLimitTxCounter: start 112, 8 bit, little-endian, data-type-policy=OVERRIDE, base-type=uint8, compu {phys=raw; unit %}, range phys 0..100
          signal StatusUWBRangingFBD_Miko_FinalDataDistribution: start 120, 4 bit, little-endian, data-type-policy=OVERRIDE, base-type=uint8, compu {phys=raw}, range phys 0..12
          signal StatusUWBRangingFBD_Miko_Antenna: start 124, 4 bit, little-endian, data-type-policy=OVERRIDE, compu {phys=raw}
          signal StatusUWBRangingFBD_Miko_Status1: start 128, 8 bit, little-endian, data-type-policy=OVERRIDE, compu {phys=raw}
          signal StatusUWBRangingFBD_Miko_Status2: start 136, 8 bit, little-endian, data-type-policy=OVERRIDE, base-type=uint8, compu {phys=raw}, range phys 0..252
          signal StatusUWBRangingFBD_Miko_Status3: start 144, 8 bit, little-endian, data-type-policy=OVERRIDE, base-type=uint8, compu {phys=raw}, range phys 0..252
          signal StatusUWBRangingFBD_Miko_Status4: start 152, 8 bit, little-endian, data-type-policy=OVERRIDE, base-type=uint8, compu {phys=raw}, range phys 0..252
          signal StatusUWBRangingFBD_Miko_IV00: start 160, 8 bit, little-endian, data-type-policy=OVERRIDE, base-type=uint8, compu {phys=raw}, range phys 0..255
          signal StatusUWBRangingFBD_Miko_IV01: start 168, 8 bit, little-endian, data-type-policy=OVERRIDE, base-type=uint8, compu {phys=raw}, range phys 0..255
          signal StatusUWBRangingFBD_Miko_IV02: start 176, 8 bit, little-endian, data-type-policy=OVERRIDE, base-type=uint8, compu {phys=raw}, range phys 0..255
          signal StatusUWBRangingFBD_Miko_IV03: start 184, 8 bit, little-endian, data-type-policy=OVERRIDE, base-type=uint8, compu {phys=raw}, range phys 0..255
          signal StatusUWBRangingFBD_Miko_Sign00: start 192, 8 bit, little-endian, data-type-policy=OVERRIDE, base-type=uint8, compu {phys=raw}, range phys 0..255
          signal StatusUWBRangingFBD_Miko_Sign01: start 200, 8 bit, little-endian, data-type-policy=OVERRIDE, base-type=uint8, compu {phys=raw}, range phys 0..255
          signal StatusUWBRangingFBD_Miko_Sign02: start 208, 8 bit, little-endian, data-type-policy=OVERRIDE, base-type=uint8, compu {phys=raw}, range phys 0..255
          signal StatusUWBRangingFBD_Miko_Sign03: start 216, 8 bit, little-endian, data-type-policy=OVERRIDE, base-type=uint8, compu {phys=raw}, range phys 0..255
          signal StatusUWBRangingFBD_Miko_Sign04: start 224, 8 bit, little-endian, data-type-policy=OVERRIDE, base-type=uint8, compu {phys=raw}, range phys 0..255
          signal StatusUWBRangingFBD_Miko_Sign05: start 232, 8 bit, little-endian, data-type-policy=OVERRIDE, base-type=uint8, compu {phys=raw}, range phys 0..255
          signal StatusUWBRangingFBD_Miko_Sign06: start 240, 8 bit, little-endian, data-type-policy=OVERRIDE, base-type=uint8, compu {phys=raw}, range phys 0..255
          signal StatusUWBRangingFBD_Miko_Sign07: start 248, 8 bit, little-endian, data-type-policy=OVERRIDE, base-type=uint8, compu {phys=raw}, range phys 0..255
      frame StatusUWBRangingFBD_MM: id 0x1BB, frame-length=32, can-addressing-mode=STANDARD, can-frame-rx-behavior=CAN-FD, can-frame-tx-behavior=CAN-FD
        pdu StatusUWBRangingFBD_MM: length=32, unused-bit-pattern=0
          signal StatusUWBRangingFBD_MM_SessionIDShort: start 0, 8 bit, little-endian, data-type-policy=OVERRIDE, base-type=uint8, compu {phys=raw}, range phys 0..252
          signal StatusUWBRangingFBD_MM_TimeOfFlight: start 8, 16 bit, little-endian, data-type-policy=OVERRIDE, base-type=uint16, compu {phys=raw*15.65; unit ps}, range phys 0..1000000
          signal StatusUWBRangingFBD_MM_RangingBlockIndex: start 24, 16 bit, little-endian, data-type-policy=OVERRIDE, base-type=uint16, compu {phys=raw}, range phys 0..65532
          signal StatusUWBRangingFBD_MM_RangingRoundIndex: start 40, 8 bit, little-endian, data-type-policy=OVERRIDE, base-type=uint8, compu {phys=raw}, range phys 0..252
          signal StatusUWBRangingFBD_MM_OverallReceivePower: start 48, 8 bit, little-endian, data-type-policy=OVERRIDE, base-type=uint8, compu {phys=raw*0.5-127; unit dB}, range phys -127..-1
          signal StatusUWBRangingFBD_MM_FirstPathPower: start 56, 8 bit, little-endian, data-type-policy=OVERRIDE, base-type=uint8, compu {phys=raw*0.5-127; unit dB}, range phys -127..-1
          signal StatusUWBRangingFBD_MM_AngleOfArrival: start 64, 8 bit, little-endian, data-type-policy=OVERRIDE, base-type=uint8, compu {phys=raw-90; unit °}, range phys -90..90
          signal StatusUWBRangingFBD_MM_PhaseDifferenceOfArrival: start 72, 8 bit, little-endian, data-type-policy=OVERRIDE, base-type=uint8, compu {phys=raw-90; unit °}, range phys -90..90
          signal StatusUWBRangingFBD_MM_StrongestPathPower: start 80, 8 bit, little-endian, data-type-policy=OVERRIDE, base-type=uint8, compu {phys=raw*0.5-127; unit dB}, range phys -127..-1
          signal StatusUWBRangingFBD_MM_BLE_RSSI: start 88, 8 bit, little-endian, data-type-policy=OVERRIDE, base-type=uint8, compu {phys=raw*0.5-127; unit dB}, range phys -127..-1
          signal StatusUWBRangingFBD_MM_StrongestPathOffset: start 96, 8 bit, little-endian, data-type-policy=OVERRIDE, base-type=uint8, compu {phys=raw*0.5; unit ns}, range phys 0..125
          signal StatusUWBRangingFBD_MM_PDoA_SNR: start 104, 8 bit, little-endian, data-type-policy=OVERRIDE, base-type=uint8, compu {phys=raw*0.5; unit dB}, range phys 0..126
          signal StatusUWBRangingFBD_MM_DutyCycleLimitTxCounter: start 112, 8 bit, little-endian, data-type-policy=OVERRIDE, base-type=uint8, compu {phys=raw; unit %}, range phys 0..100
          signal StatusUWBRangingFBD_MM_FinalDataDistribution: start 120, 4 bit, little-endian, data-type-policy=OVERRIDE, base-type=uint8, compu {phys=raw}, range phys 0..12
          signal StatusUWBRangingFBD_MM_Antenna: start 124, 4 bit, little-endian, data-type-policy=OVERRIDE, compu {phys=raw}
          signal StatusUWBRangingFBD_MM_Status1: start 128, 8 bit, little-endian, data-type-policy=OVERRIDE, compu {phys=raw}
          signal StatusUWBRangingFBD_MM_Status2: start 136, 8 bit, little-endian, data-type-policy=OVERRIDE, base-type=uint8, compu {phys=raw}, range phys 0..252
          signal StatusUWBRangingFBD_MM_Status3: start 144, 8 bit, little-endian, data-type-policy=OVERRIDE, base-type=uint8, compu {phys=raw}, range phys 0..252
          signal StatusUWBRangingFBD_MM_Status4: start 152, 8 bit, little-endian, data-type-policy=OVERRIDE, base-type=uint8, compu {phys=raw}, range phys 0..252
          signal StatusUWBRangingFBD_MM_IV00: start 160, 8 bit, little-endian, data-type-policy=OVERRIDE, base-type=uint8, compu {phys=raw}, range phys 0..255
          signal StatusUWBRangingFBD_MM_IV01: start 168, 8 bit, little-endian, data-type-policy=OVERRIDE, base-type=uint8, compu {phys=raw}, range phys 0..255
          signal StatusUWBRangingFBD_MM_IV02: start 176, 8 bit, little-endian, data-type-policy=OVERRIDE, base-type=uint8, compu {phys=raw}, range phys 0..255
          signal StatusUWBRangingFBD_MM_IV03: start 184, 8 bit, little-endian, data-type-policy=OVERRIDE, base-type=uint8, compu {phys=raw}, range phys 0..255
          signal StatusUWBRangingFBD_MM_Sign00: start 192, 8 bit, little-endian, data-type-policy=OVERRIDE, base-type=uint8, compu {phys=raw}, range phys 0..255
          signal StatusUWBRangingFBD_MM_Sign01: start 200, 8 bit, little-endian, data-type-policy=OVERRIDE, base-type=uint8, compu {phys=raw}, range phys 0..255
          signal StatusUWBRangingFBD_MM_Sign02: start 208, 8 bit, little-endian, data-type-policy=OVERRIDE, base-type=uint8, compu {phys=raw}, range phys 0..255
          signal StatusUWBRangingFBD_MM_Sign03: start 216, 8 bit, little-endian, data-type-policy=OVERRIDE, base-type=uint8, compu {phys=raw}, range phys 0..255
          signal StatusUWBRangingFBD_MM_Sign04: start 224, 8 bit, little-endian, data-type-policy=OVERRIDE, base-type=uint8, compu {phys=raw}, range phys 0..255
          signal StatusUWBRangingFBD_MM_Sign05: start 232, 8 bit, little-endian, data-type-policy=OVERRIDE, base-type=uint8, compu {phys=raw}, range phys 0..255
          signal StatusUWBRangingFBD_MM_Sign06: start 240, 8 bit, little-endian, data-type-policy=OVERRIDE, base-type=uint8, compu {phys=raw}, range phys 0..255
          signal StatusUWBRangingFBD_MM_Sign07: start 248, 8 bit, little-endian, data-type-policy=OVERRIDE, base-type=uint8, compu {phys=raw}, range phys 0..255
      frame StatusUWBRangingFBD_SML: id 0x1B6, frame-length=32, can-addressing-mode=STANDARD, can-frame-rx-behavior=CAN-FD, can-frame-tx-behavior=CAN-FD
        pdu StatusUWBRangingFBD_SML: length=32, unused-bit-pattern=0
          signal StatusUWBRangingFBD_SML_SessionIDShort: start 0, 8 bit, little-endian, data-type-policy=OVERRIDE, base-type=uint8, compu {phys=raw}, range phys 0..252
          signal StatusUWBRangingFBD_SML_TimeOfFlight: start 8, 16 bit, little-endian, data-type-policy=OVERRIDE, base-type=uint16, compu {phys=raw*15.65; unit ps}, range phys 0..1000000
          signal StatusUWBRangingFBD_SML_RangingBlockIndex: start 24, 16 bit, little-endian, data-type-policy=OVERRIDE, base-type=uint16, compu {phys=raw}, range phys 0..65532
          signal StatusUWBRangingFBD_SML_RangingRoundIndex: start 40, 8 bit, little-endian, data-type-policy=OVERRIDE, base-type=uint8, compu {phys=raw}, range phys 0..252
          signal StatusUWBRangingFBD_SML_OverallReceivePower: start 48, 8 bit, little-endian, data-type-policy=OVERRIDE, base-type=uint8, compu {phys=raw*0.5-127; unit dB}, range phys -127..-1
          signal StatusUWBRangingFBD_SML_FirstPathPower: start 56, 8 bit, little-endian, data-type-policy=OVERRIDE, base-type=uint8, compu {phys=raw*0.5-127; unit dB}, range phys -127..-1
          signal StatusUWBRangingFBD_SML_AngleOfArrival: start 64, 8 bit, little-endian, data-type-policy=OVERRIDE, base-type=uint8, compu {phys=raw-90; unit °}, range phys -90..90
          signal StatusUWBRangingFBD_SML_PhaseDifferenceOfArrival: start 72, 8 bit, little-endian, data-type-policy=OVERRIDE, base-type=uint8, compu {phys=raw-90; unit °}, range phys -90..90
          signal StatusUWBRangingFBD_SML_StrongestPathPower: start 80, 8 bit, little-endian, data-type-policy=OVERRIDE, base-type=uint8, compu {phys=raw*0.5-127; unit dB}, range phys -127..-1
          signal StatusUWBRangingFBD_SML_BLE_RSSI: start 88, 8 bit, little-endian, data-type-policy=OVERRIDE, base-type=uint8, compu {phys=raw*0.5-127; unit dB}, range phys -127..-1
          signal StatusUWBRangingFBD_SML_StrongestPathOffset: start 96, 8 bit, little-endian, data-type-policy=OVERRIDE, base-type=uint8, compu {phys=raw*0.5; unit ns}, range phys 0..125
          signal StatusUWBRangingFBD_SML_PDoA_SNR: start 104, 8 bit, little-endian, data-type-policy=OVERRIDE, base-type=uint8, compu {phys=raw*0.5; unit dB}, range phys 0..126
          signal StatusUWBRangingFBD_SML_DutyCycleLimitTxCounter: start 112, 8 bit, little-endian, data-type-policy=OVERRIDE, base-type=uint8, compu {phys=raw; unit %}, range phys 0..100
          signal StatusUWBRangingFBD_SML_FinalDataDistribution: start 120, 4 bit, little-endian, data-type-policy=OVERRIDE, base-type=uint8, compu {phys=raw}, range phys 0..12
          signal StatusUWBRangingFBD_SML_Antenna: start 124, 4 bit, little-endian, data-type-policy=OVERRIDE, compu {phys=raw}
          signal StatusUWBRangingFBD_SML_Status1: start 128, 8 bit, little-endian, data-type-policy=OVERRIDE, compu {phys=raw}
          signal StatusUWBRangingFBD_SML_Status2: start 136, 8 bit, little-endian, data-type-policy=OVERRIDE, base-type=uint8, compu {phys=raw}, range phys 0..252
          signal StatusUWBRangingFBD_SML_Status3: start 144, 8 bit, little-endian, data-type-policy=OVERRIDE, base-type=uint8, compu {phys=raw}, range phys 0..252
          signal StatusUWBRangingFBD_SML_Status4: start 152, 8 bit, little-endian, data-type-policy=OVERRIDE, base-type=uint8, compu {phys=raw}, range phys 0..252
          signal StatusUWBRangingFBD_SML_IV00: start 160, 8 bit, little-endian, data-type-policy=OVERRIDE, base-type=uint8, compu {phys=raw}, range phys 0..255
          signal StatusUWBRangingFBD_SML_IV01: start 168, 8 bit, little-endian, data-type-policy=OVERRIDE, base-type=uint8, compu {phys=raw}, range phys 0..255
          signal StatusUWBRangingFBD_SML_IV02: start 176, 8 bit, little-endian, data-type-policy=OVERRIDE, base-type=uint8, compu {phys=raw}, range phys 0..255
          signal StatusUWBRangingFBD_SML_IV03: start 184, 8 bit, little-endian, data-type-policy=OVERRIDE, base-type=uint8, compu {phys=raw}, range phys 0..255
          signal StatusUWBRangingFBD_SML_Sign00: start 192, 8 bit, little-endian, data-type-policy=OVERRIDE, base-type=uint8, compu {phys=raw}, range phys 0..255
          signal StatusUWBRangingFBD_SML_Sign01: start 200, 8 bit, little-endian, data-type-policy=OVERRIDE, base-type=uint8, compu {phys=raw}, range phys 0..255
          signal StatusUWBRangingFBD_SML_Sign02: start 208, 8 bit, little-endian, data-type-policy=OVERRIDE, base-type=uint8, compu {phys=raw}, range phys 0..255
          signal StatusUWBRangingFBD_SML_Sign03: start 216, 8 bit, little-endian, data-type-policy=OVERRIDE, base-type=uint8, compu {phys=raw}, range phys 0..255
          signal StatusUWBRangingFBD_SML_Sign04: start 224, 8 bit, little-endian, data-type-policy=OVERRIDE, base-type=uint8, compu {phys=raw}, range phys 0..255
          signal StatusUWBRangingFBD_SML_Sign05: start 232, 8 bit, little-endian, data-type-policy=OVERRIDE, base-type=uint8, compu {phys=raw}, range phys 0..255
          signal StatusUWBRangingFBD_SML_Sign06: start 240, 8 bit, little-endian, data-type-policy=OVERRIDE, base-type=uint8, compu {phys=raw}, range phys 0..255
          signal StatusUWBRangingFBD_SML_Sign07: start 248, 8 bit, little-endian, data-type-policy=OVERRIDE, base-type=uint8, compu {phys=raw}, range phys 0..255
      frame StatusUWBRangingFBD_SMR: id 0x1B7, frame-length=32, can-addressing-mode=STANDARD, can-frame-rx-behavior=CAN-FD, can-frame-tx-behavior=CAN-FD
        pdu StatusUWBRangingFBD_SMR: length=32, unused-bit-pattern=0
          signal StatusUWBRangingFBD_SMR_SessionIDShort: start 0, 8 bit, little-endian, data-type-policy=OVERRIDE, base-type=uint8, compu {phys=raw}, range phys 0..252
          signal StatusUWBRangingFBD_SMR_TimeOfFlight: start 8, 16 bit, little-endian, data-type-policy=OVERRIDE, base-type=uint16, compu {phys=raw*15.65; unit ps}, range phys 0..1000000
          signal StatusUWBRangingFBD_SMR_RangingBlockIndex: start 24, 16 bit, little-endian, data-type-policy=OVERRIDE, base-type=uint16, compu {phys=raw}, range phys 0..65532
          signal StatusUWBRangingFBD_SMR_RangingRoundIndex: start 40, 8 bit, little-endian, data-type-policy=OVERRIDE, base-type=uint8, compu {phys=raw}, range phys 0..252
          signal StatusUWBRangingFBD_SMR_OverallReceivePower: start 48, 8 bit, little-endian, data-type-policy=OVERRIDE, base-type=uint8, compu {phys=raw*0.5-127; unit dB}, range phys -127..-1
          signal StatusUWBRangingFBD_SMR_FirstPathPower: start 56, 8 bit, little-endian, data-type-policy=OVERRIDE, base-type=uint8, compu {phys=raw*0.5-127; unit dB}, range phys -127..-1
          signal StatusUWBRangingFBD_SMR_AngleOfArrival: start 64, 8 bit, little-endian, data-type-policy=OVERRIDE, base-type=uint8, compu {phys=raw-90; unit °}, range phys -90..90
          signal StatusUWBRangingFBD_SMR_PhaseDifferenceOfArrival: start 72, 8 bit, little-endian, data-type-policy=OVERRIDE, base-type=uint8, compu {phys=raw-90; unit °}, range phys -90..90
          signal StatusUWBRangingFBD_SMR_StrongestPathPower: start 80, 8 bit, little-endian, data-type-policy=OVERRIDE, base-type=uint8, compu {phys=raw*0.5-127; unit dB}, range phys -127..-1
          signal StatusUWBRangingFBD_SMR_BLE_RSSI: start 88, 8 bit, little-endian, data-type-policy=OVERRIDE, base-type=uint8, compu {phys=raw*0.5-127; unit dB}, range phys -127..-1
          signal StatusUWBRangingFBD_SMR_StrongestPathOffset: start 96, 8 bit, little-endian, data-type-policy=OVERRIDE, base-type=uint8, compu {phys=raw*0.5; unit ns}, range phys 0..125
          signal StatusUWBRangingFBD_SMR_PDoA_SNR: start 104, 8 bit, little-endian, data-type-policy=OVERRIDE, base-type=uint8, compu {phys=raw*0.5; unit dB}, range phys 0..126
          signal StatusUWBRangingFBD_SMR_DutyCycleLimitTxCounter: start 112, 8 bit, little-endian, data-type-policy=OVERRIDE, base-type=uint8, compu {phys=raw; unit %}, range phys 0..100
          signal StatusUWBRangingFBD_SMR_FinalDataDistribution: start 120, 4 bit, little-endian, data-type-policy=OVERRIDE, base-type=uint8, compu {phys=raw}, range phys 0..12
          signal StatusUWBRangingFBD_SMR_Antenna: start 124, 4 bit, little-endian, data-type-policy=OVERRIDE, compu {phys=raw}
          signal StatusUWBRangingFBD_SMR_Status1: start 128, 8 bit, little-endian, data-type-policy=OVERRIDE, compu {phys=raw}
          signal StatusUWBRangingFBD_SMR_Status2: start 136, 8 bit, little-endian, data-type-policy=OVERRIDE, base-type=uint8, compu {phys=raw}, range phys 0..252
          signal StatusUWBRangingFBD_SMR_Status3: start 144, 8 bit, little-endian, data-type-policy=OVERRIDE, base-type=uint8, compu {phys=raw}, range phys 0..252
          signal StatusUWBRangingFBD_SMR_Status4: start 152, 8 bit, little-endian, data-type-policy=OVERRIDE, base-type=uint8, compu {phys=raw}, range phys 0..252
          signal StatusUWBRangingFBD_SMR_IV00: start 160, 8 bit, little-endian, data-type-policy=OVERRIDE, base-type=uint8, compu {phys=raw}, range phys 0..255
          signal StatusUWBRangingFBD_SMR_IV01: start 168, 8 bit, little-endian, data-type-policy=OVERRIDE, base-type=uint8, compu {phys=raw}, range phys 0..255
          signal StatusUWBRangingFBD_SMR_IV02: start 176, 8 bit, little-endian, data-type-policy=OVERRIDE, base-type=uint8, compu {phys=raw}, range phys 0..255
          signal StatusUWBRangingFBD_SMR_IV03: start 184, 8 bit, little-endian, data-type-policy=OVERRIDE, base-type=uint8, compu {phys=raw}, range phys 0..255
          signal StatusUWBRangingFBD_SMR_Sign00: start 192, 8 bit, little-endian, data-type-policy=OVERRIDE, base-type=uint8, compu {phys=raw}, range phys 0..255
          signal StatusUWBRangingFBD_SMR_Sign01: start 200, 8 bit, little-endian, data-type-policy=OVERRIDE, base-type=uint8, compu {phys=raw}, range phys 0..255
          signal StatusUWBRangingFBD_SMR_Sign02: start 208, 8 bit, little-endian, data-type-policy=OVERRIDE, base-type=uint8, compu {phys=raw}, range phys 0..255
          signal StatusUWBRangingFBD_SMR_Sign03: start 216, 8 bit, little-endian, data-type-policy=OVERRIDE, base-type=uint8, compu {phys=raw}, range phys 0..255
          signal StatusUWBRangingFBD_SMR_Sign04: start 224, 8 bit, little-endian, data-type-policy=OVERRIDE, base-type=uint8, compu {phys=raw}, range phys 0..255
          signal StatusUWBRangingFBD_SMR_Sign05: start 232, 8 bit, little-endian, data-type-policy=OVERRIDE, base-type=uint8, compu {phys=raw}, range phys 0..255
          signal StatusUWBRangingFBD_SMR_Sign06: start 240, 8 bit, little-endian, data-type-policy=OVERRIDE, base-type=uint8, compu {phys=raw}, range phys 0..255
          signal StatusUWBRangingFBD_SMR_Sign07: start 248, 8 bit, little-endian, data-type-policy=OVERRIDE, base-type=uint8, compu {phys=raw}, range phys 0..255
      frame StatusUWBRangingFBD_Trunk: id 0x1B1, frame-length=32, can-addressing-mode=STANDARD, can-frame-rx-behavior=CAN-FD, can-frame-tx-behavior=CAN-FD
        pdu StatusUWBRangingFBD_Trunk: length=32, unused-bit-pattern=0
          signal StatusUWBRangingFBD_Trunk_SessionIDShort: start 0, 8 bit, little-endian, data-type-policy=OVERRIDE, base-type=uint8, compu {phys=raw}, range phys 0..252
          signal StatusUWBRangingFBD_Trunk_TimeOfFlight: start 8, 16 bit, little-endian, data-type-policy=OVERRIDE, base-type=uint16, compu {phys=raw*15.65; unit ps}, range phys 0..1000000
          signal StatusUWBRangingFBD_Trunk_RangingBlockIndex: start 24, 16 bit, little-endian, data-type-policy=OVERRIDE, base-type=uint16, compu {phys=raw}, range phys 0..65532
          signal StatusUWBRangingFBD_Trunk_RangingRoundIndex: start 40, 8 bit, little-endian, data-type-policy=OVERRIDE, base-type=uint8, compu {phys=raw}, range phys 0..252
          signal StatusUWBRangingFBD_Trunk_OverallReceivePower: start 48, 8 bit, little-endian, data-type-policy=OVERRIDE, base-type=uint8, compu {phys=raw*0.5-127; unit dB}, range phys -127..-1
          signal StatusUWBRangingFBD_Trunk_FirstPathPower: start 56, 8 bit, little-endian, data-type-policy=OVERRIDE, base-type=uint8, compu {phys=raw*0.5-127; unit dB}, range phys -127..-1
          signal StatusUWBRangingFBD_Trunk_AngleOfArrival: start 64, 8 bit, little-endian, data-type-policy=OVERRIDE, base-type=uint8, compu {phys=raw-90; unit °}, range phys -90..90
          signal StatusUWBRangingFBD_Trunk_PhaseDifferenceOfArrival: start 72, 8 bit, little-endian, data-type-policy=OVERRIDE, base-type=uint8, compu {phys=raw-90; unit °}, range phys -90..90
          signal StatusUWBRangingFBD_Trunk_StrongestPathPower: start 80, 8 bit, little-endian, data-type-policy=OVERRIDE, base-type=uint8, compu {phys=raw*0.5-127; unit dB}, range phys -127..-1
          signal StatusUWBRangingFBD_Trunk_BLE_RSSI: start 88, 8 bit, little-endian, data-type-policy=OVERRIDE, base-type=uint8, compu {phys=raw*0.5-127; unit dB}, range phys -127..-1
          signal StatusUWBRangingFBD_Trunk_StrongestPathOffset: start 96, 8 bit, little-endian, data-type-policy=OVERRIDE, base-type=uint8, compu {phys=raw*0.5; unit ns}, range phys 0..125
          signal StatusUWBRangingFBD_Trunk_PDoA_SNR: start 104, 8 bit, little-endian, data-type-policy=OVERRIDE, base-type=uint8, compu {phys=raw*0.5; unit dB}, range phys 0..126
          signal StatusUWBRangingFBD_Trunk_DutyCycleLimitTxCounter: start 112, 8 bit, little-endian, data-type-policy=OVERRIDE, base-type=uint8, compu {phys=raw; unit %}, range phys 0..100
          signal StatusUWBRangingFBD_Trunk_FinalDataDistribution: start 120, 4 bit, little-endian, data-type-policy=OVERRIDE, base-type=uint8, compu {phys=raw}, range phys 0..12
          signal StatusUWBRangingFBD_Trunk_Antenna: start 124, 4 bit, little-endian, data-type-policy=OVERRIDE, compu {phys=raw}
          signal StatusUWBRangingFBD_Trunk_Status1: start 128, 8 bit, little-endian, data-type-policy=OVERRIDE, compu {phys=raw}
          signal StatusUWBRangingFBD_Trunk_Status2: start 136, 8 bit, little-endian, data-type-policy=OVERRIDE, base-type=uint8, compu {phys=raw}, range phys 0..252
          signal StatusUWBRangingFBD_Trunk_Status3: start 144, 8 bit, little-endian, data-type-policy=OVERRIDE, base-type=uint8, compu {phys=raw}, range phys 0..252
          signal StatusUWBRangingFBD_Trunk_Status4: start 152, 8 bit, little-endian, data-type-policy=OVERRIDE, base-type=uint8, compu {phys=raw}, range phys 0..252
          signal StatusUWBRangingFBD_Trunk_IV00: start 160, 8 bit, little-endian, data-type-policy=OVERRIDE, base-type=uint8, compu {phys=raw}, range phys 0..255
          signal StatusUWBRangingFBD_Trunk_IV01: start 168, 8 bit, little-endian, data-type-policy=OVERRIDE, base-type=uint8, compu {phys=raw}, range phys 0..255
          signal StatusUWBRangingFBD_Trunk_IV02: start 176, 8 bit, little-endian, data-type-policy=OVERRIDE, base-type=uint8, compu {phys=raw}, range phys 0..255
          signal StatusUWBRangingFBD_Trunk_IV03: start 184, 8 bit, little-endian, data-type-policy=OVERRIDE, base-type=uint8, compu {phys=raw}, range phys 0..255
          signal StatusUWBRangingFBD_Trunk_Sign00: start 192, 8 bit, little-endian, data-type-policy=OVERRIDE, base-type=uint8, compu {phys=raw}, range phys 0..255
          signal StatusUWBRangingFBD_Trunk_Sign01: start 200, 8 bit, little-endian, data-type-policy=OVERRIDE, base-type=uint8, compu {phys=raw}, range phys 0..255
          signal StatusUWBRangingFBD_Trunk_Sign02: start 208, 8 bit, little-endian, data-type-policy=OVERRIDE, base-type=uint8, compu {phys=raw}, range phys 0..255
          signal StatusUWBRangingFBD_Trunk_Sign03: start 216, 8 bit, little-endian, data-type-policy=OVERRIDE, base-type=uint8, compu {phys=raw}, range phys 0..255
          signal StatusUWBRangingFBD_Trunk_Sign04: start 224, 8 bit, little-endian, data-type-policy=OVERRIDE, base-type=uint8, compu {phys=raw}, range phys 0..255
          signal StatusUWBRangingFBD_Trunk_Sign05: start 232, 8 bit, little-endian, data-type-policy=OVERRIDE, base-type=uint8, compu {phys=raw}, range phys 0..255
          signal StatusUWBRangingFBD_Trunk_Sign06: start 240, 8 bit, little-endian, data-type-policy=OVERRIDE, base-type=uint8, compu {phys=raw}, range phys 0..255
          signal StatusUWBRangingFBD_Trunk_Sign07: start 248, 8 bit, little-endian, data-type-policy=OVERRIDE, base-type=uint8, compu {phys=raw}, range phys 0..255
      frame StatusUWBRangingFBD_VL: id 0x1B2, frame-length=32, can-addressing-mode=STANDARD, can-frame-rx-behavior=CAN-FD, can-frame-tx-behavior=CAN-FD
        pdu StatusUWBRangingFBD_VL: length=32, unused-bit-pattern=0
          signal StatusUWBRangingFBD_VL_SessionIDShort: start 0, 8 bit, little-endian, data-type-policy=OVERRIDE, base-type=uint8, compu {phys=raw}, range phys 0..252
          signal StatusUWBRangingFBD_VL_TimeOfFlight: start 8, 16 bit, little-endian, data-type-policy=OVERRIDE, base-type=uint16, compu {phys=raw*15.65; unit ps}, range phys 0..1000000
          signal StatusUWBRangingFBD_VL_RangingBlockIndex: start 24, 16 bit, little-endian, data-type-policy=OVERRIDE, base-type=uint16, compu {phys=raw}, range phys 0..65532
          signal StatusUWBRangingFBD_VL_RangingRoundIndex: start 40, 8 bit, little-endian, data-type-policy=OVERRIDE, base-type=uint8, compu {phys=raw}, range phys 0..252
          signal StatusUWBRangingFBD_VL_OverallReceivePower: start 48, 8 bit, little-endian, data-type-policy=OVERRIDE, base-type=uint8, compu {phys=raw*0.5-127; unit dB}, range phys -127..-1
          signal StatusUWBRangingFBD_VL_FirstPathPower: start 56, 8 bit, little-endian, data-type-policy=OVERRIDE, base-type=uint8, compu {phys=raw*0.5-127; unit dB}, range phys -127..-1
          signal StatusUWBRangingFBD_VL_AngleOfArrival: start 64, 8 bit, little-endian, data-type-policy=OVERRIDE, base-type=uint8, compu {phys=raw-90; unit °}, range phys -90..90
          signal StatusUWBRangingFBD_VL_PhaseDifferenceOfArrival: start 72, 8 bit, little-endian, data-type-policy=OVERRIDE, base-type=uint8, compu {phys=raw-90; unit °}, range phys -90..90
          signal StatusUWBRangingFBD_VL_StrongestPathPower: start 80, 8 bit, little-endian, data-type-policy=OVERRIDE, base-type=uint8, compu {phys=raw*0.5-127; unit dB}, range phys -127..-1
          signal StatusUWBRangingFBD_VL_BLE_RSSI: start 88, 8 bit, little-endian, data-type-policy=OVERRIDE, base-type=uint8, compu {phys=raw*0.5-127; unit dB}, range phys -127..-1
          signal StatusUWBRangingFBD_VL_StrongestPathOffset: start 96, 8 bit, little-endian, data-type-policy=OVERRIDE, base-type=uint8, compu {phys=raw*0.5; unit ns}, range phys 0..125
          signal StatusUWBRangingFBD_VL_PDoA_SNR: start 104, 8 bit, little-endian, data-type-policy=OVERRIDE, base-type=uint8, compu {phys=raw*0.5; unit dB}, range phys 0..126
          signal StatusUWBRangingFBD_VL_DutyCycleLimitTxCounter: start 112, 8 bit, little-endian, data-type-policy=OVERRIDE, base-type=uint8, compu {phys=raw; unit %}, range phys 0..100
          signal StatusUWBRangingFBD_VL_FinalDataDistribution: start 120, 4 bit, little-endian, data-type-policy=OVERRIDE, base-type=uint8, compu {phys=raw}, range phys 0..12
          signal StatusUWBRangingFBD_VL_Antenna: start 124, 4 bit, little-endian, data-type-policy=OVERRIDE, compu {phys=raw}
          signal StatusUWBRangingFBD_VL_Status1: start 128, 8 bit, little-endian, data-type-policy=OVERRIDE, compu {phys=raw}
          signal StatusUWBRangingFBD_VL_Status2: start 136, 8 bit, little-endian, data-type-policy=OVERRIDE, base-type=uint8, compu {phys=raw}, range phys 0..252
          signal StatusUWBRangingFBD_VL_Status3: start 144, 8 bit, little-endian, data-type-policy=OVERRIDE, base-type=uint8, compu {phys=raw}, range phys 0..252
          signal StatusUWBRangingFBD_VL_Status4: start 152, 8 bit, little-endian, data-type-policy=OVERRIDE, base-type=uint8, compu {phys=raw}, range phys 0..252
          signal StatusUWBRangingFBD_VL_IV00: start 160, 8 bit, little-endian, data-type-policy=OVERRIDE, base-type=uint8, compu {phys=raw}, range phys 0..255
          signal StatusUWBRangingFBD_VL_IV01: start 168, 8 bit, little-endian, data-type-policy=OVERRIDE, base-type=uint8, compu {phys=raw}, range phys 0..255
          signal StatusUWBRangingFBD_VL_IV02: start 176, 8 bit, little-endian, data-type-policy=OVERRIDE, base-type=uint8, compu {phys=raw}, range phys 0..255
          signal StatusUWBRangingFBD_VL_IV03: start 184, 8 bit, little-endian, data-type-policy=OVERRIDE, base-type=uint8, compu {phys=raw}, range phys 0..255
          signal StatusUWBRangingFBD_VL_Sign00: start 192, 8 bit, little-endian, data-type-policy=OVERRIDE, base-type=uint8, compu {phys=raw}, range phys 0..255
          signal StatusUWBRangingFBD_VL_Sign01: start 200, 8 bit, little-endian, data-type-policy=OVERRIDE, base-type=uint8, compu {phys=raw}, range phys 0..255
          signal StatusUWBRangingFBD_VL_Sign02: start 208, 8 bit, little-endian, data-type-policy=OVERRIDE, base-type=uint8, compu {phys=raw}, range phys 0..255
          signal StatusUWBRangingFBD_VL_Sign03: start 216, 8 bit, little-endian, data-type-policy=OVERRIDE, base-type=uint8, compu {phys=raw}, range phys 0..255
          signal StatusUWBRangingFBD_VL_Sign04: start 224, 8 bit, little-endian, data-type-policy=OVERRIDE, base-type=uint8, compu {phys=raw}, range phys 0..255
          signal StatusUWBRangingFBD_VL_Sign05: start 232, 8 bit, little-endian, data-type-policy=OVERRIDE, base-type=uint8, compu {phys=raw}, range phys 0..255
          signal StatusUWBRangingFBD_VL_Sign06: start 240, 8 bit, little-endian, data-type-policy=OVERRIDE, base-type=uint8, compu {phys=raw}, range phys 0..255
          signal StatusUWBRangingFBD_VL_Sign07: start 248, 8 bit, little-endian, data-type-policy=OVERRIDE, base-type=uint8, compu {phys=raw}, range phys 0..255
      frame StatusUWBRangingFBD_VM: id 0x1AE, frame-length=32, can-addressing-mode=STANDARD, can-frame-rx-behavior=CAN-FD, can-frame-tx-behavior=CAN-FD
        pdu StatusUWBRangingFBD_VM: length=32, unused-bit-pattern=0
          signal StatusUWBRangingFBD_VM_SessionIDShort: start 0, 8 bit, little-endian, data-type-policy=OVERRIDE, base-type=uint8, compu {phys=raw}, range phys 0..252
          signal StatusUWBRangingFBD_VM_TimeOfFlight: start 8, 16 bit, little-endian, data-type-policy=OVERRIDE, base-type=uint16, compu {phys=raw*15.65; unit ps}, range phys 0..1000000
          signal StatusUWBRangingFBD_VM_RangingBlockIndex: start 24, 16 bit, little-endian, data-type-policy=OVERRIDE, base-type=uint16, compu {phys=raw}, range phys 0..65532
          signal StatusUWBRangingFBD_VM_RangingRoundIndex: start 40, 8 bit, little-endian, data-type-policy=OVERRIDE, base-type=uint8, compu {phys=raw}, range phys 0..252
          signal StatusUWBRangingFBD_VM_OverallReceivePower: start 48, 8 bit, little-endian, data-type-policy=OVERRIDE, base-type=uint8, compu {phys=raw*0.5-127; unit dB}, range phys -127..-1
          signal StatusUWBRangingFBD_VM_FirstPathPower: start 56, 8 bit, little-endian, data-type-policy=OVERRIDE, base-type=uint8, compu {phys=raw*0.5-127; unit dB}, range phys -127..-1
          signal StatusUWBRangingFBD_VM_AngleOfArrival: start 64, 8 bit, little-endian, data-type-policy=OVERRIDE, base-type=uint8, compu {phys=raw-90; unit °}, range phys -90..90
          signal StatusUWBRangingFBD_VM_PhaseDifferenceOfArrival: start 72, 8 bit, little-endian, data-type-policy=OVERRIDE, base-type=uint8, compu {phys=raw-90; unit °}, range phys -90..90
          signal StatusUWBRangingFBD_VM_StrongestPathPower: start 80, 8 bit, little-endian, data-type-policy=OVERRIDE, base-type=uint8, compu {phys=raw*0.5-127; unit dB}, range phys -127..-1
          signal StatusUWBRangingFBD_VM_BLE_RSSI: start 88, 8 bit, little-endian, data-type-policy=OVERRIDE, base-type=uint8, compu {phys=raw*0.5-127; unit dB}, range phys -127..-1
          signal StatusUWBRangingFBD_VM_StrongestPathOffset: start 96, 8 bit, little-endian, data-type-policy=OVERRIDE, base-type=uint8, compu {phys=raw*0.5; unit ns}, range phys 0..125
          signal StatusUWBRangingFBD_VM_PDoA_SNR: start 104, 8 bit, little-endian, data-type-policy=OVERRIDE, base-type=uint8, compu {phys=raw*0.5; unit dB}, range phys 0..126
          signal StatusUWBRangingFBD_VM_DutyCycleLimitTxCounter: start 112, 8 bit, little-endian, data-type-policy=OVERRIDE, base-type=uint8, compu {phys=raw; unit %}, range phys 0..100
          signal StatusUWBRangingFBD_VM_FinalDataDistribution: start 120, 4 bit, little-endian, data-type-policy=OVERRIDE, base-type=uint8, compu {phys=raw}, range phys 0..12
          signal StatusUWBRangingFBD_VM_Antenna: start 124, 4 bit, little-endian, data-type-policy=OVERRIDE, compu {phys=raw}
          signal StatusUWBRangingFBD_VM_Status1: start 128, 8 bit, little-endian, data-type-policy=OVERRIDE, compu {phys=raw}
          signal StatusUWBRangingFBD_VM_Status2: start 136, 8 bit, little-endian, data-type-policy=OVERRIDE, base-type=uint8, compu {phys=raw}, range phys 0..252
          signal StatusUWBRangingFBD_VM_Status3: start 144, 8 bit, little-endian, data-type-policy=OVERRIDE, base-type=uint8, compu {phys=raw}, range phys 0..252
          signal StatusUWBRangingFBD_VM_Status4: start 152, 8 bit, little-endian, data-type-policy=OVERRIDE, base-type=uint8, compu {phys=raw}, range phys 0..252
          signal StatusUWBRangingFBD_VM_IV00: start 160, 8 bit, little-endian, data-type-policy=OVERRIDE, base-type=uint8, compu {phys=raw}, range phys 0..255
          signal StatusUWBRangingFBD_VM_IV01: start 168, 8 bit, little-endian, data-type-policy=OVERRIDE, base-type=uint8, compu {phys=raw}, range phys 0..255
          signal StatusUWBRangingFBD_VM_IV02: start 176, 8 bit, little-endian, data-type-policy=OVERRIDE, base-type=uint8, compu {phys=raw}, range phys 0..255
          signal StatusUWBRangingFBD_VM_IV03: start 184, 8 bit, little-endian, data-type-policy=OVERRIDE, base-type=uint8, compu {phys=raw}, range phys 0..255
          signal StatusUWBRangingFBD_VM_Sign00: start 192, 8 bit, little-endian, data-type-policy=OVERRIDE, base-type=uint8, compu {phys=raw}, range phys 0..255
          signal StatusUWBRangingFBD_VM_Sign01: start 200, 8 bit, little-endian, data-type-policy=OVERRIDE, base-type=uint8, compu {phys=raw}, range phys 0..255
          signal StatusUWBRangingFBD_VM_Sign02: start 208, 8 bit, little-endian, data-type-policy=OVERRIDE, base-type=uint8, compu {phys=raw}, range phys 0..255
          signal StatusUWBRangingFBD_VM_Sign03: start 216, 8 bit, little-endian, data-type-policy=OVERRIDE, base-type=uint8, compu {phys=raw}, range phys 0..255
          signal StatusUWBRangingFBD_VM_Sign04: start 224, 8 bit, little-endian, data-type-policy=OVERRIDE, base-type=uint8, compu {phys=raw}, range phys 0..255
          signal StatusUWBRangingFBD_VM_Sign05: start 232, 8 bit, little-endian, data-type-policy=OVERRIDE, base-type=uint8, compu {phys=raw}, range phys 0..255
          signal StatusUWBRangingFBD_VM_Sign06: start 240, 8 bit, little-endian, data-type-policy=OVERRIDE, base-type=uint8, compu {phys=raw}, range phys 0..255
          signal StatusUWBRangingFBD_VM_Sign07: start 248, 8 bit, little-endian, data-type-policy=OVERRIDE, base-type=uint8, compu {phys=raw}, range phys 0..255
      frame StatusUWBRangingFBD_VR: id 0x1B3, frame-length=32, can-addressing-mode=STANDARD, can-frame-rx-behavior=CAN-FD, can-frame-tx-behavior=CAN-FD
        pdu StatusUWBRangingFBD_VR: length=32, unused-bit-pattern=0
          signal StatusUWBRangingFBD_VR_SessionIDShort: start 0, 8 bit, little-endian, data-type-policy=OVERRIDE, base-type=uint8, compu {phys=raw}, range phys 0..252
          signal StatusUWBRangingFBD_VR_TimeOfFlight: start 8, 16 bit, little-endian, data-type-policy=OVERRIDE, base-type=uint16, compu {phys=raw*15.65; unit ps}, range phys 0..1000000
          signal StatusUWBRangingFBD_VR_RangingBlockIndex: start 24, 16 bit, little-endian, data-type-policy=OVERRIDE, base-type=uint16, compu {phys=raw}, range phys 0..65532
          signal StatusUWBRangingFBD_VR_RangingRoundIndex: start 40, 8 bit, little-endian, data-type-policy=OVERRIDE, base-type=uint8, compu {phys=raw}, range phys 0..252
          signal StatusUWBRangingFBD_VR_OverallReceivePower: start 48, 8 bit, little-endian, data-type-policy=OVERRIDE, base-type=uint8, compu {phys=raw*0.5-127; unit dB}, range phys -127..-1
          signal StatusUWBRangingFBD_VR_FirstPathPower: start 56, 8 bit, little-endian, data-type-policy=OVERRIDE, base-type=uint8, compu {phys=raw*0.5-127; unit dB}, range phys -127..-1
          signal StatusUWBRangingFBD_VR_AngleOfArrival: start 64, 8 bit, little-endian, data-type-policy=OVERRIDE, base-type=uint8, compu {phys=raw-90; unit °}, range phys -90..90
          signal StatusUWBRangingFBD_VR_PhaseDifferenceOfArrival: start 72, 8 bit, little-endian, data-type-policy=OVERRIDE, base-type=uint8, compu {phys=raw-90; unit °}, range phys -90..90
          signal StatusUWBRangingFBD_VR_StrongestPathPower: start 80, 8 bit, little-endian, data-type-policy=OVERRIDE, base-type=uint8, compu {phys=raw*0.5-127; unit dB}, range phys -127..-1
          signal StatusUWBRangingFBD_VR_BLE_RSSI: start 88, 8 bit, little-endian, data-type-policy=OVERRIDE, base-type=uint8, compu {phys=raw*0.5-127; unit dB}, range phys -127..-1
          signal StatusUWBRangingFBD_VR_StrongestPathOffset: start 96, 8 bit, little-endian, data-type-policy=OVERRIDE, base-type=uint8, compu {phys=raw*0.5; unit ns}, range phys 0..125
          signal StatusUWBRangingFBD_VR_PDoA_SNR: start 104, 8 bit, little-endian, data-type-policy=OVERRIDE, base-type=uint8, compu {phys=raw*0.5; unit dB}, range phys 0..126
          signal StatusUWBRangingFBD_VR_DutyCycleLimitTxCounter: start 112, 8 bit, little-endian, data-type-policy=OVERRIDE, base-type=uint8, compu {phys=raw; unit %}, range phys 0..100
          signal StatusUWBRangingFBD_VR_FinalDataDistribution: start 120, 4 bit, little-endian, data-type-policy=OVERRIDE, base-type=uint8, compu {phys=raw}, range phys 0..12
          signal StatusUWBRangingFBD_VR_Antenna: start 124, 4 bit, little-endian, data-type-policy=OVERRIDE, compu {phys=raw}
          signal StatusUWBRangingFBD_VR_Status1: start 128, 8 bit, little-endian, data-type-policy=OVERRIDE, compu {phys=raw}
          signal StatusUWBRangingFBD_VR_Status2: start 136, 8 bit, little-endian, data-type-policy=OVERRIDE, base-type=uint8, compu {phys=raw}, range phys 0..252
          signal StatusUWBRangingFBD_VR_Status3: start 144, 8 bit, little-endian, data-type-policy=OVERRIDE, base-type=uint8, compu {phys=raw}, range phys 0..252
          signal StatusUWBRangingFBD_VR_Status4: start 152, 8 bit, little-endian, data-type-policy=OVERRIDE, base-type=uint8, compu {phys=raw}, range phys 0..252
          signal StatusUWBRangingFBD_VR_IV00: start 160, 8 bit, little-endian, data-type-policy=OVERRIDE, base-type=uint8, compu {phys=raw}, range phys 0..255
          signal StatusUWBRangingFBD_VR_IV01: start 168, 8 bit, little-endian, data-type-policy=OVERRIDE, base-type=uint8, compu {phys=raw}, range phys 0..255
          signal StatusUWBRangingFBD_VR_IV02: start 176, 8 bit, little-endian, data-type-policy=OVERRIDE, base-type=uint8, compu {phys=raw}, range phys 0..255
          signal StatusUWBRangingFBD_VR_IV03: start 184, 8 bit, little-endian, data-type-policy=OVERRIDE, base-type=uint8, compu {phys=raw}, range phys 0..255
          signal StatusUWBRangingFBD_VR_Sign00: start 192, 8 bit, little-endian, data-type-policy=OVERRIDE, base-type=uint8, compu {phys=raw}, range phys 0..255
          signal StatusUWBRangingFBD_VR_Sign01: start 200, 8 bit, little-endian, data-type-policy=OVERRIDE, base-type=uint8, compu {phys=raw}, range phys 0..255
          signal StatusUWBRangingFBD_VR_Sign02: start 208, 8 bit, little-endian, data-type-policy=OVERRIDE, base-type=uint8, compu {phys=raw}, range phys 0..255
          signal StatusUWBRangingFBD_VR_Sign03: start 216, 8 bit, little-endian, data-type-policy=OVERRIDE, base-type=uint8, compu {phys=raw}, range phys 0..255
          signal StatusUWBRangingFBD_VR_Sign04: start 224, 8 bit, little-endian, data-type-policy=OVERRIDE, base-type=uint8, compu {phys=raw}, range phys 0..255
          signal StatusUWBRangingFBD_VR_Sign05: start 232, 8 bit, little-endian, data-type-policy=OVERRIDE, base-type=uint8, compu {phys=raw}, range phys 0..255
          signal StatusUWBRangingFBD_VR_Sign06: start 240, 8 bit, little-endian, data-type-policy=OVERRIDE, base-type=uint8, compu {phys=raw}, range phys 0..255
          signal StatusUWBRangingFBD_VR_Sign07: start 248, 8 bit, little-endian, data-type-policy=OVERRIDE, base-type=uint8, compu {phys=raw}, range phys 0..255
